VERSION ""

NS_ :

BS_:

BU_: AMP BCM DCSD DIAG_TEST DTV ECC EMCM ETM HCPM IPC LSMD LSMP LTM RRM TBM

BO_ 1985 ARCH_INFO: 4 BCM
 SG_ VehicleArchitectureInfo : 7|5@0+ (1,0) [0|31] "" ETM

BO_ 1884 BCM_IGNITION_ON_COUNTER: 2 BCM
 SG_ IgnitionOnCounter : 7|16@0+ (1,0) [0|65535] "-" AMP,DCSD,ECC,EMCM,ETM,HCPM,LSMD,LSMP,LTM,TBM

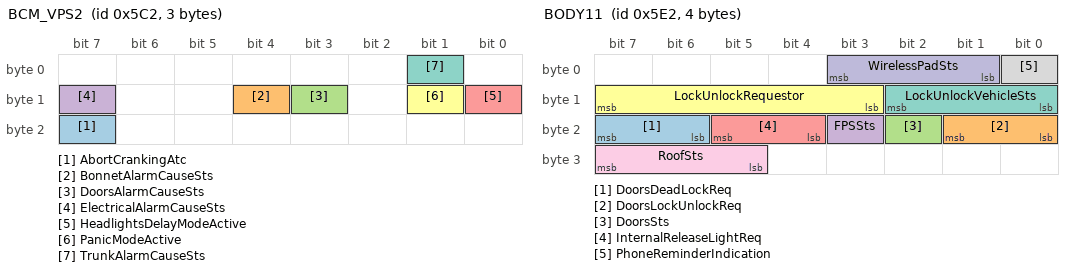
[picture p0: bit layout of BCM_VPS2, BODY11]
BO_ 1474 BCM_VPS2: 3 BCM
 SG_ AbortCrankingAtc : 23|1@0+ (1,0) [0|1] "-" TBM
 SG_ BonnetAlarmCauseSts : 12|1@0+ (1,0) [0|1] "-" IPC
 SG_ DoorsAlarmCauseSts : 11|1@0+ (1,0) [0|1] "-" IPC
 SG_ ElectricalAlarmCauseSts : 15|1@0+ (1,0) [0|1] "-" IPC
 SG_ HeadlightsDelayModeActive : 8|1@0+ (1,0) [0|1] "-" TBM
 SG_ PanicModeActive : 9|1@0+ (1,0) [0|1] "-" TBM
 SG_ TrunkAlarmCauseSts : 1|1@0+ (1,0) [0|1] "-" IPC

BO_ 1506 BODY11: 4 BCM
 SG_ DoorsDeadLockReq : 23|2@0+ (1,0) [0|3] "-" LSMD,LSMP
 SG_ DoorsLockUnlockReq : 17|2@0+ (1,0) [0|3] "-" LSMD,LSMP
 SG_ DoorsSts : 18|1@0+ (1,0) [0|1] "-" LSMD,LSMP
 SG_ FPSSts : 19|1@0+ (1,0) [0|1] "-" LSMD,LSMP
 SG_ InternalReleaseLightReq : 21|2@0+ (1,0) [0|3] "-" LSMD,LSMP
 SG_ LockUnlockRequestor : 15|5@0+ (1,0) [0|31] "-" LSMD,LSMP
 SG_ LockUnlockVehicleSts : 10|3@0+ (1,0) [0|7] "-" TBM
 SG_ PhoneReminderIndication : 0|1@0+ (1,0) [0|1] "-" IPC
 SG_ RoofSts : 31|3@0+ (1,0) [0|7] "-" ECC,TBM
 SG_ WirelessPadSts : 3|3@0+ (1,0) [0|6] "-" Vector__XXX

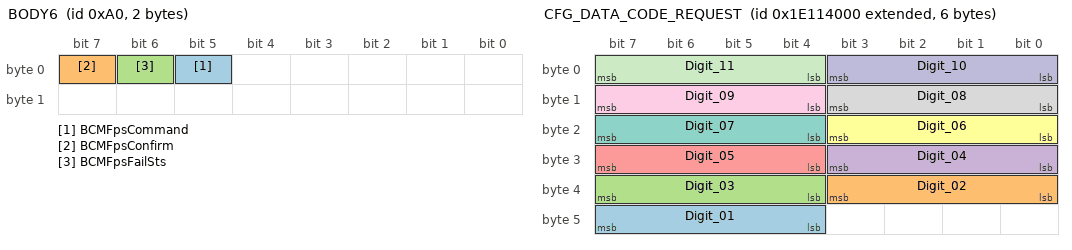
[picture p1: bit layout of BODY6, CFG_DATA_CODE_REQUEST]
BO_ 160 BODY6: 2 BCM
 SG_ BCMFpsCommand : 5|1@0+ (1,0) [0|1] "-" ECC
 SG_ BCMFpsConfirm : 7|1@0+ (1,0) [0|1] "-" ECC
 SG_ BCMFpsFailSts : 6|1@0+ (1,0) [0|1] "-" ECC,LSMD,LSMP

BO_ 2651930624 CFG_DATA_CODE_REQUEST: 6 BCM
 SG_ Digit_01 : 47|4@0+ (1,0) [0|15] "" AMP,ECC,EMCM,ETM,HCPM,LSMD,LSMP,LTM
 SG_ Digit_02 : 35|4@0+ (1,0) [0|15] "" AMP,ECC,EMCM,ETM,HCPM,LSMD,LSMP,LTM
 SG_ Digit_03 : 39|4@0+ (1,0) [0|15] "" AMP,ECC,EMCM,ETM,HCPM,LSMD,LSMP,LTM
 SG_ Digit_04 : 27|4@0+ (1,0) [0|15] "" AMP,ECC,EMCM,ETM,HCPM,LSMD,LSMP,LTM
 SG_ Digit_05 : 31|4@0+ (1,0) [0|15] "" AMP,ECC,EMCM,ETM,HCPM,LSMD,LSMP,LTM
 SG_ Digit_06 : 19|4@0+ (1,0) [0|15] "" AMP,ECC,EMCM,ETM,HCPM,LSMD,LSMP,LTM
 SG_ Digit_07 : 23|4@0+ (1,0) [0|15] "" AMP,ECC,EMCM,ETM,HCPM,LSMD,LSMP,LTM
 SG_ Digit_08 : 11|4@0+ (1,0) [0|15] "" AMP,ECC,EMCM,ETM,HCPM,LSMD,LSMP,LTM
 SG_ Digit_09 : 15|4@0+ (1,0) [0|15] "" AMP,ECC,EMCM,ETM,HCPM,LSMD,LSMP,LTM
 SG_ Digit_10 : 3|4@0+ (1,0) [0|15] "" AMP,ECC,EMCM,ETM,HCPM,LSMD,LSMP,LTM
 SG_ Digit_11 : 7|4@0+ (1,0) [0|15] "" AMP,ECC,EMCM,ETM,HCPM,LSMD,LSMP,LTM

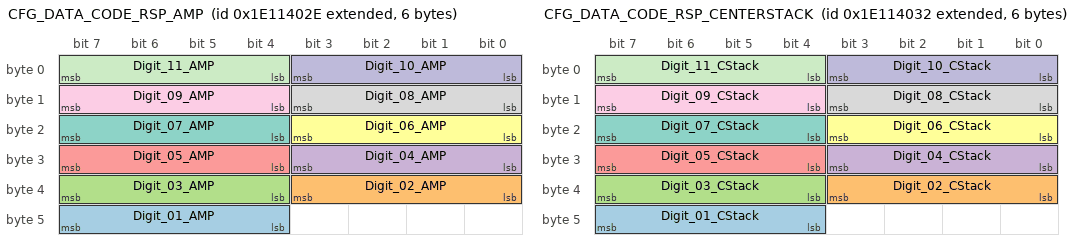
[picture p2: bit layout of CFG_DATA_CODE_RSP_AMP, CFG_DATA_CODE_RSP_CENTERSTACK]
BO_ 2651930670 CFG_DATA_CODE_RSP_AMP: 6 AMP
 SG_ Digit_01_AMP : 47|4@0+ (1,0) [0|15] "-" BCM
 SG_ Digit_02_AMP : 35|4@0+ (1,0) [0|15] "-" BCM
 SG_ Digit_03_AMP : 39|4@0+ (1,0) [0|15] "-" BCM
 SG_ Digit_04_AMP : 27|4@0+ (1,0) [0|15] "-" BCM
 SG_ Digit_05_AMP : 31|4@0+ (1,0) [0|15] "-" BCM
 SG_ Digit_06_AMP : 19|4@0+ (1,0) [0|15] "-" BCM
 SG_ Digit_07_AMP : 23|4@0+ (1,0) [0|15] "-" BCM
 SG_ Digit_08_AMP : 11|4@0+ (1,0) [0|15] "-" BCM
 SG_ Digit_09_AMP : 15|4@0+ (1,0) [0|15] "-" BCM
 SG_ Digit_10_AMP : 3|4@0+ (1,0) [0|15] "-" BCM
 SG_ Digit_11_AMP : 7|4@0+ (1,0) [0|15] "-" BCM

BO_ 2651930674 CFG_DATA_CODE_RSP_CENTERSTACK: 6 HCPM
 SG_ Digit_01_CStack : 47|4@0+ (1,0) [0|15] "-" BCM
 SG_ Digit_02_CStack : 35|4@0+ (1,0) [0|15] "-" BCM
 SG_ Digit_03_CStack : 39|4@0+ (1,0) [0|15] "-" BCM
 SG_ Digit_04_CStack : 27|4@0+ (1,0) [0|15] "-" BCM
 SG_ Digit_05_CStack : 31|4@0+ (1,0) [0|15] "-" BCM
 SG_ Digit_06_CStack : 19|4@0+ (1,0) [0|15] "-" BCM
 SG_ Digit_07_CStack : 23|4@0+ (1,0) [0|15] "-" BCM
 SG_ Digit_08_CStack : 11|4@0+ (1,0) [0|15] "-" BCM
 SG_ Digit_09_CStack : 15|4@0+ (1,0) [0|15] "-" BCM
 SG_ Digit_10_CStack : 3|4@0+ (1,0) [0|15] "-" BCM
 SG_ Digit_11_CStack : 7|4@0+ (1,0) [0|15] "-" BCM

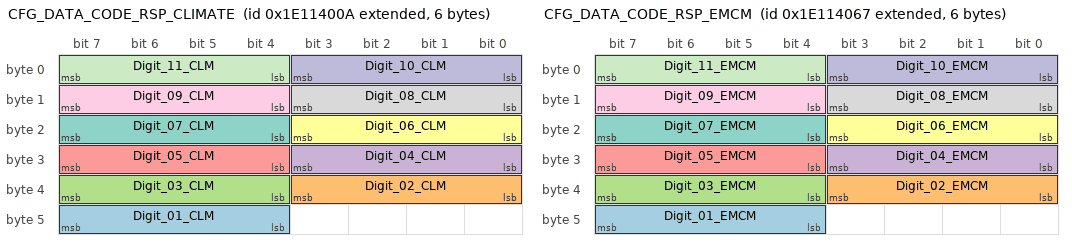
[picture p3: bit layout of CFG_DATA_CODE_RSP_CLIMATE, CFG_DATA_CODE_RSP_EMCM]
BO_ 2651930634 CFG_DATA_CODE_RSP_CLIMATE: 6 ECC
 SG_ Digit_01_CLM : 47|4@0+ (1,0) [0|15] "-" BCM
 SG_ Digit_02_CLM : 35|4@0+ (1,0) [0|15] "-" BCM
 SG_ Digit_03_CLM : 39|4@0+ (1,0) [0|15] "-" BCM
 SG_ Digit_04_CLM : 27|4@0+ (1,0) [0|15] "-" BCM
 SG_ Digit_05_CLM : 31|4@0+ (1,0) [0|15] "-" BCM
 SG_ Digit_06_CLM : 19|4@0+ (1,0) [0|15] "-" BCM
 SG_ Digit_07_CLM : 23|4@0+ (1,0) [0|15] "-" BCM
 SG_ Digit_08_CLM : 11|4@0+ (1,0) [0|15] "-" BCM
 SG_ Digit_09_CLM : 15|4@0+ (1,0) [0|15] "-" BCM
 SG_ Digit_10_CLM : 3|4@0+ (1,0) [0|15] "-" BCM
 SG_ Digit_11_CLM : 7|4@0+ (1,0) [0|15] "-" BCM

BO_ 2651930727 CFG_DATA_CODE_RSP_EMCM: 6 EMCM
 SG_ Digit_01_EMCM : 47|4@0+ (1,0) [0|15] "-" BCM
 SG_ Digit_02_EMCM : 35|4@0+ (1,0) [0|15] "-" BCM
 SG_ Digit_03_EMCM : 39|4@0+ (1,0) [0|15] "-" BCM
 SG_ Digit_04_EMCM : 27|4@0+ (1,0) [0|15] "-" BCM
 SG_ Digit_05_EMCM : 31|4@0+ (1,0) [0|15] "-" BCM
 SG_ Digit_06_EMCM : 19|4@0+ (1,0) [0|15] "-" BCM
 SG_ Digit_07_EMCM : 23|4@0+ (1,0) [0|15] "-" BCM
 SG_ Digit_08_EMCM : 11|4@0+ (1,0) [0|15] "-" BCM
 SG_ Digit_09_EMCM : 15|4@0+ (1,0) [0|15] "-" BCM
 SG_ Digit_10_EMCM : 3|4@0+ (1,0) [0|15] "-" BCM
 SG_ Digit_11_EMCM : 7|4@0+ (1,0) [0|15] "-" BCM

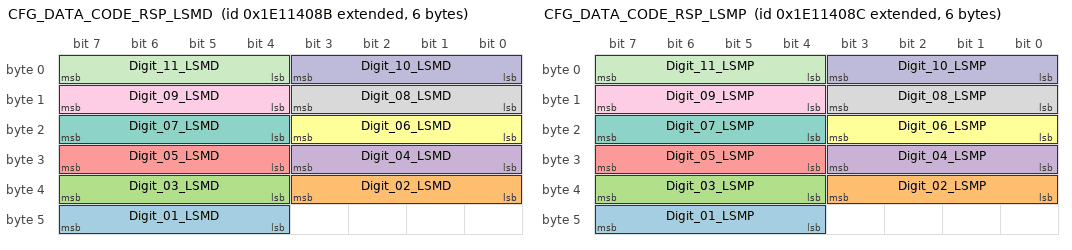
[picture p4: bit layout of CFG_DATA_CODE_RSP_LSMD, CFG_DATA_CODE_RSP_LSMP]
BO_ 2651930763 CFG_DATA_CODE_RSP_LSMD: 6 LSMD
 SG_ Digit_01_LSMD : 47|4@0+ (1,0) [0|15] "-" BCM
 SG_ Digit_02_LSMD : 35|4@0+ (1,0) [0|15] "-" BCM
 SG_ Digit_03_LSMD : 39|4@0+ (1,0) [0|15] "-" BCM
 SG_ Digit_04_LSMD : 27|4@0+ (1,0) [0|15] "-" BCM
 SG_ Digit_05_LSMD : 31|4@0+ (1,0) [0|15] "-" BCM
 SG_ Digit_06_LSMD : 19|4@0+ (1,0) [0|15] "-" BCM
 SG_ Digit_07_LSMD : 23|4@0+ (1,0) [0|15] "-" BCM
 SG_ Digit_08_LSMD : 11|4@0+ (1,0) [0|15] "-" BCM
 SG_ Digit_09_LSMD : 15|4@0+ (1,0) [0|15] "-" BCM
 SG_ Digit_10_LSMD : 3|4@0+ (1,0) [0|15] "-" BCM
 SG_ Digit_11_LSMD : 7|4@0+ (1,0) [0|15] "-" BCM

BO_ 2651930764 CFG_DATA_CODE_RSP_LSMP: 6 LSMP
 SG_ Digit_01_LSMP : 47|4@0+ (1,0) [0|15] "-" BCM
 SG_ Digit_02_LSMP : 35|4@0+ (1,0) [0|15] "-" BCM
 SG_ Digit_03_LSMP : 39|4@0+ (1,0) [0|15] "-" BCM
 SG_ Digit_04_LSMP : 27|4@0+ (1,0) [0|15] "-" BCM
 SG_ Digit_05_LSMP : 31|4@0+ (1,0) [0|15] "-" BCM
 SG_ Digit_06_LSMP : 19|4@0+ (1,0) [0|15] "-" BCM
 SG_ Digit_07_LSMP : 23|4@0+ (1,0) [0|15] "-" BCM
 SG_ Digit_08_LSMP : 11|4@0+ (1,0) [0|15] "-" BCM
 SG_ Digit_09_LSMP : 15|4@0+ (1,0) [0|15] "-" BCM
 SG_ Digit_10_LSMP : 3|4@0+ (1,0) [0|15] "-" BCM
 SG_ Digit_11_LSMP : 7|4@0+ (1,0) [0|15] "-" BCM

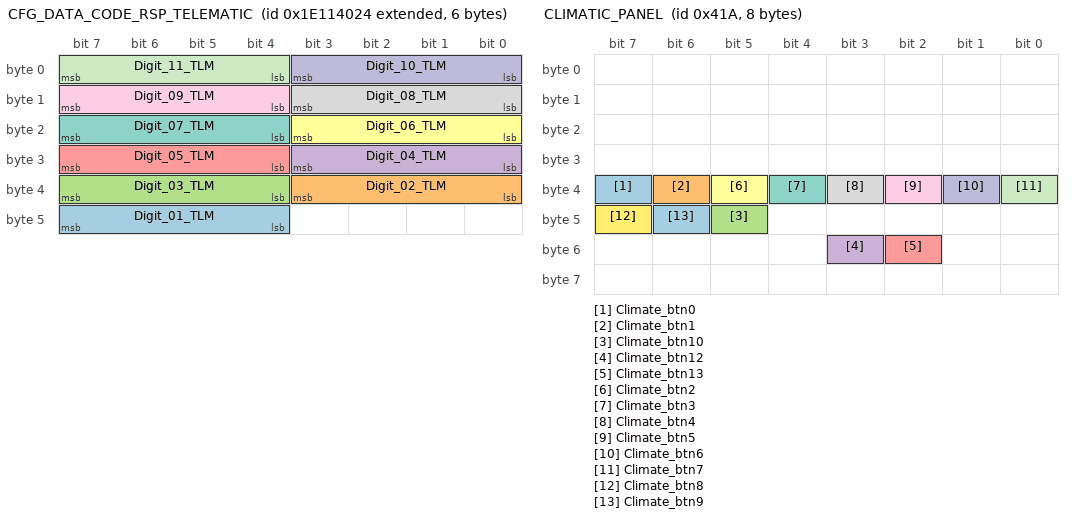
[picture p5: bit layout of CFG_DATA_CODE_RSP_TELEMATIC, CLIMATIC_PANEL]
BO_ 2651930660 CFG_DATA_CODE_RSP_TELEMATIC: 6 ETM
 SG_ Digit_01_TLM : 47|4@0+ (1,0) [0|15] "-" BCM
 SG_ Digit_02_TLM : 35|4@0+ (1,0) [0|15] "-" BCM
 SG_ Digit_03_TLM : 39|4@0+ (1,0) [0|15] "-" BCM
 SG_ Digit_04_TLM : 27|4@0+ (1,0) [0|15] "-" BCM
 SG_ Digit_05_TLM : 31|4@0+ (1,0) [0|15] "-" BCM
 SG_ Digit_06_TLM : 19|4@0+ (1,0) [0|15] "-" BCM
 SG_ Digit_07_TLM : 23|4@0+ (1,0) [0|15] "-" BCM
 SG_ Digit_08_TLM : 11|4@0+ (1,0) [0|15] "-" BCM
 SG_ Digit_09_TLM : 15|4@0+ (1,0) [0|15] "-" BCM
 SG_ Digit_10_TLM : 3|4@0+ (1,0) [0|15] "-" BCM
 SG_ Digit_11_TLM : 7|4@0+ (1,0) [0|15] "-" BCM

BO_ 134 CLIMATE_REQ: 2 ECC
 SG_ FPS_Status_Request : 7|1@0+ (1,0) [0|1] "-" BCM

BO_ 1050 CLIMATIC_PANEL: 8 HCPM
 SG_ Climate_btn0 : 39|1@0+ (1,0) [0|1] "" ECC
 SG_ Climate_btn1 : 38|1@0+ (1,0) [0|1] "" ECC
 SG_ Climate_btn10 : 45|1@0+ (1,0) [0|1] "" ECC
 SG_ Climate_btn12 : 51|1@0+ (1,0) [0|1] "" ECC
 SG_ Climate_btn13 : 50|1@0+ (1,0) [0|1] "" ECC
 SG_ Climate_btn2 : 37|1@0+ (1,0) [0|1] "" ECC
 SG_ Climate_btn3 : 36|1@0+ (1,0) [0|1] "" ECC
 SG_ Climate_btn4 : 35|1@0+ (1,0) [0|1] "" ECC
 SG_ Climate_btn5 : 34|1@0+ (1,0) [0|1] "" ECC
 SG_ Climate_btn6 : 33|1@0+ (1,0) [0|1] "" ECC
 SG_ Climate_btn7 : 32|1@0+ (1,0) [0|1] "" ECC
 SG_ Climate_btn8 : 47|1@0+ (1,0) [0|1] "" ECC
 SG_ Climate_btn9 : 46|1@0+ (1,0) [0|1] "" ECC

BO_ 224 CLUSTER5: 4 IPC
 SG_ DisplayedSpeedSign : 7|8@0+ (1,0) [0|255] "-" ETM

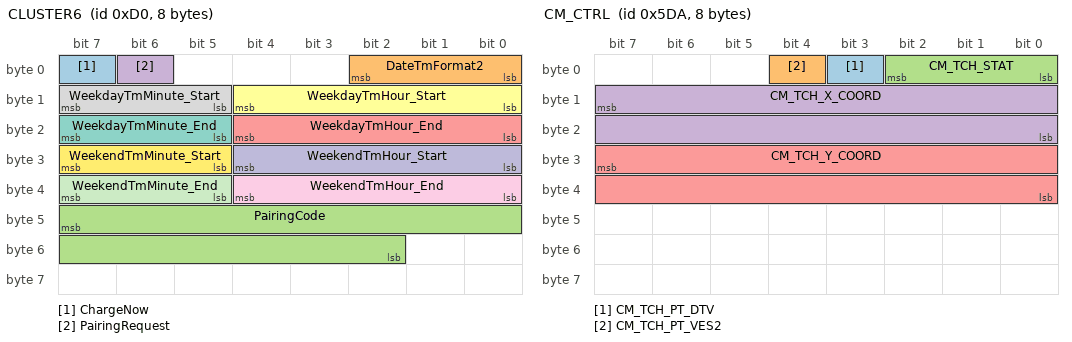
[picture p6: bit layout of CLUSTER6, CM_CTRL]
BO_ 208 CLUSTER6: 8 IPC
 SG_ ChargeNow : 7|1@0+ (1,0) [0|1] "" BCM
 SG_ DateTmFormat2 : 2|3@0+ (1,0) [0|6] "" Vector__XXX
 SG_ PairingCode : 47|14@0+ (1,0) [0|16383] "" RRM
 SG_ PairingRequest : 6|1@0+ (1,0) [0|1] "" RRM
 SG_ WeekdayTmHour_End : 20|5@0+ (1,0) [0|24] "Hours" RRM
 SG_ WeekdayTmHour_Start : 12|5@0+ (1,0) [0|24] "Hours" RRM
 SG_ WeekdayTmMinute_End : 23|3@0+ (1,0) [0|6] "Min" RRM
 SG_ WeekdayTmMinute_Start : 15|3@0+ (1,0) [0|6] "Min" RRM
 SG_ WeekendTmHour_End : 36|5@0+ (1,0) [0|24] "Hours" RRM
 SG_ WeekendTmHour_Start : 28|5@0+ (1,0) [0|24] "Hours" RRM
 SG_ WeekendTmMinute_End : 39|3@0+ (1,0) [0|6] "" RRM
 SG_ WeekendTmMinute_Start : 31|3@0+ (1,0) [0|6] "Min" RRM

BO_ 1498 CM_CTRL: 8 ETM
 SG_ CM_TCH_PT_DTV : 3|1@0+ (1,0) [0|1] "" DTV
 SG_ CM_TCH_PT_VES2 : 4|1@0+ (1,0) [0|1] "" Vector__XXX
 SG_ CM_TCH_STAT : 2|3@0+ (1,0) [0|6] "" DTV
 SG_ CM_TCH_X_COORD : 15|16@0+ (1,0) [0|65535] "" DTV
 SG_ CM_TCH_Y_COORD : 31|16@0+ (1,0) [0|65535] "" DTV

BO_ 177 CONNECTIVITY_VEHICLE_SETUP2: 8 TBM
 SG_ PowerLevel_External_Req : 7|3@0+ (1,0) [0|7] "-" IPC
 SG_ RemStNrmlStEnbl_External_Req : 4|2@0+ (1,0) [0|3] "-" IPC

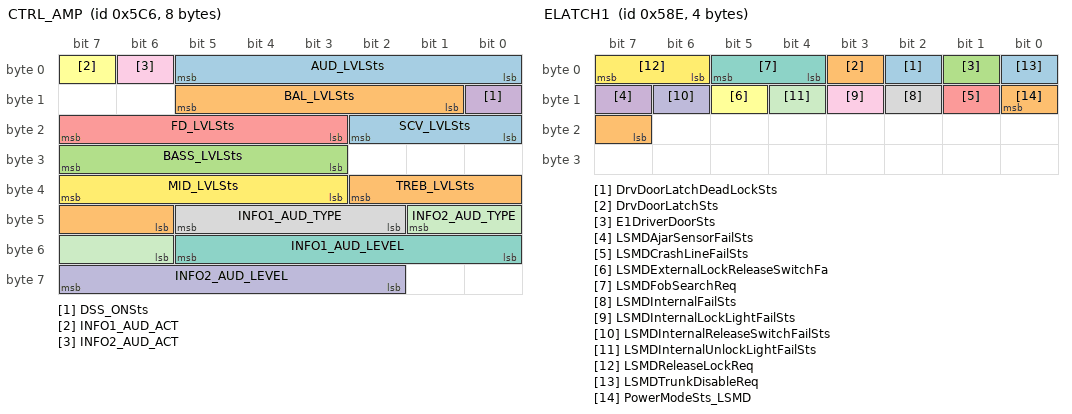
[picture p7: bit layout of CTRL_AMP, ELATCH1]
BO_ 1478 CTRL_AMP: 8 ETM
 SG_ AUD_LVLSts : 5|6@0+ (1,0) [0|63] "" AMP,TBM
 SG_ BAL_LVLSts : 13|5@0+ (1,0) [0|31] "" AMP
 SG_ BASS_LVLSts : 31|5@0+ (1,0) [0|31] "" AMP
 SG_ DSS_ONSts : 8|1@0+ (1,0) [0|1] "" AMP
 SG_ FD_LVLSts : 23|5@0+ (1,0) [0|31] "" AMP
 SG_ INFO1_AUD_ACT : 7|1@0+ (1,0) [0|1] "" AMP
 SG_ INFO1_AUD_LEVEL : 53|6@0+ (1,0) [0|63] "" AMP,TBM
 SG_ INFO1_AUD_TYPE : 45|4@0+ (1,0) [0|15] "" AMP
 SG_ INFO2_AUD_ACT : 6|1@0+ (1,0) [0|1] "" AMP
 SG_ INFO2_AUD_LEVEL : 63|6@0+ (1,0) [0|63] "" AMP,TBM
 SG_ INFO2_AUD_TYPE : 41|4@0+ (1,0) [0|15] "" AMP
 SG_ MID_LVLSts : 39|5@0+ (1,0) [0|31] "" AMP
 SG_ SCV_LVLSts : 18|3@0+ (1,0) [0|6] "" AMP
 SG_ TREB_LVLSts : 34|5@0+ (1,0) [0|31] "" AMP

BO_ 2564554481 DIAGNOSTIC_REQ_FUNC_BH_C2: 8 DIAG_TEST
 SG_ N_PDU : 7|64@0+ (1,0) [0|0] "" AMP,BCM,DCSD,ECC,EMCM,ETM,HCPM,LSMD,LSMP,LTM

BO_ 2564457457 DIAGNOSTIC_REQUEST_AMP: 8 BCM
 SG_ N_PDU : 7|64@0+ (1,0) [0|0] "" AMP,TBM

BO_ 2564457969 DIAGNOSTIC_REQUEST_CENTERSTACK: 8 BCM
 SG_ N_PDU : 7|64@0+ (1,0) [0|0] "" HCPM,TBM

BO_ 2564462833 DIAGNOSTIC_REQUEST_CLIMATE: 8 BCM
 SG_ N_PDU : 7|64@0+ (1,0) [0|0] "" ECC,TBM

BO_ 2564451057 DIAGNOSTIC_REQUEST_DCSD: 8 BCM
 SG_ N_PDU : 7|64@0+ (1,0) [0|0] "" DCSD,TBM

BO_ 2564479473 DIAGNOSTIC_REQUEST_EMCM: 8 BCM
 SG_ N_PDU : 7|64@0+ (1,0) [0|0] "" EMCM,TBM

BO_ 2564445425 DIAGNOSTIC_REQUEST_LSMD: 8 BCM
 SG_ N_PDU : 7|64@0+ (1,0) [0|0] "" LSMD,TBM

BO_ 2564445681 DIAGNOSTIC_REQUEST_LSMP: 8 BCM
 SG_ N_PDU : 7|64@0+ (1,0) [0|0] "" LSMP,TBM

BO_ 2564458481 DIAGNOSTIC_REQUEST_TELEMATIC: 8 BCM
 SG_ N_PDU : 7|64@0+ (1,0) [0|0] "" ETM,LTM,TBM

BO_ 2564485507 DIAGNOSTIC_RESPONSE_AMP: 8 AMP
 SG_ N_PDU : 7|64@0+ (1,0) [0|0] "-" BCM,DIAG_TEST,TBM

BO_ 2564485509 DIAGNOSTIC_RESPONSE_CENTERSTACK: 8 HCPM
 SG_ N_PDU : 7|64@0+ (1,0) [0|0] "-" BCM,DIAG_TEST,TBM

BO_ 2564485528 DIAGNOSTIC_RESPONSE_CLIMATE: 8 ECC
 SG_ N_PDU : 7|64@0+ (1,0) [0|0] "" BCM,DIAG_TEST,TBM

BO_ 2564485482 DIAGNOSTIC_RESPONSE_DCSD: 8 DCSD
 SG_ N_PDU : 7|64@0+ (1,0) [0|0] "-" BCM,DIAG_TEST,TBM

BO_ 2564485593 DIAGNOSTIC_RESPONSE_EMCM: 8 EMCM
 SG_ N_PDU : 7|64@0+ (1,0) [0|0] "-" BCM,DIAG_TEST,TBM

BO_ 2564485460 DIAGNOSTIC_RESPONSE_LSMD: 8 LSMD
 SG_ N_PDU : 7|64@0+ (1,0) [0|0] "" BCM,DIAG_TEST,TBM

BO_ 2564485461 DIAGNOSTIC_RESPONSE_LSMP: 8 LSMP
 SG_ N_PDU : 7|64@0+ (1,0) [0|0] "" BCM,DIAG_TEST,TBM

BO_ 2564485511 DIAGNOSTIC_RESPONSE_TELEMATIC: 8 ETM
 SG_ N_PDU : 7|64@0+ (1,0) [0|0] "" BCM,DIAG_TEST,TBM

BO_ 1445 DIS_CENTERSTACK: 8 DCSD
 SG_ DCSD_DISP_STAT : 7|3@0+ (1,0) [0|6] "" ETM,LTM

BO_ 1422 ELATCH1: 4 LSMD
 SG_ DrvDoorLatchDeadLockSts : 2|1@0+ (1,0) [0|1] "" BCM
 SG_ DrvDoorLatchSts : 3|1@0+ (1,0) [0|1] "" BCM,TBM
 SG_ E1DriverDoorSts : 1|1@0+ (1,0) [0|1] "" BCM,ECC,ETM,IPC,LTM,RRM,TBM
 SG_ LSMDAjarSensorFailSts : 15|1@0+ (1,0) [0|1] "" BCM,ECC,IPC,TBM
 SG_ LSMDCrashLineFailSts : 9|1@0+ (1,0) [0|1] "" BCM,IPC
 SG_ LSMDExternalLockReleaseSwitchFa : 13|1@0+ (1,0) [0|1] "" BCM
 SG_ LSMDFobSearchReq : 5|2@0+ (1,0) [0|3] "" BCM
 SG_ LSMDInternalFailSts : 10|1@0+ (1,0) [0|1] "" BCM,ECC,IPC,TBM
 SG_ LSMDInternalLockLightFailSts : 11|1@0+ (1,0) [0|1] "" BCM
 SG_ LSMDInternalReleaseSwitchFailSts : 14|1@0+ (1,0) [0|1] "" BCM
 SG_ LSMDInternalUnlockLightFailSts : 12|1@0+ (1,0) [0|1] "" BCM
 SG_ LSMDReleaseLockReq : 7|2@0+ (1,0) [0|3] "" BCM
 SG_ LSMDTrunkDisableReq : 0|1@0+ (1,0) [0|1] "" BCM
 SG_ PowerModeSts_LSMD : 8|2@0+ (1,0) [0|3] "" BCM

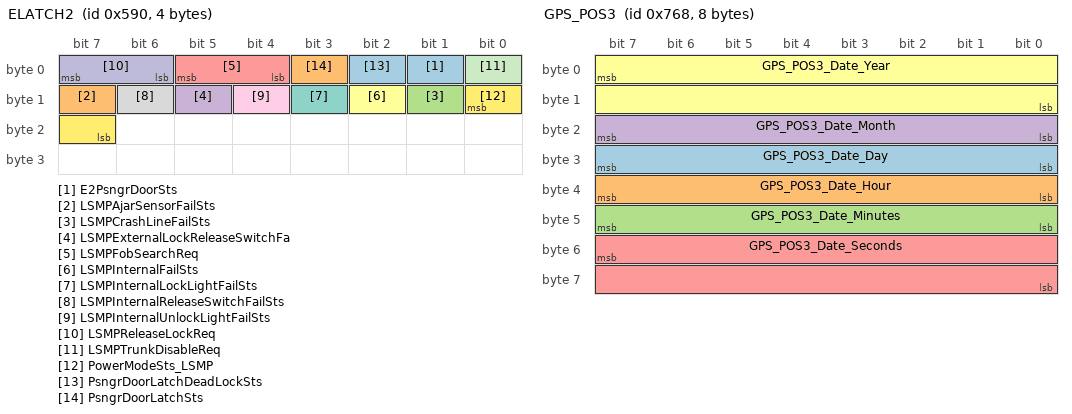
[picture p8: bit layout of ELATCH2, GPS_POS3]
BO_ 1424 ELATCH2: 4 LSMP
 SG_ E2PsngrDoorSts : 1|1@0+ (1,0) [0|1] "" BCM,ECC,ETM,IPC,LTM,RRM,TBM
 SG_ LSMPAjarSensorFailSts : 15|1@0+ (1,0) [0|1] "" BCM,ECC,IPC,TBM
 SG_ LSMPCrashLineFailSts : 9|1@0+ (1,0) [0|1] "" BCM,IPC
 SG_ LSMPExternalLockReleaseSwitchFa : 13|1@0+ (1,0) [0|1] "" BCM
 SG_ LSMPFobSearchReq : 5|2@0+ (1,0) [0|3] "" BCM
 SG_ LSMPInternalFailSts : 10|1@0+ (1,0) [0|1] "" BCM,ECC,IPC,TBM
 SG_ LSMPInternalLockLightFailSts : 11|1@0+ (1,0) [0|1] "" BCM
 SG_ LSMPInternalReleaseSwitchFailSts : 14|1@0+ (1,0) [0|1] "" BCM
 SG_ LSMPInternalUnlockLightFailSts : 12|1@0+ (1,0) [0|1] "" BCM
 SG_ LSMPReleaseLockReq : 7|2@0+ (1,0) [0|3] "" BCM
 SG_ LSMPTrunkDisableReq : 0|1@0+ (1,0) [0|1] "" BCM
 SG_ PowerModeSts_LSMP : 8|2@0+ (1,0) [0|3] "" BCM
 SG_ PsngrDoorLatchDeadLockSts : 2|1@0+ (1,0) [0|1] "" BCM
 SG_ PsngrDoorLatchSts : 3|1@0+ (1,0) [0|1] "" BCM,TBM

BO_ 852 EXTERNAL_LIGHTS: 4 BCM
 SG_ AHBFeature : 19|1@0+ (1,0) [0|1] "-" IPC
 SG_ AlertLightsON : 31|1@0+ (1,0) [0|1] "-" IPC
 SG_ DRLFault : 6|1@0+ (1,0) [0|1] "-" IPC,TBM
 SG_ FHeatedWindowSts : 5|1@0+ (1,0) [0|1] "-" ECC
 SG_ FollowMeHomeReqSts : 28|1@0+ (1,0) [0|1] "-" IPC
 SG_ FrontFogLightSts : 4|1@0+ (1,0) [0|1] "-" IPC,RRM,TBM
 SG_ HeatedMirrorSts : 3|1@0+ (1,0) [0|1] "-" TBM
 SG_ HighBeamSts : 2|1@0+ (1,0) [0|1] "-" IPC
 SG_ L_TurnLightActivationSts : 17|1@0+ (1,0) [0|1] "-" Vector__XXX
 SG_ LHParkingLightSts : 1|1@0+ (1,0) [0|1] "-" ETM,IPC,LTM
 SG_ LHTurnLightFault : 0|1@0+ (1,0) [0|1] "-" IPC,TBM
 SG_ LHTurnSignalSts : 15|1@0+ (1,0) [0|1] "-" IPC,TBM
 SG_ LowBeamSts : 14|1@0+ (1,0) [0|1] "-" ETM,IPC,LTM
 SG_ ParkingLightFault : 13|1@0+ (1,0) [0|1] "-" IPC
 SG_ PlateLightFault : 12|1@0+ (1,0) [0|1] "-" IPC,TBM
 SG_ R_TurnLightActivationSts : 16|1@0+ (1,0) [0|1] "-" Vector__XXX
 SG_ RearFogLightFault : 11|1@0+ (1,0) [0|1] "-" IPC
 SG_ RearFogLightSts : 10|1@0+ (1,0) [0|1] "-" IPC,TBM
 SG_ ReverseGearLightFault : 9|1@0+ (1,0) [0|1] "-" IPC,TBM
 SG_ RHeatedWindowSts : 8|1@0+ (1,0) [0|1] "-" ECC,TBM
 SG_ RHParkingLightSts : 23|1@0+ (1,0) [0|1] "-" ETM,IPC,LTM
 SG_ RHTurnLightFault : 22|1@0+ (1,0) [0|1] "-" IPC,TBM
 SG_ RHTurnSignalSts : 21|1@0+ (1,0) [0|1] "-" IPC,TBM
 SG_ StopLightFault : 20|1@0+ (1,0) [0|1] "-" IPC,TBM
 SG_ StopLightSts : 18|1@0+ (1,0) [0|1] "-" Vector__XXX

BO_ 128 FOTA_TBM: 4 TBM
 SG_ UpdateSts : 7|3@0+ (1,0) [0|7] "" BCM,ETM,IPC,LTM

BO_ 1896 GPS_POS3: 8 ETM
 SG_ GPS_POS3_Date_Day : 31|8@0+ (1,0) [1|31] "days" BCM
 SG_ GPS_POS3_Date_Hour : 39|8@0+ (1,0) [0|23] "hours" BCM
 SG_ GPS_POS3_Date_Minutes : 47|8@0+ (1,0) [0|59] "minutes" BCM
 SG_ GPS_POS3_Date_Month : 23|8@0+ (1,0) [1|12] "months" BCM
 SG_ GPS_POS3_Date_Seconds : 55|16@0+ (0.01,0) [0|59.99] "seconds" BCM
 SG_ GPS_POS3_Date_Year : 7|16@0+ (1,0) [0|65534] "years" BCM

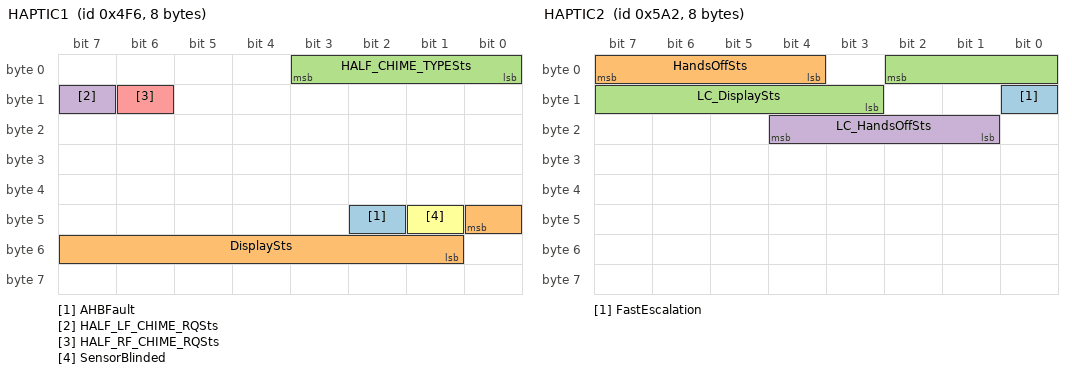
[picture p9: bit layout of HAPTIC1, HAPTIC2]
BO_ 1270 HAPTIC1: 8 BCM
 SG_ AHBFault : 42|1@0+ (1,0) [0|1] "" IPC
 SG_ DisplaySts : 40|8@0+ (1,0) [0|255] "-" IPC,TBM
 SG_ HALF_CHIME_TYPESts : 3|4@0+ (1,0) [0|15] "-" AMP,ETM,LTM,TBM
 SG_ HALF_LF_CHIME_RQSts : 15|1@0+ (1,0) [0|1] "-" AMP,ETM,LTM,TBM
 SG_ HALF_RF_CHIME_RQSts : 14|1@0+ (1,0) [0|1] "-" AMP,ETM,LTM,TBM
 SG_ SensorBlinded : 41|1@0+ (1,0) [0|1] "" IPC

BO_ 1442 HAPTIC2: 8 BCM
 SG_ FastEscalation : 8|1@0+ (1,0) [0|1] "-" IPC
 SG_ HandsOffSts : 7|4@0+ (1,0) [0|15] "-" IPC
 SG_ LC_DisplaySts : 2|8@0+ (1,0) [0|255] "-" IPC
 SG_ LC_HandsOffSts : 20|4@0+ (1,0) [0|15] "-" IPC

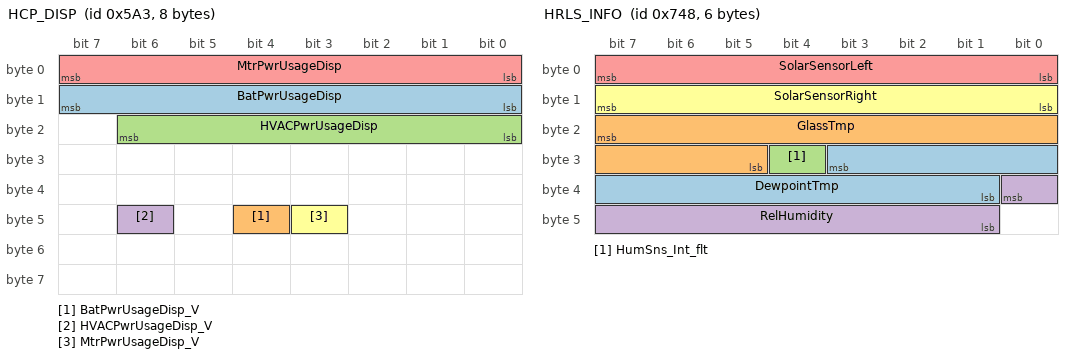
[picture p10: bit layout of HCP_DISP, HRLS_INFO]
BO_ 1443 HCP_DISP: 8 BCM
 SG_ BatPwrUsageDisp : 15|8@0+ (1,-125) [-125|130] "kW" RRM
 SG_ BatPwrUsageDisp_V : 44|1@0+ (1,0) [0|1] "" RRM
 SG_ HVACPwrUsageDisp : 22|7@0+ (1,0) [0|127] "kW" RRM
 SG_ HVACPwrUsageDisp_V : 46|1@0+ (1,0) [0|1] "" RRM
 SG_ MtrPwrUsageDisp : 7|8@0+ (1,-125) [-125|130] "kW" RRM
 SG_ MtrPwrUsageDisp_V : 43|1@0+ (1,0) [0|1] "" RRM

BO_ 2147583473 HP_DIAGNOSTIC_REQST_CNTRSTCK: 8 BCM
 SG_ N_PDU : 7|64@0+ (1,0) [0|0] "" HCPM

BO_ 2147582961 HP_DIAGNOSTIC_REQUEST_AMP: 8 BCM
 SG_ N_PDU : 7|64@0+ (1,0) [0|0] "" AMP

BO_ 2147588337 HP_DIAGNOSTIC_REQUEST_CLIMATE: 8 BCM
 SG_ N_PDU : 7|64@0+ (1,0) [0|0] "" ECC

BO_ 2147576561 HP_DIAGNOSTIC_REQUEST_DCSD: 8 BCM
 SG_ N_PDU : 7|64@0+ (1,0) [0|0] "" DCSD

BO_ 2147584753 HP_DIAGNOSTIC_REQUEST_EMCM: 8 BCM
 SG_ N_PDU : 7|64@0+ (1,0) [0|0] "" EMCM

BO_ 2147570929 HP_DIAGNOSTIC_REQUEST_LSMD: 8 BCM
 SG_ N_PDU : 7|64@0+ (1,0) [0|0] "" LSMD

BO_ 2147571185 HP_DIAGNOSTIC_REQUEST_LSMP: 8 BCM
 SG_ N_PDU : 7|64@0+ (1,0) [0|0] "" LSMP

BO_ 2147583985 HP_DIAGNOSTIC_REQUEST_TELEMATIC: 8 BCM
 SG_ N_PDU : 7|64@0+ (1,0) [0|0] "" LTM

BO_ 1864 HRLS_INFO: 6 BCM
 SG_ DewpointTmp : 27|11@0+ (0.1,-40) [-40|164.6] "°C" ECC
 SG_ GlassTmp : 23|11@0+ (0.1,-40) [-40|164.6] "°C" ECC
 SG_ HumSns_Int_flt : 28|1@0+ (1,0) [0|1] "-" ECC
 SG_ RelHumidity : 32|8@0+ (0.5,0) [0|127] "%" ECC
 SG_ SolarSensorLeft : 7|8@0+ (5,0) [0|1275] "W/m2" ECC
 SG_ SolarSensorRight : 15|8@0+ (5,0) [0|1275] "W/m2" ECC

BO_ 142 HU_ACK: 2 ETM
 SG_ ConnectedDevices : 7|1@0+ (1,0) [0|1] "-" TBM
 SG_ SSID : 5|1@0+ (1,0) [0|1] "-" TBM

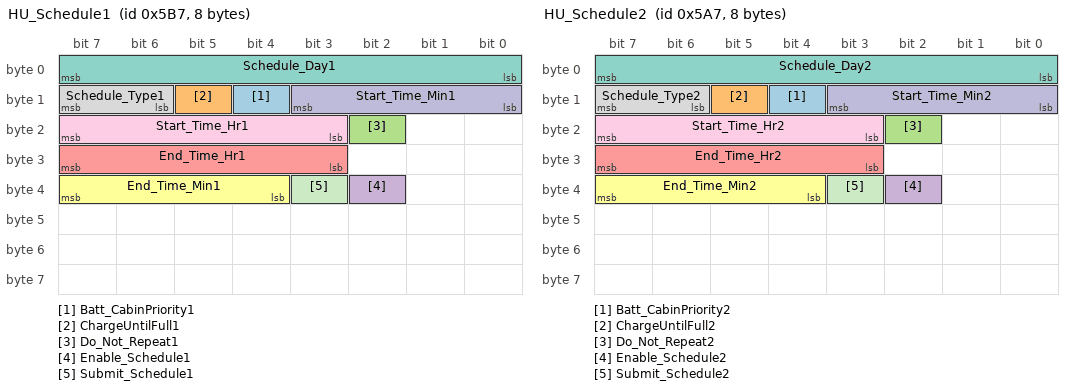
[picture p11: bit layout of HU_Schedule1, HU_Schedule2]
BO_ 1463 HU_Schedule1: 8 ETM
 SG_ Batt_CabinPriority1 : 12|1@0+ (1,0) [0|1] "-" BCM,TBM
 SG_ ChargeUntilFull1 : 13|1@0+ (1,0) [0|1] "-" BCM,TBM
 SG_ Do_Not_Repeat1 : 18|1@0+ (1,0) [0|1] "-" BCM,TBM
 SG_ Enable_Schedule1 : 34|1@0+ (1,0) [0|1] "-" BCM,TBM
 SG_ End_Time_Hr1 : 31|5@0+ (1,0) [0|23] "Hours" BCM,TBM
 SG_ End_Time_Min1 : 39|4@0+ (5,0) [0|55] "min" BCM,TBM
 SG_ Schedule_Day1 : 7|8@0+ (1,0) [0|255] "-" BCM,TBM
 SG_ Schedule_Type1 : 15|2@0+ (1,0) [0|3] "-" BCM,TBM
 SG_ Start_Time_Hr1 : 23|5@0+ (1,0) [0|23] "Hours" BCM,TBM
 SG_ Start_Time_Min1 : 11|4@0+ (5,0) [0|55] "min" BCM,TBM
 SG_ Submit_Schedule1 : 35|1@0+ (1,0) [0|1] "-" BCM

BO_ 1447 HU_Schedule2: 8 ETM
 SG_ Batt_CabinPriority2 : 12|1@0+ (1,0) [0|1] "-" BCM,TBM
 SG_ ChargeUntilFull2 : 13|1@0+ (1,0) [0|1] "-" BCM,TBM
 SG_ Do_Not_Repeat2 : 18|1@0+ (1,0) [0|1] "-" BCM,TBM
 SG_ Enable_Schedule2 : 34|1@0+ (1,0) [0|1] "-" BCM,TBM
 SG_ End_Time_Hr2 : 31|5@0+ (1,0) [0|23] "Hours" BCM,TBM
 SG_ End_Time_Min2 : 39|4@0+ (5,0) [0|55] "min" BCM,TBM
 SG_ Schedule_Day2 : 7|8@0+ (1,0) [0|255] "-" BCM,TBM
 SG_ Schedule_Type2 : 15|2@0+ (1,0) [0|3] "-" BCM,TBM
 SG_ Start_Time_Hr2 : 23|5@0+ (1,0) [0|23] "Hours" BCM,TBM
 SG_ Start_Time_Min2 : 11|4@0+ (5,0) [0|55] "min" BCM,TBM
 SG_ Submit_Schedule2 : 35|1@0+ (1,0) [0|1] "-" BCM

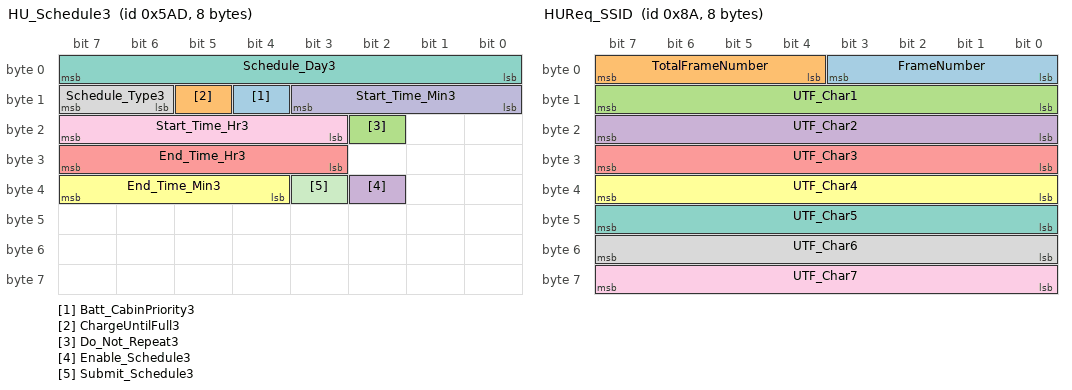
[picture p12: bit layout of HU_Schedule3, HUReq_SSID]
BO_ 1453 HU_Schedule3: 8 ETM
 SG_ Batt_CabinPriority3 : 12|1@0+ (1,0) [0|1] "-" BCM,TBM
 SG_ ChargeUntilFull3 : 13|1@0+ (1,0) [0|1] "-" BCM,TBM
 SG_ Do_Not_Repeat3 : 18|1@0+ (1,0) [0|1] "-" BCM,TBM
 SG_ Enable_Schedule3 : 34|1@0+ (1,0) [0|1] "-" BCM,TBM
 SG_ End_Time_Hr3 : 31|5@0+ (1,0) [0|23] "Hours" BCM,TBM
 SG_ End_Time_Min3 : 39|4@0+ (5,0) [0|55] "min" BCM,TBM
 SG_ Schedule_Day3 : 7|8@0+ (1,0) [0|255] "-" BCM,TBM
 SG_ Schedule_Type3 : 15|2@0+ (1,0) [0|3] "-" BCM,TBM
 SG_ Start_Time_Hr3 : 23|5@0+ (1,0) [0|23] "Hours" BCM,TBM
 SG_ Start_Time_Min3 : 11|4@0+ (5,0) [0|55] "min" BCM,TBM
 SG_ Submit_Schedule3 : 35|1@0+ (1,0) [0|1] "-" BCM

BO_ 138 HUReq_SSID: 8 ETM
 SG_ FrameNumber : 3|4@0+ (1,0) [0|15] "-" TBM
 SG_ TotalFrameNumber : 7|4@0+ (1,0) [0|15] "-" TBM
 SG_ UTF_Char1 : 15|8@0+ (1,0) [0|255] "-" TBM
 SG_ UTF_Char2 : 23|8@0+ (1,0) [0|255] "-" TBM
 SG_ UTF_Char3 : 31|8@0+ (1,0) [0|255] "-" TBM
 SG_ UTF_Char4 : 39|8@0+ (1,0) [0|255] "-" TBM
 SG_ UTF_Char5 : 47|8@0+ (1,0) [0|255] "-" TBM
 SG_ UTF_Char6 : 55|8@0+ (1,0) [0|255] "-" TBM
 SG_ UTF_Char7 : 63|8@0+ (1,0) [0|255] "-" TBM

BO_ 986 IPC_ACK: 1 IPC
 SG_ DisplayInfoReceptionSts : 7|1@0+ (1,0) [0|1] "-" ETM,LTM

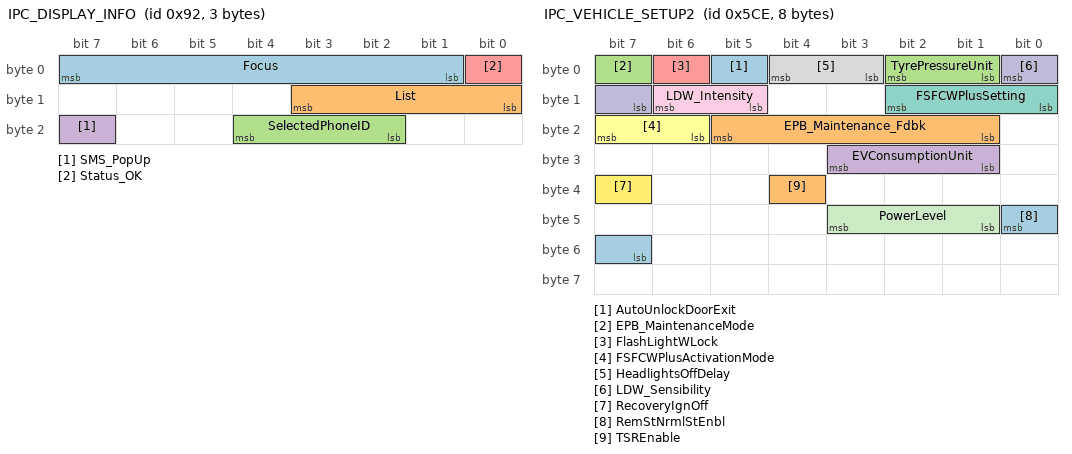
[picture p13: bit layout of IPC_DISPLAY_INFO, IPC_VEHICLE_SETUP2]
BO_ 146 IPC_DISPLAY_INFO: 3 IPC
 SG_ Focus : 7|7@0+ (1,0) [0|127] "-" ETM,LTM
 SG_ List : 11|4@0+ (1,0) [0|15] "" ETM,LTM
 SG_ SelectedPhoneID : 20|3@0+ (1,0) [0|6] "" ETM,LTM
 SG_ SMS_PopUp : 23|1@0+ (1,0) [0|1] "-" ETM
 SG_ Status_OK : 0|1@0+ (1,0) [0|1] "-" ETM,LTM

BO_ 1468 IPC_VEHICLE_SETUP: 8 IPC
 SG_ AudioRepetition : 46|1@0+ (1,0) [0|1] "" ETM,LTM
 SG_ AutoHighBeamEnable : 21|1@0+ (1,0) [0|1] "-" BCM,ETM,LTM,TBM
 SG_ AutoParkBrake : 47|1@0+ (1,0) [0|1] "" ETM,LTM,TBM
 SG_ BackLightLevel : 60|3@0+ (1,0) [0|7] "" Vector__XXX
 SG_ BSDEnable : 30|2@0+ (1,0) [0|3] "" BCM,ETM,LTM,TBM
 SG_ CorneringEnable : 18|1@0+ (1,0) [0|1] "-" BCM,ETM,LTM,RRM,TBM
 SG_ DistanceUnit : 10|1@0+ (1,0) [0|1] "-" ETM,LTM,RRM,TBM
 SG_ DRLEnable : 12|1@0+ (1,0) [0|1] "-" BCM,ETM,LTM,TBM
 SG_ ExternalLightSensorLevel : 9|2@0+ (1,0) [0|3] "-" BCM,ETM,LTM,TBM
 SG_ HourMode : 23|1@0+ (1,0) [0|1] "-" ETM,LTM
 SG_ LanguageSelection : 7|8@0+ (1,0) [0|255] "-" ETM,LTM,TBM
 SG_ NavRepetition : 50|1@0+ (1,0) [0|1] "" ETM,LTM
 SG_ PamAlertMode : 43|2@0+ (1,0) [0|3] "-" AMP,BCM,ETM,LTM
 SG_ PamChimeVolumeFront : 45|2@0+ (1,0) [0|3] "" AMP,ETM,LTM,TBM
 SG_ PamChimeVolumeRear : 41|2@0+ (1,0) [0|3] "" AMP,ETM,LTM,RRM,TBM
 SG_ PassiveEntry : 28|1@0+ (1,0) [0|1] "" BCM,ETM,LSMD,LSMP,LTM,TBM
 SG_ PhoneRepetition : 49|1@0+ (1,0) [0|1] "" ETM,LTM
 SG_ RainSensorLevel : 22|1@0+ (1,0) [0|1] "-" BCM,ETM,LTM,TBM
 SG_ RemoteDoorUnlock : 32|1@0+ (1,0) [0|1] "" BCM,ETM,LTM
 SG_ Sdw : 55|2@0+ (1,0) [0|3] "-" AMP,BCM,ETM,LTM
 SG_ SoundHornLock : 35|2@0+ (1,0) [0|3] "" BCM,ETM,LTM,TBM
 SG_ SoundHornRemoteStart : 33|1@0+ (1,0) [0|1] "" ETM,LTM,TBM
 SG_ SpeedLockDoorEnable : 20|1@0+ (1,0) [0|1] "-" BCM,ETM,LTM,TBM
 SG_ TelematicSetupACK : 16|2@0+ (1,0) [0|3] "-" ETM,LTM
 SG_ TemperatureUnit : 19|1@0+ (1,0) [0|1] "-" ECC,ETM,HCPM,LTM,RRM

BO_ 1486 IPC_VEHICLE_SETUP2: 8 IPC
 SG_ AutoUnlockDoorExit : 5|1@0+ (1,0) [0|1] "-" BCM,ETM,LTM
 SG_ EPB_Maintenance_Fdbk : 21|5@0+ (1,0) [0|31] "-" ETM,LTM
 SG_ EPB_MaintenanceMode : 7|1@0+ (1,0) [0|1] "-" ETM,LTM,TBM
 SG_ EVConsumptionUnit : 27|3@0+ (1,0) [0|7] "" ETM,LTM,TBM
 SG_ FlashLightWLock : 6|1@0+ (1,0) [0|1] "-" BCM,ETM,LTM
 SG_ FSFCWPlusActivationMode : 23|2@0+ (1,0) [0|3] "-" ETM,LTM
 SG_ FSFCWPlusSetting : 10|3@0+ (1,0) [0|7] "-" ETM,LTM,TBM
 SG_ HeadlightsOffDelay : 4|2@0+ (1,0) [0|3] "-" BCM,ETM,LTM
 SG_ LDW_Intensity : 14|2@0+ (1,0) [0|3] "-" BCM,ETM,LTM,TBM
 SG_ LDW_Sensibility : 0|2@0+ (1,0) [0|3] "-" BCM,ETM,LTM
 SG_ PowerLevel : 43|3@0+ (1,0) [0|7] "" ETM,LTM,TBM
 SG_ RecoveryIgnOff : 39|1@0+ (1,0) [0|1] "" BCM
 SG_ RemStNrmlStEnbl : 40|2@0+ (1,0) [0|3] "-" ECC,ETM,LTM,TBM
 SG_ TSREnable : 36|1@0+ (1,0) [0|1] "" BCM,ETM,LTM
 SG_ TyrePressureUnit : 2|2@0+ (1,0) [0|3] "-" ETM,LTM,TBM

BO_ 1294 IPC_VEHICLE_SETUP3: 8 IPC
 SG_ AutoHold : 58|1@0+ (1,0) [0|1] "-" ETM,LTM
 SG_ Drowsy_Driver_Alert : 59|1@0+ (1,0) [0|1] "" BCM,ETM,LTM
 SG_ Speed_Unit : 0|1@0+ (1,0) [0|1] "" ETM,LTM

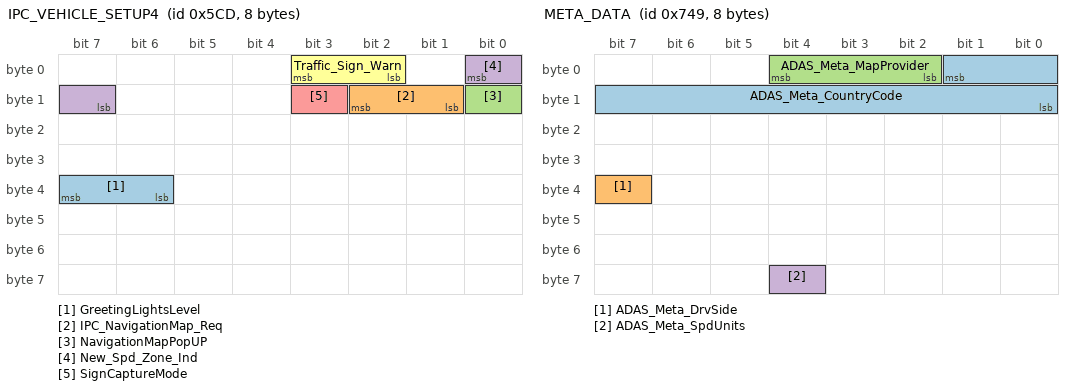
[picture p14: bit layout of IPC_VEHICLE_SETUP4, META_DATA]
BO_ 1485 IPC_VEHICLE_SETUP4: 8 IPC
 SG_ GreetingLightsLevel : 39|2@0+ (1,0) [0|3] "-" BCM,ETM,LTM
 SG_ IPC_NavigationMap_Req : 10|2@0+ (1,0) [0|3] "" ETM
 SG_ NavigationMapPopUP : 8|1@0+ (1,0) [0|1] "" ETM
 SG_ New_Spd_Zone_Ind : 0|2@0+ (1,0) [0|3] "" ETM,LTM
 SG_ SignCaptureMode : 11|1@0+ (1,0) [0|1] "" ETM,LTM
 SG_ Traffic_Sign_Warn : 3|2@0+ (1,0) [0|3] "" BCM,ETM,LTM

BO_ 1865 META_DATA: 8 ETM
 SG_ ADAS_Meta_CountryCode : 1|10@0+ (1,0) [0|1023] "-" BCM,IPC
 SG_ ADAS_Meta_DrvSide : 39|1@0+ (1,0) [0|1] "-" BCM,IPC
 SG_ ADAS_Meta_MapProvider : 4|3@0+ (1,0) [0|7] "" BCM,IPC
 SG_ ADAS_Meta_SpdUnits : 60|1@0+ (1,0) [0|1] "-" BCM,IPC

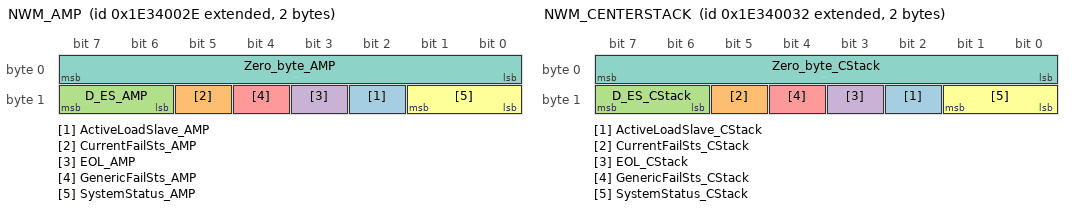
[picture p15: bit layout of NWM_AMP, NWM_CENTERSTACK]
BO_ 2654208046 NWM_AMP: 2 AMP
 SG_ ActiveLoadSlave_AMP : 10|1@0+ (1,0) [0|1] "-" BCM
 SG_ CurrentFailSts_AMP : 13|1@0+ (1,0) [0|1] "-" BCM
 SG_ D_ES_AMP : 15|2@0+ (1,0) [0|3] "-" Vector__XXX
 SG_ EOL_AMP : 11|1@0+ (1,0) [0|1] "-" BCM
 SG_ GenericFailSts_AMP : 12|1@0+ (1,0) [0|1] "-" BCM
 SG_ SystemStatus_AMP : 9|2@0+ (1,0) [0|3] "-" BCM
 SG_ Zero_byte_AMP : 7|8@0+ (1,0) [0|0] "-" BCM

BO_ 2654208000 NWM_BCM: 6 BCM
 SG_ ActiveLoadMaster : 10|1@0+ (1,0) [0|1] "-" AMP,DCSD,ECC,EMCM,HCPM,IPC,LSMD,LSMP,LTM,TBM
 SG_ D_ES_BCM : 15|2@0+ (1,0) [0|3] "-" AMP,DCSD,ECC,EMCM,HCPM,IPC,LSMD,LSMP,LTM,TBM
 SG_ EOL_BCM : 11|1@0+ (1,0) [0|1] "-" AMP,DCSD,ECC,EMCM,HCPM,IPC,LSMD,LSMP,LTM,TBM
 SG_ GenericFailSts_BCM : 12|1@0+ (1,0) [0|1] "-" AMP,DCSD,ECC,EMCM,HCPM,IPC,LSMD,LSMP,LTM,TBM
 SG_ Node0 : 40|1@0+ (1,0) [0|1] "-" AMP,DCSD,ECC,EMCM,HCPM,IPC,LSMD,LSMP,LTM,TBM
 SG_ Node1 : 41|1@0+ (1,0) [0|1] "-" AMP,DCSD,ECC,EMCM,HCPM,IPC,LSMD,LSMP,LTM,TBM
 SG_ Node10 : 34|1@0+ (1,0) [0|1] "-" AMP,DCSD,ECC,EMCM,HCPM,IPC,LSMD,LSMP,LTM,TBM
 SG_ Node11 : 35|1@0+ (1,0) [0|1] "-" AMP,DCSD,ECC,EMCM,HCPM,IPC,LSMD,LSMP,LTM,TBM
 SG_ Node12 : 36|1@0+ (1,0) [0|1] "-" AMP,DCSD,ECC,EMCM,HCPM,IPC,LSMD,LSMP,LTM,TBM
 SG_ Node13 : 37|1@0+ (1,0) [0|1] "-" AMP,DCSD,ECC,EMCM,HCPM,IPC,LSMD,LSMP,LTM,TBM
 SG_ Node14 : 38|1@0+ (1,0) [0|1] "-" AMP,DCSD,ECC,EMCM,HCPM,IPC,LSMD,LSMP,LTM,TBM
 SG_ Node15 : 39|1@0+ (1,0) [0|1] "-" AMP,DCSD,ECC,EMCM,HCPM,IPC,LSMD,LSMP,LTM,TBM
 SG_ Node16 : 24|1@0+ (1,0) [0|1] "-" AMP,DCSD,ECC,EMCM,HCPM,IPC,LSMD,LSMP,LTM,TBM
 SG_ Node17 : 25|1@0+ (1,0) [0|1] "-" AMP,DCSD,ECC,EMCM,HCPM,IPC,LSMD,LSMP,LTM,TBM
 SG_ Node18 : 26|1@0+ (1,0) [0|1] "-" AMP,DCSD,ECC,EMCM,HCPM,IPC,LSMD,LSMP,LTM,TBM
 SG_ Node19 : 27|1@0+ (1,0) [0|1] "-" AMP,DCSD,ECC,EMCM,HCPM,IPC,LSMD,LSMP,LTM,TBM
 SG_ Node2 : 42|1@0+ (1,0) [0|1] "-" AMP,DCSD,ECC,EMCM,HCPM,IPC,LSMD,LSMP,LTM,TBM
 SG_ Node20 : 28|1@0+ (1,0) [0|1] "-" AMP,DCSD,ECC,EMCM,HCPM,IPC,LSMD,LSMP,LTM,TBM
 SG_ Node21 : 29|1@0+ (1,0) [0|1] "-" AMP,DCSD,ECC,EMCM,HCPM,IPC,LSMD,LSMP,LTM,TBM
 SG_ Node22 : 30|1@0+ (1,0) [0|1] "-" AMP,DCSD,ECC,EMCM,HCPM,IPC,LSMD,LSMP,LTM,TBM
 SG_ Node23 : 31|1@0+ (1,0) [0|1] "-" AMP,DCSD,ECC,EMCM,HCPM,IPC,LSMD,LSMP,LTM,TBM
 SG_ Node24 : 16|1@0+ (1,0) [0|1] "-" AMP,DCSD,ECC,EMCM,HCPM,IPC,LSMD,LSMP,LTM,TBM
 SG_ Node25 : 17|1@0+ (1,0) [0|1] "-" AMP,DCSD,ECC,EMCM,HCPM,IPC,LSMD,LSMP,LTM,TBM
 SG_ Node26 : 18|1@0+ (1,0) [0|1] "-" AMP,DCSD,ECC,EMCM,HCPM,IPC,LSMD,LSMP,LTM,TBM
 SG_ Node27 : 19|1@0+ (1,0) [0|1] "-" AMP,DCSD,ECC,EMCM,HCPM,IPC,LSMD,LSMP,LTM,TBM
 SG_ Node28 : 20|1@0+ (1,0) [0|1] "-" AMP,DCSD,ECC,EMCM,HCPM,IPC,LSMD,LSMP,LTM,TBM
 SG_ Node29 : 21|1@0+ (1,0) [0|1] "-" AMP,DCSD,ECC,EMCM,HCPM,IPC,LSMD,LSMP,LTM,TBM
 SG_ Node3 : 43|1@0+ (1,0) [0|1] "-" AMP,DCSD,ECC,EMCM,HCPM,IPC,LSMD,LSMP,LTM,TBM
 SG_ Node30 : 22|1@0+ (1,0) [0|1] "-" AMP,DCSD,ECC,EMCM,HCPM,IPC,LSMD,LSMP,LTM,TBM
 SG_ Node31 : 23|1@0+ (1,0) [0|1] "-" AMP,DCSD,ECC,EMCM,HCPM,IPC,LSMD,LSMP,LTM,TBM
 SG_ Node4 : 44|1@0+ (1,0) [0|1] "-" AMP,DCSD,ECC,EMCM,HCPM,IPC,LSMD,LSMP,LTM,TBM
 SG_ Node5 : 45|1@0+ (1,0) [0|1] "-" AMP,DCSD,ECC,EMCM,HCPM,IPC,LSMD,LSMP,LTM,TBM
 SG_ Node6 : 46|1@0+ (1,0) [0|1] "-" AMP,DCSD,ECC,EMCM,HCPM,IPC,LSMD,LSMP,LTM,TBM
 SG_ Node7 : 47|1@0+ (1,0) [0|1] "-" AMP,DCSD,ECC,EMCM,HCPM,IPC,LSMD,LSMP,LTM,TBM
 SG_ Node8 : 32|1@0+ (1,0) [0|1] "-" AMP,DCSD,ECC,EMCM,HCPM,IPC,LSMD,LSMP,LTM,TBM
 SG_ Node9 : 33|1@0+ (1,0) [0|1] "-" AMP,DCSD,ECC,EMCM,HCPM,IPC,LSMD,LSMP,LTM,TBM
 SG_ P_ES : 13|1@0+ (1,0) [0|1] "-" AMP,DCSD,ECC,EMCM,HCPM,IPC,LSMD,LSMP,LTM,TBM
 SG_ SystemCommand : 9|2@0+ (1,0) [0|3] "-" AMP,DCSD,ECC,EMCM,HCPM,IPC,LSMD,LSMP,LTM,TBM
 SG_ Zero_byte_BCM : 7|8@0+ (1,0) [0|0] "-" AMP,DCSD,ECC,EMCM,HCPM,IPC,LSMD,LSMP,LTM,TBM

BO_ 2654208050 NWM_CENTERSTACK: 2 HCPM
 SG_ ActiveLoadSlave_CStack : 10|1@0+ (1,0) [0|1] "-" BCM
 SG_ CurrentFailSts_CStack : 13|1@0+ (1,0) [0|1] "-" BCM
 SG_ D_ES_CStack : 15|2@0+ (1,0) [0|3] "-" Vector__XXX
 SG_ EOL_CStack : 11|1@0+ (1,0) [0|1] "-" BCM
 SG_ GenericFailSts_CStack : 12|1@0+ (1,0) [0|1] "-" BCM
 SG_ SystemStatus_CStack : 9|2@0+ (1,0) [0|3] "-" BCM
 SG_ Zero_byte_CStack : 7|8@0+ (1,0) [0|0] "-" BCM

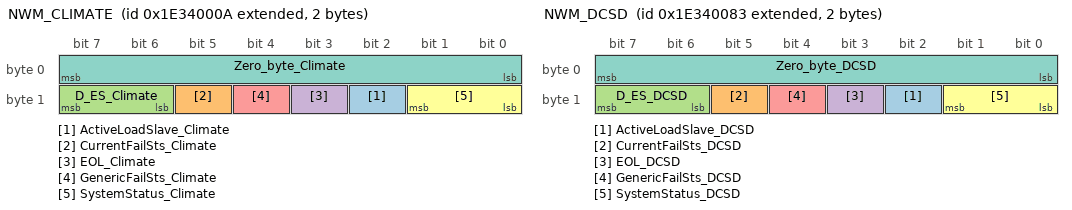
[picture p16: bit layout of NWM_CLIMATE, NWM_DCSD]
BO_ 2654208010 NWM_CLIMATE: 2 ECC
 SG_ ActiveLoadSlave_Climate : 10|1@0+ (1,0) [0|1] "-" BCM
 SG_ CurrentFailSts_Climate : 13|1@0+ (1,0) [0|1] "-" BCM
 SG_ D_ES_Climate : 15|2@0+ (1,0) [0|3] "-" Vector__XXX
 SG_ EOL_Climate : 11|1@0+ (1,0) [0|1] "-" BCM
 SG_ GenericFailSts_Climate : 12|1@0+ (1,0) [0|1] "-" BCM
 SG_ SystemStatus_Climate : 9|2@0+ (1,0) [0|3] "-" BCM
 SG_ Zero_byte_Climate : 7|8@0+ (1,0) [0|0] "-" BCM

BO_ 2654208131 NWM_DCSD: 2 DCSD
 SG_ ActiveLoadSlave_DCSD : 10|1@0+ (1,0) [0|1] "-" BCM
 SG_ CurrentFailSts_DCSD : 13|1@0+ (1,0) [0|1] "-" BCM
 SG_ D_ES_DCSD : 15|2@0+ (1,0) [0|3] "-" Vector__XXX
 SG_ EOL_DCSD : 11|1@0+ (1,0) [0|1] "-" BCM
 SG_ GenericFailSts_DCSD : 12|1@0+ (1,0) [0|1] "-" BCM
 SG_ SystemStatus_DCSD : 9|2@0+ (1,0) [0|3] "-" BCM
 SG_ Zero_byte_DCSD : 7|8@0+ (1,0) [0|0] "-" BCM

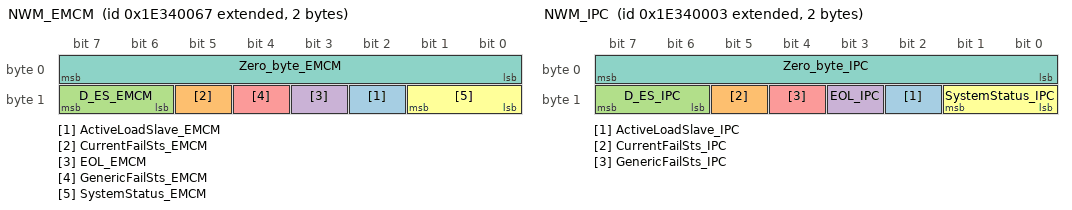
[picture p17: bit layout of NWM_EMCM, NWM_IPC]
BO_ 2654208103 NWM_EMCM: 2 EMCM
 SG_ ActiveLoadSlave_EMCM : 10|1@0+ (1,0) [0|1] "-" BCM
 SG_ CurrentFailSts_EMCM : 13|1@0+ (1,0) [0|1] "-" BCM
 SG_ D_ES_EMCM : 15|2@0+ (1,0) [0|3] "-" Vector__XXX
 SG_ EOL_EMCM : 11|1@0+ (1,0) [0|1] "-" BCM
 SG_ GenericFailSts_EMCM : 12|1@0+ (1,0) [0|1] "-" BCM
 SG_ SystemStatus_EMCM : 9|2@0+ (1,0) [0|3] "-" BCM
 SG_ Zero_byte_EMCM : 7|8@0+ (1,0) [0|0] "-" BCM

BO_ 2654208003 NWM_IPC: 2 IPC
 SG_ ActiveLoadSlave_IPC : 10|1@0+ (1,0) [0|1] "-" BCM
 SG_ CurrentFailSts_IPC : 13|1@0+ (1,0) [0|1] "-" BCM
 SG_ D_ES_IPC : 15|2@0+ (1,0) [0|3] "-" Vector__XXX
 SG_ EOL_IPC : 11|1@0+ (1,0) [0|1] "-" BCM
 SG_ GenericFailSts_IPC : 12|1@0+ (1,0) [0|1] "-" BCM
 SG_ SystemStatus_IPC : 9|2@0+ (1,0) [0|3] "-" BCM
 SG_ Zero_byte_IPC : 7|8@0+ (1,0) [0|0] "-" BCM

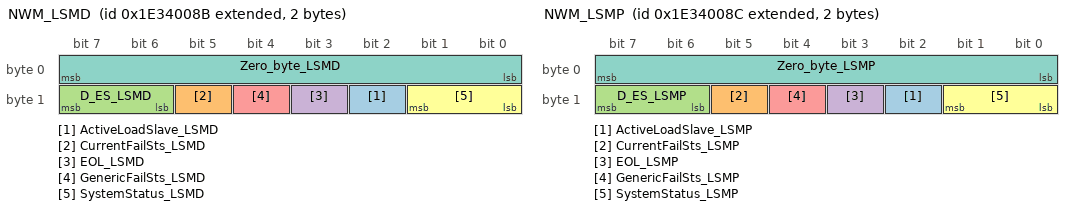
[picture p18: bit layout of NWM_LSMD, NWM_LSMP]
BO_ 2654208139 NWM_LSMD: 2 LSMD
 SG_ ActiveLoadSlave_LSMD : 10|1@0+ (1,0) [0|1] "-" BCM
 SG_ CurrentFailSts_LSMD : 13|1@0+ (1,0) [0|1] "-" BCM
 SG_ D_ES_LSMD : 15|2@0+ (1,0) [0|3] "-" Vector__XXX
 SG_ EOL_LSMD : 11|1@0+ (1,0) [0|1] "-" BCM
 SG_ GenericFailSts_LSMD : 12|1@0+ (1,0) [0|1] "-" BCM
 SG_ SystemStatus_LSMD : 9|2@0+ (1,0) [0|3] "-" BCM
 SG_ Zero_byte_LSMD : 7|8@0+ (1,0) [0|0] "-" BCM

BO_ 2654208140 NWM_LSMP: 2 LSMP
 SG_ ActiveLoadSlave_LSMP : 10|1@0+ (1,0) [0|1] "-" BCM
 SG_ CurrentFailSts_LSMP : 13|1@0+ (1,0) [0|1] "-" BCM
 SG_ D_ES_LSMP : 15|2@0+ (1,0) [0|3] "-" Vector__XXX
 SG_ EOL_LSMP : 11|1@0+ (1,0) [0|1] "-" BCM
 SG_ GenericFailSts_LSMP : 12|1@0+ (1,0) [0|1] "-" BCM
 SG_ SystemStatus_LSMP : 9|2@0+ (1,0) [0|3] "-" BCM
 SG_ Zero_byte_LSMP : 7|8@0+ (1,0) [0|0] "-" BCM

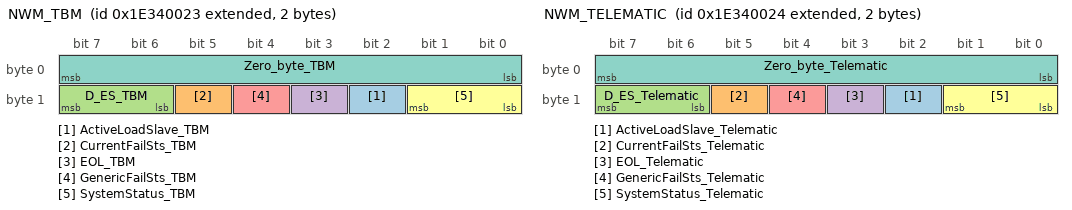
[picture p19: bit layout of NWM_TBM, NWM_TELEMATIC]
BO_ 2654208035 NWM_TBM: 2 TBM
 SG_ ActiveLoadSlave_TBM : 10|1@0+ (1,0) [0|1] "-" BCM
 SG_ CurrentFailSts_TBM : 13|1@0+ (1,0) [0|1] "-" BCM
 SG_ D_ES_TBM : 15|2@0+ (1,0) [0|3] "-" Vector__XXX
 SG_ EOL_TBM : 11|1@0+ (1,0) [0|1] "-" BCM
 SG_ GenericFailSts_TBM : 12|1@0+ (1,0) [0|1] "-" BCM
 SG_ SystemStatus_TBM : 9|2@0+ (1,0) [0|3] "-" BCM
 SG_ Zero_byte_TBM : 7|8@0+ (1,0) [0|0] "-" BCM

BO_ 2654208036 NWM_TELEMATIC: 2 ETM
 SG_ ActiveLoadSlave_Telematic : 10|1@0+ (1,0) [0|1] "-" BCM
 SG_ CurrentFailSts_Telematic : 13|1@0+ (1,0) [0|1] "-" BCM
 SG_ D_ES_Telematic : 15|2@0+ (1,0) [0|3] "-" Vector__XXX
 SG_ EOL_Telematic : 11|1@0+ (1,0) [0|1] "-" BCM
 SG_ GenericFailSts_Telematic : 12|1@0+ (1,0) [0|1] "-" BCM
 SG_ SystemStatus_Telematic : 9|2@0+ (1,0) [0|3] "-" BCM
 SG_ Zero_byte_Telematic : 7|8@0+ (1,0) [0|0] "-" BCM

BO_ 950 PARK_INFO: 8 BCM
 SG_ Alert_CHF : 12|3@0+ (1,0) [0|7] "-" IPC
 SG_ Alert_CHR : 5|3@0+ (1,0) [0|7] "-" IPC
 SG_ Alert_LHF : 9|3@0+ (1,0) [0|7] "-" IPC
 SG_ Alert_LHR : 2|3@0+ (1,0) [0|7] "-" IPC
 SG_ Alert_RHF : 22|3@0+ (1,0) [0|7] "-" IPC
 SG_ Alert_RHR : 15|3@0+ (1,0) [0|7] "-" IPC
 SG_ ChimeActivation_LHF : 36|1@0+ (1,0) [0|1] "-" AMP,ETM,IPC,LTM,TBM
 SG_ ChimeActivation_LHR : 38|1@0+ (1,0) [0|1] "-" AMP,ETM,IPC,LTM,RRM,TBM
 SG_ ChimeActivation_RHF : 37|1@0+ (1,0) [0|1] "-" AMP,ETM,IPC,LTM,TBM
 SG_ ChimeActivation_RHR : 39|1@0+ (1,0) [0|1] "-" AMP,ETM,IPC,LTM,RRM,TBM
 SG_ ChimeRepetitionRate_Front : 47|4@0+ (1,0) [0|15] "Hz" AMP,ETM,IPC,LTM,TBM
 SG_ ChimeRepetitionRate_Rear : 43|4@0+ (1,0) [0|15] "Hz" AMP,ETM,IPC,LTM,RRM,TBM
 SG_ ChimeType_Front : 33|2@0+ (1,0) [0|3] "-" AMP,ETM,LTM,TBM
 SG_ ChimeType_Rear : 35|2@0+ (1,0) [0|3] "-" AMP,ETM,LTM,RRM,TBM
 SG_ DisplayActivation : 6|1@0+ (1,0) [0|1] "-" IPC
 SG_ ObstacleInTrajectory_CHF : 54|1@0+ (1,0) [0|1] "-" IPC
 SG_ ObstacleInTrajectory_CHR : 51|1@0+ (1,0) [0|1] "-" IPC
 SG_ ObstacleInTrajectory_LHF : 53|1@0+ (1,0) [0|1] "-" IPC
 SG_ ObstacleInTrajectory_LHR : 50|1@0+ (1,0) [0|1] "-" IPC
 SG_ ObstacleInTrajectory_RHF : 55|1@0+ (1,0) [0|1] "-" IPC
 SG_ ObstacleInTrajectory_RHR : 52|1@0+ (1,0) [0|1] "-" IPC

BO_ 1282 RADIO_B2: 8 ETM
 SG_ Radio_Delete_Request : 42|3@0+ (1,0) [0|6] "" IPC
 SG_ Radio_Profile_Request : 34|3@0+ (1,0) [0|6] "" IPC

BO_TX_BU_ 2651930660 : ETM,LTM;
BO_TX_BU_ 1498 : ETM,LTM;
BO_TX_BU_ 1478 : ETM,LTM;
BO_TX_BU_ 2564457457 : BCM,DIAG_TEST,TBM;
BO_TX_BU_ 2564457969 : BCM,DIAG_TEST,TBM;
BO_TX_BU_ 2564462833 : BCM,DIAG_TEST,TBM;
BO_TX_BU_ 2564451057 : BCM,DIAG_TEST,TBM;
BO_TX_BU_ 2564479473 : BCM,DIAG_TEST,TBM;
BO_TX_BU_ 2564445425 : BCM,DIAG_TEST,TBM;
BO_TX_BU_ 2564445681 : BCM,DIAG_TEST,TBM;
BO_TX_BU_ 2564458481 : BCM,DIAG_TEST,TBM;
BO_TX_BU_ 2564485511 : ETM,LTM;
BO_TX_BU_ 1896 : ETM,LTM;
BO_TX_BU_ 2147583473 : BCM,DIAG_TEST;
BO_TX_BU_ 2147582961 : BCM,DIAG_TEST;
BO_TX_BU_ 2147588337 : BCM,DIAG_TEST;
BO_TX_BU_ 2147576561 : BCM,DIAG_TEST;
BO_TX_BU_ 2147584753 : BCM,DIAG_TEST;
BO_TX_BU_ 2147570929 : BCM,DIAG_TEST;
BO_TX_BU_ 2147571185 : BCM,DIAG_TEST;
BO_TX_BU_ 2147583985 : BCM,DIAG_TEST;
BO_TX_BU_ 142 : ETM,LTM;
BO_TX_BU_ 1463 : ETM,LTM;
BO_TX_BU_ 1447 : ETM,LTM;
BO_TX_BU_ 1453 : ETM,LTM;
BO_TX_BU_ 138 : ETM,LTM;
BO_TX_BU_ 2654208036 : ETM,LTM;
BO_TX_BU_ 1282 : ETM,LTM;

CM_ "Project_332BEV_ProjectStandard_B-CAN [07338]";
CM_ SG_ 1985 VehicleArchitectureInfo "Signal used to indicate the vehicle architecture";
CM_ SG_ 1474 AbortCrankingAtc "The signal provides the information when the BCM performs the abort cranking request";
CM_ SG_ 1474 HeadlightsDelayModeActive "Define the successful activation of the Remote Headlights Off Delay";
CM_ SG_ 1474 PanicModeActive "Panic Status";
CM_ SG_ 1506 DoorsDeadLockReq "This signal is used to require the deadlock, undeadlock of the door latch";
CM_ SG_ 1506 DoorsLockUnlockReq "This signal is used to require the lock, unlock or driver unlock of the door latch";
CM_ SG_ 1506 DoorsSts "This signal is used to give information about the open\close of all doors";
CM_ SG_ 1506 FPSSts "This signal is used to give information about fire prevention system activation";
CM_ SG_ 1506 InternalReleaseLightReq "This signal is used to require turn on of the internal switch light.";
CM_ SG_ 1506 LockUnlockRequestor "This signal is used to give information about the requestor of lock and unlock command";
CM_ SG_ 1506 LockUnlockVehicleSts "This signal is used to give information about the lock\unlock status of the vehicle";
CM_ SG_ 1506 PhoneReminderIndication "The signal is used to activate the indication of the \"phone reminder\" functionality on the IPC";
CM_ SG_ 1506 RoofSts "This signal is used to give information about the roof status";
CM_ SG_ 1506 WirelessPadSts "The signal is used to activate indications on the LTM/ETM according to the status of the WCPM";
CM_ SG_ 160 BCMFpsCommand "The signal is used to command the FPS strategy actuation";
CM_ SG_ 160 BCMFpsConfirm "The signal is used to confirm the FPS strategy command";
CM_ SG_ 160 BCMFpsFailSts "This signal is used to give information of a fault present on the FPS sensing device .";
CM_ SG_ 134 FPS_Status_Request "The signal is used to request the status of  FPS system.";
CM_ SG_ 1050 Climate_btn0 "Indicates the status of  climate button0";
CM_ SG_ 1050 Climate_btn1 "Indicates the status of  climate button1";
CM_ SG_ 1050 Climate_btn10 "Indicates the status of  climate button10";
CM_ SG_ 1050 Climate_btn12 "Indicates the status of climate button 12";
CM_ SG_ 1050 Climate_btn13 "Indicates the status of climate button 13";
CM_ SG_ 1050 Climate_btn2 "Indicates the status of  climate button2";
CM_ SG_ 1050 Climate_btn3 "Indicates the status of  climate button3";
CM_ SG_ 1050 Climate_btn4 "Indicates the status of  climate button4";
CM_ SG_ 1050 Climate_btn5 "Indicates the status of  climate button5";
CM_ SG_ 1050 Climate_btn6 "Indicates the status of  climate button6";
CM_ SG_ 1050 Climate_btn7 "Indicates the status of  climate button7";
CM_ SG_ 1050 Climate_btn8 "Indicates the status of  climate button8";
CM_ SG_ 1050 Climate_btn9 "Indicates the status of  climate button9";
CM_ SG_ 224 DisplayedSpeedSign "This signal indicates the road sign of vehicle speed limit displayed by IPC";
CM_ SG_ 208 ChargeNow "Charge Now Signal";
CM_ SG_ 208 DateTmFormat2 "Date and Time Format";
CM_ SG_ 208 PairingCode "Bluetooth pairing code";
CM_ SG_ 208 PairingRequest "Bluetooth pairing code request";
CM_ SG_ 208 WeekdayTmHour_End "Time of day during the weekday: Hours";
CM_ SG_ 208 WeekdayTmHour_Start "Time of day during the weekday: Hours";
CM_ SG_ 208 WeekdayTmMinute_End "Time of day during the weekday: Minutes";
CM_ SG_ 208 WeekdayTmMinute_Start "Time of day during the weekday: Minutes";
CM_ SG_ 208 WeekendTmHour_End "Time of day during the weekend: Hours";
CM_ SG_ 208 WeekendTmHour_Start "Time of day during the weekend: Hours";
CM_ SG_ 208 WeekendTmMinute_End "Time of day during the weekend: Minute";
CM_ SG_ 208 WeekendTmMinute_Start "Time of day during the weekend: Minute";
CM_ SG_ 1498 CM_TCH_PT_DTV "Touch screen pointer for DTV video";
CM_ SG_ 1498 CM_TCH_PT_VES2 "Touch screen pointer for rear seat entertainment";
CM_ SG_ 1498 CM_TCH_STAT "Touch Screen Status";
CM_ SG_ 1498 CM_TCH_X_COORD "Value for the touch screen X axis coordinates";
CM_ SG_ 1498 CM_TCH_Y_COORD "Value for the touch screen Y axis coordinates";
CM_ SG_ 177 PowerLevel_External_Req "This signal is menaged when the driver requests the Power Level setting";
CM_ SG_ 177 RemStNrmlStEnbl_External_Req "The signal is used to request a change in the Auto On Comfort setting";
CM_ SG_ 1478 AUD_LVLSts "Audio level";
CM_ SG_ 1478 BAL_LVLSts "Balance level [ P = right; N = left ]";
CM_ SG_ 1478 BASS_LVLSts "Bass range level";
CM_ SG_ 1478 DSS_ONSts "Driver Surround Sound On/Off";
CM_ SG_ 1478 FD_LVLSts "Fade level [ P = right; N = left ]";
CM_ SG_ 1478 INFO1_AUD_ACT "Information source 1 audio active";
CM_ SG_ 1478 INFO1_AUD_LEVEL "Information source 1 audio level";
CM_ SG_ 1478 INFO1_AUD_TYPE "Mono Audio Control Enable";
CM_ SG_ 1478 INFO2_AUD_ACT "Information source 2 audio active";
CM_ SG_ 1478 INFO2_AUD_LEVEL "Information source 2 audio level";
CM_ SG_ 1478 INFO2_AUD_TYPE "Mono Audio Control Enable";
CM_ SG_ 1478 MID_LVLSts "Mid range level";
CM_ SG_ 1478 SCV_LVLSts "Speed controlled volume level";
CM_ SG_ 1478 TREB_LVLSts "Treble range level";
CM_ SG_ 2564554481 N_PDU "This signal is used for diagnostic purposes";
CM_ SG_ 2564457457 N_PDU "This signal is used for diagnostic purposes";
CM_ SG_ 2564457969 N_PDU "This signal is used for diagnostic purposes";
CM_ SG_ 2564462833 N_PDU "This signal is used for diagnostic purposes";
CM_ SG_ 2564451057 N_PDU "This signal is used for diagnostic purposes";
CM_ SG_ 2564479473 N_PDU "This signal is used for diagnostic purposes";
CM_ SG_ 2564445425 N_PDU "This signal is used for diagnostic purposes";
CM_ SG_ 2564445681 N_PDU "This signal is used for diagnostic purposes";
CM_ SG_ 2564458481 N_PDU "This signal is used for diagnostic purposes";
CM_ SG_ 2564485507 N_PDU "-";
CM_ SG_ 2564485509 N_PDU "-";
CM_ SG_ 2564485528 N_PDU "This signal is used for diagnostic purposes";
CM_ SG_ 2564485482 N_PDU "-";
CM_ SG_ 2564485593 N_PDU "-";
CM_ SG_ 2564485460 N_PDU "This signal is used for diagnostic purposes";
CM_ SG_ 2564485461 N_PDU "This signal is used for diagnostic purposes";
CM_ SG_ 2564485511 N_PDU "This signal is used for diagnostic purposes";
CM_ SG_ 1445 DCSD_DISP_STAT "Remote Display Status";
CM_ SG_ 1422 DrvDoorLatchDeadLockSts "This signal is used to give information about the deadlock\undeadlock of the LSMD latch status";
CM_ SG_ 1422 DrvDoorLatchSts "This signal is used to give information about the lock\unlock of the LSMD latch status";
CM_ SG_ 1422 E1DriverDoorSts "This signal is used to give information about the open\close of the driver door status";
CM_ SG_ 1422 LSMDAjarSensorFailSts "This signal is used to give information about the fault on the driver door ajar sensor";
CM_ SG_ 1422 LSMDCrashLineFailSts "This signal is used to give information about crash line fail of the LSMD";
CM_ SG_ 1422 LSMDExternalLockReleaseSwitchFa "This signal is used to give information about the fault on the driver external lock or release switch";
CM_ SG_ 1422 LSMDFobSearchReq "This signal is used to require the key fob search for driver door release or for central doors lock from driver door external handle.";
CM_ SG_ 1422 LSMDInternalFailSts "This signal is used to give information about generic internal fail of the LSMD";
CM_ SG_ 1422 LSMDInternalLockLightFailSts "This signal is used to give information about the fault on the driver internal lock switch light";
CM_ SG_ 1422 LSMDInternalReleaseSwitchFailSts "This signal is used to give information about the fault on the  driver internal release switch";
CM_ SG_ 1422 LSMDInternalUnlockLightFailSts "This signal is used to give information about the fault on the driver internal unlock switch light";
CM_ SG_ 1422 LSMDReleaseLockReq "This signal is used to require the lock of the driver door latch";
CM_ SG_ 1422 LSMDTrunkDisableReq "This signal is used to require the trunk external handle disabling from driver door switch";
CM_ SG_ 1424 E2PsngrDoorSts "This signal is used to give information about the open\close of the passenger door status.  It will replace PsngrDoorSts signal sent by LSMP.";
CM_ SG_ 1424 LSMPAjarSensorFailSts "This signal is used to give information about the fault on the passenger door ajar sensor";
CM_ SG_ 1424 LSMPCrashLineFailSts "This signal is used to give information about crash line fail of the LSMP";
CM_ SG_ 1424 LSMPExternalLockReleaseSwitchFa "This signal is used to give information about the fault on the passenger external lock or release switch";
CM_ SG_ 1424 LSMPFobSearchReq "This signal is used to require the key fob search for passenger door release or for central doors lock from passenger door external handle.";
CM_ SG_ 1424 LSMPInternalFailSts "This signal is used to give information about generic internal fail of the LSMP";
CM_ SG_ 1424 LSMPInternalLockLightFailSts "This signal is used to give information about the fault on the passenger internal lock switch light";
CM_ SG_ 1424 LSMPInternalReleaseSwitchFailSts "This signal is used to give information about the fault on the  passenger internal release switch";
CM_ SG_ 1424 LSMPInternalUnlockLightFailSts "This signal is used to give information about the fault on the passenger internal unlock switch light";
CM_ SG_ 1424 LSMPReleaseLockReq "This signal is used to require the lock of the passenger door latch";
CM_ SG_ 1424 LSMPTrunkDisableReq "This signal is used to require the trunk external handle disabling from passenger door switch";
CM_ SG_ 1424 PsngrDoorLatchDeadLockSts "This signal is used to give information about the deadlock\undeadlock of the LSMP latch status";
CM_ SG_ 1424 PsngrDoorLatchSts "This signal is used to give information about the lock\unlock of the LSMP latch status";
CM_ SG_ 852 AHBFeature "This signal indicates the Auto High Beam Feature status";
CM_ SG_ 852 AlertLightsON "This signal is used to activate an indication with buzzer when the user left the Lights ON at Ignition OFF";
CM_ SG_ 852 FHeatedWindowSts "Used to indicate the Front heated window activation/deactivation status";
CM_ SG_ 852 FollowMeHomeReqSts "Request to activate the feature follow me home";
CM_ SG_ 852 L_TurnLightActivationSts "Request of Left Turn Lights activation";
CM_ SG_ 852 R_TurnLightActivationSts "Request of Right Turn Lights activation";
CM_ SG_ 852 RHeatedWindowSts "Used to indicate the Rear heated window activation/deactivation status";
CM_ SG_ 852 StopLightSts "Request of Stop Lights activation";
CM_ SG_ 128 UpdateSts "It is used to estimate FOTA TBM Update package status";
CM_ SG_ 1896 GPS_POS3_Date_Day "GPS date day";
CM_ SG_ 1896 GPS_POS3_Date_Hour "GPS date hour";
CM_ SG_ 1896 GPS_POS3_Date_Minutes "GPS date minutes";
CM_ SG_ 1896 GPS_POS3_Date_Month "GPS date month";
CM_ SG_ 1896 GPS_POS3_Date_Seconds "GPS date seconds";
CM_ SG_ 1896 GPS_POS3_Date_Year "GPS date year";
CM_ SG_ 1270 AHBFault "HALF sends to the BCM the fault condition";
CM_ SG_ 1270 DisplaySts "This signal will be used to indicate the status of Lane keeping";
CM_ SG_ 1270 SensorBlinded "This signal indicates the HALF state";
CM_ SG_ 1442 FastEscalation "This signal is used to indicate the start of fast escalation";
CM_ SG_ 1442 HandsOffSts "This signal will be used to indicate the status of Hands Off";
CM_ SG_ 1442 LC_HandsOffSts "This signal will be used to indicate the status of of Hands Off of Lane Centering";
CM_ SG_ 1443 BatPwrUsageDisp "Battery power usage for HMI, in KW";
CM_ SG_ 1443 BatPwrUsageDisp_V "Validity bit for signal BatPwrUsageDisp, 0=Valid";
CM_ SG_ 1443 HVACPwrUsageDisp "HVAC power usage for HMI, in KW";
CM_ SG_ 1443 HVACPwrUsageDisp_V "Validity bit for signal HVACPwrUsageDisp, 0=Valid";
CM_ SG_ 1443 MtrPwrUsageDisp "Motor power usage for HMI, in KW";
CM_ SG_ 1443 MtrPwrUsageDisp_V "Validity bit for signal MtrPwrUsageDisp, 0=Valid";
CM_ SG_ 2147583473 N_PDU "This signal is used for diagnostic purposes";
CM_ SG_ 2147582961 N_PDU "This signal is used for diagnostic purposes";
CM_ SG_ 2147588337 N_PDU "This signal is used for diagnostic purposes";
CM_ SG_ 2147576561 N_PDU "This signal is used for diagnostic purposes";
CM_ SG_ 2147584753 N_PDU "This signal is used for diagnostic purposes";
CM_ SG_ 2147570929 N_PDU "This signal is used for diagnostic purposes";
CM_ SG_ 2147571185 N_PDU "This signal is used for diagnostic purposes";
CM_ SG_ 2147583985 N_PDU "This signal is used for diagnostic purposes";
CM_ SG_ 1864 DewpointTmp "Dew Point Temperature";
CM_ SG_ 1864 GlassTmp "Interior windscreen temperature";
CM_ SG_ 1864 HumSns_Int_flt "Humidity Sensor Internal Fault";
CM_ SG_ 1864 RelHumidity "Interior relative humidity";
CM_ SG_ 1864 SolarSensorLeft "Solar sensor left intensity";
CM_ SG_ 1864 SolarSensorRight "Solar sensor right intensity";
CM_ SG_ 142 ConnectedDevices "It indicates if a frame of the CONNECTED DEVICES is received or not.";
CM_ SG_ 142 SSID "It indicates if a frame of the SSID is received or not.";
CM_ SG_ 1463 Batt_CabinPriority1 "Bit to prioritize cabin conditioning under schedule 1";
CM_ SG_ 1463 ChargeUntilFull1 "Charge until battery is fully charged with schedule 1";
CM_ SG_ 1463 Do_Not_Repeat1 "Do not repeat the set Schedule";
CM_ SG_ 1463 Enable_Schedule1 "Schedule 1 checkbox enabled";
CM_ SG_ 1463 End_Time_Hr1 "End Time of schedule 1 (hours in 24 hrs. format)";
CM_ SG_ 1463 End_Time_Min1 "End Time of schedule 1(Minutes)";
CM_ SG_ 1463 Schedule_Day1 "Schedule#1 Day for charging or cabin conditioning";
CM_ SG_ 1463 Schedule_Type1 "Type of charging and climate schedule";
CM_ SG_ 1463 Start_Time_Hr1 "Start Time of schedule  1 (hours in 24 hrs. format)";
CM_ SG_ 1463 Start_Time_Min1 "Start Time of schedule  1 (minutes)";
CM_ SG_ 1463 Submit_Schedule1 "Schedule 1 submitted";
CM_ SG_ 1447 Batt_CabinPriority2 "Bit to prioritize battery charging or cabin conditioning under schedule 2";
CM_ SG_ 1447 ChargeUntilFull2 "Charge until battery is fully charged with schedule 2";
CM_ SG_ 1447 Do_Not_Repeat2 "Do not repeat the set Schedule";
CM_ SG_ 1447 Enable_Schedule2 "Schedule 2 checkbox enabled";
CM_ SG_ 1447 End_Time_Hr2 "End Time of schedule  2 (hours in 24 hrs. format)";
CM_ SG_ 1447 End_Time_Min2 "End Time of schedule  2(Minutes)";
CM_ SG_ 1447 Schedule_Day2 "Schedule#2 Day for charging or cabin conditioning";
CM_ SG_ 1447 Schedule_Type2 "Type of charging and climate schedule";
CM_ SG_ 1447 Start_Time_Hr2 "Start Time of schedule  2(hours in 24 hrs. format)";
CM_ SG_ 1447 Start_Time_Min2 "Start Time of schedule  2 (minutes)";
CM_ SG_ 1447 Submit_Schedule2 "Schedule 2 submitted";
CM_ SG_ 1453 Batt_CabinPriority3 "Bit to prioritize battery charging or cabin conditioning under schedule 3";
CM_ SG_ 1453 ChargeUntilFull3 "Charge until battery is fully charged with schedule 3";
CM_ SG_ 1453 Do_Not_Repeat3 "Do not repeat the set Schedule";
CM_ SG_ 1453 Enable_Schedule3 "Schedule 3 checkbox enabled";
CM_ SG_ 1453 End_Time_Hr3 "End Time of schedule  3 (hours in 24 hrs. format)";
CM_ SG_ 1453 End_Time_Min3 "End Time of schedule  3 (Minutes)";
CM_ SG_ 1453 Schedule_Day3 "Schedule#3 Day for charging or cabin conditioning";
CM_ SG_ 1453 Schedule_Type3 "Type of charging and climate schedule";
CM_ SG_ 1453 Start_Time_Hr3 "Start Time of schedule  3 (hours in 24 hrs. format)";
CM_ SG_ 1453 Start_Time_Min3 "Start Time of schedule  3 (minutes)";
CM_ SG_ 1453 Submit_Schedule3 "Schedule 3 submitted";
CM_ SG_ 146 SelectedPhoneID "Indicates which paired phone is selected on IPC screen";
CM_ SG_ 146 SMS_PopUp "Used to give information about the Popup-SMS  visualization status";
CM_ SG_ 1468 AudioRepetition "This signal is used to give information about the Audio Repetition selected";
CM_ SG_ 1468 AutoHighBeamEnable "This signal is used to give information about the Auto High Beam feature selected";
CM_ SG_ 1468 AutoParkBrake "This signal is used to give information about the Auto Park Brake selected";
CM_ SG_ 1468 BackLightLevel "Set the dimming level (8 levels possible) for backlight components";
CM_ SG_ 1468 BSDEnable "This signal is used to give information about the Blind Spot Alert feature selected";
CM_ SG_ 1468 CorneringEnable "This signal is used to give information about the Cornering Lights selected";
CM_ SG_ 1468 DistanceUnit "This signal is used to give information about the Distance Unit selected";
CM_ SG_ 1468 DRLEnable "This signal is used to give information about the DRL feature selected";
CM_ SG_ 1468 ExternalLightSensorLevel "This signal is used to give information about the External Light Sensor Level selected";
CM_ SG_ 1468 HourMode "This signal is used to give information about the Hour Mode selected.";
CM_ SG_ 1468 LanguageSelection "This signal is used to give information about the Language selected";
CM_ SG_ 1468 NavRepetition "This signal is used to give information about the Navigation Repetition selected";
CM_ SG_ 1468 PamAlertMode "This signal is used to give information about the PAM Alert Mode selected";
CM_ SG_ 1468 PamChimeVolumeFront "This signal is used to give information about the PAM  Chime Volume selected";
CM_ SG_ 1468 PamChimeVolumeRear "This signal is used to give information about the PAM 8Ch Chime Volume selected";
CM_ SG_ 1468 PassiveEntry "This signal is used to give information about the Passive Entry selected";
CM_ SG_ 1468 PhoneRepetition "This signal is used to give information about the Phone Repetition selected";
CM_ SG_ 1468 RainSensorLevel "This signal is used to give information about the Rain Sensor Level selected";
CM_ SG_ 1468 RemoteDoorUnlock "This signal is used to give information about the Remote Door Unlock selected";
CM_ SG_ 1468 Sdw "This signal is used to give information about the Side Distance Warning feature selected";
CM_ SG_ 1468 SoundHornLock "This signal is used to give information about the Sound Horn with Lock selected";
CM_ SG_ 1468 SoundHornRemoteStart "This signal is used to give information about the Sound Horn with Remote Start selected";
CM_ SG_ 1468 SpeedLockDoorEnable "This signal is used to give information about the Autoclose feature selected";
CM_ SG_ 1468 TelematicSetupACK "Used to give information about the acknowledge of the requested setup changes by telematic module.";
CM_ SG_ 1468 TemperatureUnit "This signal is used to give information about the Temperature Unit selected";
CM_ SG_ 1486 AutoUnlockDoorExit "This signal is used to give information about the Auto Unlock Door on Exit feature selected";
CM_ SG_ 1486 EPB_Maintenance_Fdbk "It indicates the HMI state of the EPB Functionality for the Maintenance Procedure";
CM_ SG_ 1486 EPB_MaintenanceMode "This signal is used to give information about the Maintenance Mode feature selected";
CM_ SG_ 1486 EVConsumptionUnit "This signal is used to give information about the Electrical Consumption Unit selected.";
CM_ SG_ 1486 FlashLightWLock "This signal is used to give information about the Flash Light With Lock selected";
CM_ SG_ 1486 FSFCWPlusActivationMode "This signal is used to give information about the FSFCW Activation Mode setting";
CM_ SG_ 1486 FSFCWPlusSetting "This signal is used to give information about the FSFCW setting";
CM_ SG_ 1486 HeadlightsOffDelay "This signal is used to give information about the Headlights Off Delay selected";
CM_ SG_ 1486 LDW_Intensity "This signal is used to give information about the LDW Intensity selected";
CM_ SG_ 1486 LDW_Sensibility "This signal is used to give information about the LDW Sensibility selected";
CM_ SG_ 1486 PowerLevel "This signal is used to give information about the Power Level selected.";
CM_ SG_ 1486 RecoveryIgnOff "This signal is used to request the ignition off of the vehicle.";
CM_ SG_ 1486 RemStNrmlStEnbl "Setting to allow seat heating and venting for all starts, remote starts, or none";
CM_ SG_ 1486 TSREnable "This signal will be used to indicate if the Traffic Sign Recognition function has been activated via Menu";
CM_ SG_ 1486 TyrePressureUnit "This signal is used to give information about the Tyre Pressure Unit selected";
CM_ SG_ 1294 AutoHold "Auto Hold setting";
CM_ SG_ 1294 Drowsy_Driver_Alert "Drowsy Driver Alert setting";
CM_ SG_ 1294 Speed_Unit "Speed Unit setting";
CM_ SG_ 1485 GreetingLightsLevel "This signal is used to give information about the Greeting Lights selected";
CM_ SG_ 1485 IPC_NavigationMap_Req "IPC navigation map request.";
CM_ SG_ 1485 NavigationMapPopUP "Navigation map popup.";
CM_ SG_ 1485 New_Spd_Zone_Ind "New Speed Zone Indication setting";
CM_ SG_ 1485 SignCaptureMode "Intelligent Speed Mode setting";
CM_ SG_ 1485 Traffic_Sign_Warn "Traffic Sign Warning setting";
CM_ SG_ 1865 ADAS_Meta_CountryCode "This signal indicates the Country Code (Coding based on ISO 3166-1 numeric).";
CM_ SG_ 1865 ADAS_Meta_DrvSide "This signal indicates the Driving Side.";
CM_ SG_ 1865 ADAS_Meta_MapProvider "This signal indicates the Map Provider of current area (map tile, region, country).";
CM_ SG_ 1865 ADAS_Meta_SpdUnits "This signal indicates the Speed Units.";
CM_ SG_ 950 Alert_CHF "This signal indicates which arc shall be displayed in the central hand, front position of the car graphics.";
CM_ SG_ 950 Alert_CHR "This signal indicates which arc shall be displayed in the central hand, rear position of the car graphics.";
CM_ SG_ 950 Alert_LHF "This signal indicates which arc shall be displayed in the left hand, front position of the car graphics.";
CM_ SG_ 950 Alert_LHR "This signal indicates which arc shall be displayed in the left hand, rear position of the car graphics.";
CM_ SG_ 950 Alert_RHF "This signal indicates which arc shall be displayed in the right hand, front position of the car graphics.";
CM_ SG_ 950 Alert_RHR "This signal indicates which arc shall be displayed in the right hand, rear position of the car graphics.";
CM_ SG_ 950 ChimeActivation_LHF "This signal indicates the chime activation request for the left hand, front audio speaker, or rear hardwired buzzer.";
CM_ SG_ 950 ChimeActivation_LHR "This signal indicates the chime activation request for the left hand, rear audio speaker, or rear hardwired buzzer.";
CM_ SG_ 950 ChimeActivation_RHF "This signal indicates the chime activation request for the right hand, front audio speaker, or rear hardwired buzzer.";
CM_ SG_ 950 ChimeActivation_RHR "This signal indicates the chime activation request for the right hand, rear audio speaker, or rear hardwired buzzer.";
CM_ SG_ 950 ChimeRepetitionRate_Front "This signal indicates the repetition rate for the front audio speakers.";
CM_ SG_ 950 ChimeRepetitionRate_Rear "This signal indicates the repetition rate for the rear audio speakers.";
CM_ SG_ 950 ChimeType_Front "This signal indicates the Chime Type for the front audio speakers.";
CM_ SG_ 950 ChimeType_Rear "This signal indicates the Chime Type for the rear audio speakers.";
CM_ SG_ 950 DisplayActivation "This signal indicates the request to display the car graphics layout on the IPC/EVIC screen.";
CM_ SG_ 950 ObstacleInTrajectory_CHF "This signal is used to indicate if the detected obstacle is inside or outside of the vehicle path.";
CM_ SG_ 950 ObstacleInTrajectory_CHR "This signal is used to indicate if the detected obstacle is inside or outside of the vehicle path.";
CM_ SG_ 950 ObstacleInTrajectory_LHF "This signal is used to indicate if the detected obstacle is inside or outside of the vehicle path.";
CM_ SG_ 950 ObstacleInTrajectory_LHR "This signal is used to indicate if the detected obstacle is inside or outside of the vehicle path.";
CM_ SG_ 950 ObstacleInTrajectory_RHF "This signal is used to indicate if the detected obstacle is inside or outside of the vehicle path.";
CM_ SG_ 950 ObstacleInTrajectory_RHR "This signal is used to indicate if the detected obstacle is inside or outside of the vehicle path.";
CM_ SG_ 1282 Radio_Delete_Request "Updates based on user which profile is deleted";
CM_ SG_ 1282 Radio_Profile_Request "Changes the profile based on selection";

BA_DEF_ SG_ "Accuracy" STRING ;
BA_DEF_ SG_ "Event trans." ENUM "Yes","No";
BA_DEF_ SG_ "GenSigStartValue" INT 0 2147483647;
BA_DEF_ SG_ "GenSigInactiveValue" INT 0 2147483647;
BA_DEF_ SG_ "GenSigSendType" ENUM "NotUsed","OnWrite","OnWriteWithRepetition","OnChange","OnChangeWithRepetition","IfActive","IfActiveWithRepetition","NoSigSendType";
BA_DEF_ SG_ "SystemSignalLongSymbol" STRING ;
BA_DEF_ BO_ "DiagRequest" ENUM "No","Yes";
BA_DEF_ BO_ "Period [ms]" INT 0 65535;
BA_DEF_ BO_ "Type" ENUM "P","C","PE","COC","PE_Cntrl","E","E_Cntrl","OC","S","BAF","DC","EM","MM","-";
BA_DEF_ BO_ "DiagResponse" ENUM "No","Yes";
BA_DEF_ BO_ "NmMessage" ENUM "No","Yes";
BA_DEF_ BO_ "GenMsgSendType" ENUM "Cyclic","NotUsed","NotUsed","NotUsed","NotUsed","NotUsed","NotUsed","NotUsed","NoMsgSendType";
BA_DEF_ BO_ "GenMsgTimeoutTime" INT 0 10000;
BA_DEF_ BO_ "GenMsgNrOfRepetition" INT 0 255;
BA_DEF_ BO_ "GenMsgILSupport" ENUM "No","Yes";
BA_DEF_ BO_ "GenMsgStartDelayTime" INT 0 65535;
BA_DEF_ BO_ "GenMsgCycleTimeFast" INT 0 65535;
BA_DEF_ BO_ "GenMsgCycleTime" INT 0 65535;
BA_DEF_ BO_ "GenMsgDelayTime" INT 0 65535;
BA_DEF_ BO_ "DiagState" ENUM "No","Yes";
BA_DEF_ BU_ "NodeLayerModules" STRING ;
BA_DEF_ BU_ "Description" STRING ;
BA_DEF_ BU_ "NmStationAddress" HEX 0 255;
BA_DEF_ BU_ "NmNode" ENUM "No","Yes";
BA_DEF_ BU_ "ILUsed" ENUM "No","Yes";
BA_DEF_ BU_ "TpOwnSystemEcuNumber" HEX 0 255;
BA_DEF_ BU_ "NmNodeType" ENUM "kMaster","kSlave15","kSlave30","none";
BA_DEF_ BU_ "NwmNodeType" ENUM "kMaster","kSlave15","kSlave30","none";
BA_DEF_ "Manufacturer" STRING ;
BA_DEF_ "NmType" STRING ;
BA_DEF_ "BusType" STRING ;
BA_DEF_ "Baudrate" INT 0 1000000;
BA_DEF_ "DBName" STRING ;
BA_DEF_ "Version" HEX 0 255;
BA_DEF_ "VersionWeek" INT 0 53;
BA_DEF_ "VersionYear" INT 0 99;
BA_DEF_DEF_ "Accuracy" "";
BA_DEF_DEF_ "Event trans." "No";
BA_DEF_DEF_ "GenSigStartValue" 0;
BA_DEF_DEF_ "GenSigInactiveValue" 0;
BA_DEF_DEF_ "GenSigSendType" "NoSigSendType";
BA_DEF_DEF_ "SystemSignalLongSymbol" "";
BA_DEF_DEF_ "DiagRequest" "No";
BA_DEF_DEF_ "Period [ms]" 0;
BA_DEF_DEF_ "Type" "-";
BA_DEF_DEF_ "DiagResponse" "No";
BA_DEF_DEF_ "NmMessage" "No";
BA_DEF_DEF_ "GenMsgSendType" "NoMsgSendType";
BA_DEF_DEF_ "GenMsgTimeoutTime" 0;
BA_DEF_DEF_ "GenMsgNrOfRepetition" 0;
BA_DEF_DEF_ "GenMsgILSupport" "No";
BA_DEF_DEF_ "GenMsgStartDelayTime" 0;
BA_DEF_DEF_ "GenMsgCycleTimeFast" 0;
BA_DEF_DEF_ "GenMsgCycleTime" 0;
BA_DEF_DEF_ "GenMsgDelayTime" 0;
BA_DEF_DEF_ "DiagState" "No";
BA_DEF_DEF_ "NodeLayerModules" "Osek_TP.dll";
BA_DEF_DEF_ "Description" "";
BA_DEF_DEF_ "NmStationAddress" 0;
BA_DEF_DEF_ "NmNode" "Yes";
BA_DEF_DEF_ "ILUsed" "Yes";
BA_DEF_DEF_ "TpOwnSystemEcuNumber" 0;
BA_DEF_DEF_ "NmNodeType" "none";
BA_DEF_DEF_ "NwmNodeType" "none";
BA_DEF_DEF_ "Manufacturer" "Fiat";
BA_DEF_DEF_ "NmType" "";
BA_DEF_DEF_ "BusType" "CAN";
BA_DEF_DEF_ "Baudrate" 500000;
BA_DEF_DEF_ "DBName" "CAN";
BA_DEF_DEF_ "Version" 160;
BA_DEF_DEF_ "VersionWeek" 36;
BA_DEF_DEF_ "VersionYear" 20;
BA_ "NmType" "FIAT";
BA_ "Baudrate" 125000;
BA_ "DBName" "CAN_BH_Vehicle";
BA_ "Description" BU_ AMP "Amplifier";
BA_ "NmStationAddress" BU_ AMP 46;
BA_ "TpOwnSystemEcuNumber" BU_ AMP 131;
BA_ "NmNodeType" BU_ AMP 2;
BA_ "NwmNodeType" BU_ AMP 2;
BA_ "Description" BU_ BCM "Body Control Module";
BA_ "TpOwnSystemEcuNumber" BU_ BCM 64;
BA_ "NmNodeType" BU_ BCM 0;
BA_ "NwmNodeType" BU_ BCM 0;
BA_ "Description" BU_ DCSD "Disassociated Center Stack Display";
BA_ "NmStationAddress" BU_ DCSD 131;
BA_ "TpOwnSystemEcuNumber" BU_ DCSD 106;
BA_ "NmNodeType" BU_ DCSD 2;
BA_ "NwmNodeType" BU_ DCSD 2;
BA_ "Description" BU_ DIAG_TEST "Diagnostic Tester";
BA_ "NmNode" BU_ DIAG_TEST 0;
BA_ "Description" BU_ DTV "Digital TeleVision";
BA_ "NmStationAddress" BU_ DTV 100;
BA_ "TpOwnSystemEcuNumber" BU_ DTV 136;
BA_ "Description" BU_ ECC "Electronic Climate Control";
BA_ "NmStationAddress" BU_ ECC 10;
BA_ "TpOwnSystemEcuNumber" BU_ ECC 152;
BA_ "NmNodeType" BU_ ECC 1;
BA_ "NwmNodeType" BU_ ECC 1;
BA_ "Description" BU_ EMCM "Entertainment Multimedia Control Module";
BA_ "NmStationAddress" BU_ EMCM 103;
BA_ "TpOwnSystemEcuNumber" BU_ EMCM 217;
BA_ "NmNodeType" BU_ EMCM 2;
BA_ "NwmNodeType" BU_ EMCM 2;
BA_ "Description" BU_ ETM "Entertainment Telematic Module";
BA_ "NmStationAddress" BU_ ETM 36;
BA_ "TpOwnSystemEcuNumber" BU_ ETM 135;
BA_ "NmNodeType" BU_ ETM 2;
BA_ "NwmNodeType" BU_ ETM 2;
BA_ "Description" BU_ HCPM "HVAC Control Panel Module";
BA_ "NmStationAddress" BU_ HCPM 50;
BA_ "TpOwnSystemEcuNumber" BU_ HCPM 133;
BA_ "NmNodeType" BU_ HCPM 1;
BA_ "NwmNodeType" BU_ HCPM 1;
BA_ "Description" BU_ IPC "Instrument Panel Cluster";
BA_ "NmStationAddress" BU_ IPC 3;
BA_ "TpOwnSystemEcuNumber" BU_ IPC 96;
BA_ "NmNodeType" BU_ IPC 2;
BA_ "NwmNodeType" BU_ IPC 2;
BA_ "Description" BU_ LSMD "Latch Smart Module Driver";
BA_ "NmStationAddress" BU_ LSMD 139;
BA_ "TpOwnSystemEcuNumber" BU_ LSMD 84;
BA_ "NmNodeType" BU_ LSMD 2;
BA_ "NwmNodeType" BU_ LSMD 2;
BA_ "Description" BU_ LSMP "Latch Smart Module Passenger";
BA_ "NmStationAddress" BU_ LSMP 140;
BA_ "TpOwnSystemEcuNumber" BU_ LSMP 85;
BA_ "NmNodeType" BU_ LSMP 2;
BA_ "NwmNodeType" BU_ LSMP 2;
BA_ "Description" BU_ LTM "Low level Telematic Module";
BA_ "NmStationAddress" BU_ LTM 36;
BA_ "TpOwnSystemEcuNumber" BU_ LTM 135;
BA_ "NmNodeType" BU_ LTM 2;
BA_ "NwmNodeType" BU_ LTM 2;
BA_ "Description" BU_ RRM "Radio Receiver Module";
BA_ "NmStationAddress" BU_ RRM 5;
BA_ "TpOwnSystemEcuNumber" BU_ RRM 130;
BA_ "NmNodeType" BU_ RRM 1;
BA_ "NwmNodeType" BU_ RRM 1;
BA_ "Description" BU_ TBM "Telematic Box Module";
BA_ "NmStationAddress" BU_ TBM 35;
BA_ "TpOwnSystemEcuNumber" BU_ TBM 198;
BA_ "NmNodeType" BU_ TBM 2;
BA_ "NwmNodeType" BU_ TBM 2;
BA_ "Type" BO_ 1985 8;
BA_ "GenMsgNrOfRepetition" BO_ 1985 5;
BA_ "GenMsgILSupport" BO_ 1985 1;
BA_ "GenMsgCycleTimeFast" BO_ 1985 500;
BA_ "GenMsgDelayTime" BO_ 1985 500;
BA_ "Period [ms]" BO_ 1884 1000;
BA_ "Type" BO_ 1884 1;
BA_ "GenMsgSendType" BO_ 1884 0;
BA_ "GenMsgTimeoutTime" BO_ 1884 2500;
BA_ "GenMsgILSupport" BO_ 1884 1;
BA_ "GenMsgStartDelayTime" BO_ 1884 400;
BA_ "GenMsgCycleTime" BO_ 1884 1000;
BA_ "Period [ms]" BO_ 1474 1000;
BA_ "Type" BO_ 1474 3;
BA_ "GenMsgSendType" BO_ 1474 0;
BA_ "GenMsgILSupport" BO_ 1474 1;
BA_ "GenMsgStartDelayTime" BO_ 1474 400;
BA_ "GenMsgCycleTime" BO_ 1474 1000;
BA_ "GenMsgDelayTime" BO_ 1474 20;
BA_ "Period [ms]" BO_ 1506 1000;
BA_ "Type" BO_ 1506 3;
BA_ "GenMsgSendType" BO_ 1506 0;
BA_ "GenMsgTimeoutTime" BO_ 1506 2500;
BA_ "GenMsgNrOfRepetition" BO_ 1506 3;
BA_ "GenMsgILSupport" BO_ 1506 1;
BA_ "GenMsgStartDelayTime" BO_ 1506 400;
BA_ "GenMsgCycleTimeFast" BO_ 1506 20;
BA_ "GenMsgCycleTime" BO_ 1506 1000;
BA_ "GenMsgDelayTime" BO_ 1506 20;
BA_ "Type" BO_ 160 8;
BA_ "GenMsgTimeoutTime" BO_ 160 2500;
BA_ "GenMsgNrOfRepetition" BO_ 160 3;
BA_ "GenMsgILSupport" BO_ 160 1;
BA_ "GenMsgCycleTimeFast" BO_ 160 250;
BA_ "GenMsgDelayTime" BO_ 160 20;
BA_ "Type" BO_ 2651930624 8;
BA_ "GenMsgTimeoutTime" BO_ 2651930624 2500;
BA_ "GenMsgILSupport" BO_ 2651930624 1;
BA_ "Type" BO_ 2651930670 11;
BA_ "GenMsgTimeoutTime" BO_ 2651930670 2500;
BA_ "GenMsgILSupport" BO_ 2651930670 1;
BA_ "Type" BO_ 2651930674 11;
BA_ "GenMsgTimeoutTime" BO_ 2651930674 2500;
BA_ "GenMsgILSupport" BO_ 2651930674 1;
BA_ "Type" BO_ 2651930634 11;
BA_ "GenMsgTimeoutTime" BO_ 2651930634 2500;
BA_ "GenMsgILSupport" BO_ 2651930634 1;
BA_ "Type" BO_ 2651930727 11;
BA_ "GenMsgTimeoutTime" BO_ 2651930727 2500;
BA_ "GenMsgILSupport" BO_ 2651930727 1;
BA_ "Type" BO_ 2651930763 11;
BA_ "GenMsgTimeoutTime" BO_ 2651930763 2500;
BA_ "GenMsgILSupport" BO_ 2651930763 1;
BA_ "Type" BO_ 2651930764 11;
BA_ "GenMsgTimeoutTime" BO_ 2651930764 2500;
BA_ "GenMsgILSupport" BO_ 2651930764 1;
BA_ "Type" BO_ 2651930660 11;
BA_ "GenMsgTimeoutTime" BO_ 2651930660 2500;
BA_ "GenMsgILSupport" BO_ 2651930660 1;
BA_ "Type" BO_ 134 8;
BA_ "GenMsgTimeoutTime" BO_ 134 2500;
BA_ "GenMsgNrOfRepetition" BO_ 134 3;
BA_ "GenMsgILSupport" BO_ 134 1;
BA_ "GenMsgCycleTimeFast" BO_ 134 250;
BA_ "GenMsgDelayTime" BO_ 134 20;
BA_ "Period [ms]" BO_ 1050 1000;
BA_ "Type" BO_ 1050 10;
BA_ "GenMsgSendType" BO_ 1050 0;
BA_ "GenMsgILSupport" BO_ 1050 1;
BA_ "GenMsgCycleTimeFast" BO_ 1050 100;
BA_ "GenMsgCycleTime" BO_ 1050 1000;
BA_ "GenMsgDelayTime" BO_ 1050 100;
BA_ "Period [ms]" BO_ 224 100;
BA_ "Type" BO_ 224 3;
BA_ "GenMsgSendType" BO_ 224 0;
BA_ "GenMsgILSupport" BO_ 224 1;
BA_ "GenMsgStartDelayTime" BO_ 224 20;
BA_ "GenMsgCycleTime" BO_ 224 100;
BA_ "GenMsgDelayTime" BO_ 224 20;
BA_ "Period [ms]" BO_ 208 1000;
BA_ "Type" BO_ 208 3;
BA_ "GenMsgSendType" BO_ 208 0;
BA_ "GenMsgTimeoutTime" BO_ 208 2500;
BA_ "GenMsgILSupport" BO_ 208 1;
BA_ "GenMsgStartDelayTime" BO_ 208 10;
BA_ "GenMsgCycleTime" BO_ 208 1000;
BA_ "GenMsgDelayTime" BO_ 208 20;
BA_ "Period [ms]" BO_ 1498 1000;
BA_ "Type" BO_ 1498 3;
BA_ "GenMsgSendType" BO_ 1498 0;
BA_ "GenMsgTimeoutTime" BO_ 1498 2500;
BA_ "GenMsgILSupport" BO_ 1498 1;
BA_ "GenMsgStartDelayTime" BO_ 1498 400;
BA_ "GenMsgCycleTime" BO_ 1498 1000;
BA_ "GenMsgDelayTime" BO_ 1498 20;
BA_ "Type" BO_ 177 8;
BA_ "GenMsgILSupport" BO_ 177 1;
BA_ "GenMsgDelayTime" BO_ 177 100;
BA_ "Period [ms]" BO_ 1478 1000;
BA_ "Type" BO_ 1478 3;
BA_ "GenMsgSendType" BO_ 1478 0;
BA_ "GenMsgTimeoutTime" BO_ 1478 2500;
BA_ "GenMsgILSupport" BO_ 1478 1;
BA_ "GenMsgStartDelayTime" BO_ 1478 400;
BA_ "GenMsgCycleTime" BO_ 1478 1000;
BA_ "GenMsgDelayTime" BO_ 1478 20;
BA_ "Type" BO_ 2564554481 8;
BA_ "GenMsgTimeoutTime" BO_ 2564554481 2500;
BA_ "DiagState" BO_ 2564554481 1;
BA_ "DiagRequest" BO_ 2564457457 1;
BA_ "Type" BO_ 2564457457 8;
BA_ "DiagRequest" BO_ 2564457969 1;
BA_ "Type" BO_ 2564457969 8;
BA_ "DiagRequest" BO_ 2564462833 1;
BA_ "Type" BO_ 2564462833 8;
BA_ "DiagRequest" BO_ 2564451057 1;
BA_ "Type" BO_ 2564451057 8;
BA_ "DiagRequest" BO_ 2564479473 1;
BA_ "Type" BO_ 2564479473 8;
BA_ "DiagRequest" BO_ 2564445425 1;
BA_ "Type" BO_ 2564445425 8;
BA_ "DiagRequest" BO_ 2564445681 1;
BA_ "Type" BO_ 2564445681 8;
BA_ "DiagRequest" BO_ 2564458481 1;
BA_ "Type" BO_ 2564458481 8;
BA_ "Type" BO_ 2564485507 8;
BA_ "DiagResponse" BO_ 2564485507 1;
BA_ "Type" BO_ 2564485509 8;
BA_ "DiagResponse" BO_ 2564485509 1;
BA_ "Type" BO_ 2564485528 8;
BA_ "DiagResponse" BO_ 2564485528 1;
BA_ "Type" BO_ 2564485482 8;
BA_ "DiagResponse" BO_ 2564485482 1;
BA_ "Type" BO_ 2564485593 8;
BA_ "DiagResponse" BO_ 2564485593 1;
BA_ "Type" BO_ 2564485460 8;
BA_ "DiagResponse" BO_ 2564485460 1;
BA_ "Type" BO_ 2564485461 8;
BA_ "DiagResponse" BO_ 2564485461 1;
BA_ "Type" BO_ 2564485511 8;
BA_ "DiagResponse" BO_ 2564485511 1;
BA_ "Period [ms]" BO_ 1445 1000;
BA_ "Type" BO_ 1445 3;
BA_ "GenMsgSendType" BO_ 1445 0;
BA_ "GenMsgILSupport" BO_ 1445 1;
BA_ "GenMsgCycleTime" BO_ 1445 1000;
BA_ "Period [ms]" BO_ 1422 1000;
BA_ "Type" BO_ 1422 3;
BA_ "GenMsgSendType" BO_ 1422 0;
BA_ "GenMsgTimeoutTime" BO_ 1422 2500;
BA_ "GenMsgNrOfRepetition" BO_ 1422 3;
BA_ "GenMsgILSupport" BO_ 1422 1;
BA_ "GenMsgCycleTimeFast" BO_ 1422 20;
BA_ "GenMsgCycleTime" BO_ 1422 1000;
BA_ "GenMsgDelayTime" BO_ 1422 20;
BA_ "Period [ms]" BO_ 1424 1000;
BA_ "Type" BO_ 1424 3;
BA_ "GenMsgSendType" BO_ 1424 0;
BA_ "GenMsgTimeoutTime" BO_ 1424 2500;
BA_ "GenMsgNrOfRepetition" BO_ 1424 3;
BA_ "GenMsgILSupport" BO_ 1424 1;
BA_ "GenMsgCycleTimeFast" BO_ 1424 20;
BA_ "GenMsgCycleTime" BO_ 1424 1000;
BA_ "GenMsgDelayTime" BO_ 1424 20;
BA_ "Period [ms]" BO_ 852 250;
BA_ "Type" BO_ 852 3;
BA_ "GenMsgSendType" BO_ 852 0;
BA_ "GenMsgILSupport" BO_ 852 1;
BA_ "GenMsgStartDelayTime" BO_ 852 60;
BA_ "GenMsgCycleTime" BO_ 852 250;
BA_ "GenMsgDelayTime" BO_ 852 20;
BA_ "Type" BO_ 128 8;
BA_ "GenMsgTimeoutTime" BO_ 128 2500;
BA_ "GenMsgNrOfRepetition" BO_ 128 3;
BA_ "GenMsgILSupport" BO_ 128 1;
BA_ "GenMsgCycleTimeFast" BO_ 128 1000;
BA_ "GenMsgDelayTime" BO_ 128 20;
BA_ "Period [ms]" BO_ 1896 1000;
BA_ "Type" BO_ 1896 1;
BA_ "GenMsgSendType" BO_ 1896 0;
BA_ "GenMsgTimeoutTime" BO_ 1896 2500;
BA_ "GenMsgILSupport" BO_ 1896 1;
BA_ "GenMsgStartDelayTime" BO_ 1896 400;
BA_ "GenMsgCycleTime" BO_ 1896 1000;
BA_ "GenMsgDelayTime" BO_ 1896 20;
BA_ "Type" BO_ 1270 11;
BA_ "GenMsgILSupport" BO_ 1270 1;
BA_ "Type" BO_ 1442 11;
BA_ "GenMsgILSupport" BO_ 1442 1;
BA_ "Type" BO_ 1443 11;
BA_ "GenMsgTimeoutTime" BO_ 1443 2500;
BA_ "GenMsgILSupport" BO_ 1443 1;
BA_ "DiagRequest" BO_ 2147583473 1;
BA_ "Type" BO_ 2147583473 8;
BA_ "DiagRequest" BO_ 2147582961 1;
BA_ "Type" BO_ 2147582961 8;
BA_ "DiagRequest" BO_ 2147588337 1;
BA_ "Type" BO_ 2147588337 8;
BA_ "DiagRequest" BO_ 2147576561 1;
BA_ "Type" BO_ 2147576561 8;
BA_ "DiagRequest" BO_ 2147584753 1;
BA_ "Type" BO_ 2147584753 8;
BA_ "DiagRequest" BO_ 2147570929 1;
BA_ "Type" BO_ 2147570929 8;
BA_ "DiagRequest" BO_ 2147571185 1;
BA_ "Type" BO_ 2147571185 8;
BA_ "DiagRequest" BO_ 2147583985 1;
BA_ "Type" BO_ 2147583985 8;
BA_ "Period [ms]" BO_ 1864 1000;
BA_ "Type" BO_ 1864 1;
BA_ "GenMsgSendType" BO_ 1864 0;
BA_ "GenMsgTimeoutTime" BO_ 1864 2500;
BA_ "GenMsgILSupport" BO_ 1864 1;
BA_ "GenMsgStartDelayTime" BO_ 1864 400;
BA_ "GenMsgCycleTime" BO_ 1864 1000;
BA_ "Type" BO_ 142 11;
BA_ "GenMsgTimeoutTime" BO_ 142 2500;
BA_ "GenMsgILSupport" BO_ 142 1;
BA_ "GenMsgDelayTime" BO_ 142 20;
BA_ "Period [ms]" BO_ 1463 1000;
BA_ "Type" BO_ 1463 3;
BA_ "GenMsgSendType" BO_ 1463 0;
BA_ "GenMsgILSupport" BO_ 1463 1;
BA_ "GenMsgCycleTime" BO_ 1463 1000;
BA_ "GenMsgDelayTime" BO_ 1463 20;
BA_ "Period [ms]" BO_ 1447 1000;
BA_ "Type" BO_ 1447 3;
BA_ "GenMsgSendType" BO_ 1447 0;
BA_ "GenMsgILSupport" BO_ 1447 1;
BA_ "GenMsgCycleTime" BO_ 1447 1000;
BA_ "GenMsgDelayTime" BO_ 1447 20;
BA_ "Period [ms]" BO_ 1453 1000;
BA_ "Type" BO_ 1453 3;
BA_ "GenMsgSendType" BO_ 1453 0;
BA_ "GenMsgILSupport" BO_ 1453 1;
BA_ "GenMsgCycleTime" BO_ 1453 1000;
BA_ "GenMsgDelayTime" BO_ 1453 20;
BA_ "Type" BO_ 138 12;
BA_ "GenMsgILSupport" BO_ 138 1;
BA_ "GenMsgDelayTime" BO_ 138 20;
BA_ "Type" BO_ 986 11;
BA_ "GenMsgILSupport" BO_ 986 1;
BA_ "GenMsgDelayTime" BO_ 986 20;
BA_ "Type" BO_ 146 7;
BA_ "GenMsgILSupport" BO_ 146 1;
BA_ "GenMsgDelayTime" BO_ 146 20;
BA_ "Period [ms]" BO_ 1468 1000;
BA_ "Type" BO_ 1468 3;
BA_ "GenMsgSendType" BO_ 1468 0;
BA_ "GenMsgILSupport" BO_ 1468 1;
BA_ "GenMsgStartDelayTime" BO_ 1468 70;
BA_ "GenMsgCycleTime" BO_ 1468 1000;
BA_ "GenMsgDelayTime" BO_ 1468 50;
BA_ "Period [ms]" BO_ 1486 1000;
BA_ "Type" BO_ 1486 3;
BA_ "GenMsgSendType" BO_ 1486 0;
BA_ "GenMsgILSupport" BO_ 1486 1;
BA_ "GenMsgStartDelayTime" BO_ 1486 400;
BA_ "GenMsgCycleTime" BO_ 1486 1000;
BA_ "GenMsgDelayTime" BO_ 1486 50;
BA_ "Period [ms]" BO_ 1294 1000;
BA_ "Type" BO_ 1294 3;
BA_ "GenMsgSendType" BO_ 1294 0;
BA_ "GenMsgILSupport" BO_ 1294 1;
BA_ "GenMsgStartDelayTime" BO_ 1294 40;
BA_ "GenMsgCycleTime" BO_ 1294 1000;
BA_ "GenMsgDelayTime" BO_ 1294 50;
BA_ "Period [ms]" BO_ 1485 1000;
BA_ "Type" BO_ 1485 3;
BA_ "GenMsgSendType" BO_ 1485 0;
BA_ "GenMsgILSupport" BO_ 1485 1;
BA_ "GenMsgStartDelayTime" BO_ 1485 380;
BA_ "GenMsgCycleTime" BO_ 1485 1000;
BA_ "GenMsgDelayTime" BO_ 1485 50;
BA_ "Period [ms]" BO_ 1865 5000;
BA_ "Type" BO_ 1865 1;
BA_ "GenMsgSendType" BO_ 1865 0;
BA_ "GenMsgILSupport" BO_ 1865 1;
BA_ "GenMsgCycleTime" BO_ 1865 5000;
BA_ "GenMsgDelayTime" BO_ 1865 50;
BA_ "Type" BO_ 2654208046 11;
BA_ "NmMessage" BO_ 2654208046 1;
BA_ "GenMsgTimeoutTime" BO_ 2654208046 2500;
BA_ "GenMsgDelayTime" BO_ 2654208046 500;
BA_ "Period [ms]" BO_ 2654208000 1000;
BA_ "Type" BO_ 2654208000 3;
BA_ "NmMessage" BO_ 2654208000 1;
BA_ "GenMsgSendType" BO_ 2654208000 0;
BA_ "GenMsgTimeoutTime" BO_ 2654208000 2500;
BA_ "GenMsgCycleTime" BO_ 2654208000 1000;
BA_ "Type" BO_ 2654208050 11;
BA_ "NmMessage" BO_ 2654208050 1;
BA_ "GenMsgTimeoutTime" BO_ 2654208050 2500;
BA_ "GenMsgDelayTime" BO_ 2654208050 500;
BA_ "Type" BO_ 2654208010 11;
BA_ "NmMessage" BO_ 2654208010 1;
BA_ "GenMsgTimeoutTime" BO_ 2654208010 2500;
BA_ "GenMsgDelayTime" BO_ 2654208010 500;
BA_ "Type" BO_ 2654208131 11;
BA_ "NmMessage" BO_ 2654208131 1;
BA_ "GenMsgTimeoutTime" BO_ 2654208131 2500;
BA_ "GenMsgDelayTime" BO_ 2654208131 500;
BA_ "Type" BO_ 2654208103 11;
BA_ "NmMessage" BO_ 2654208103 1;
BA_ "GenMsgTimeoutTime" BO_ 2654208103 2500;
BA_ "GenMsgDelayTime" BO_ 2654208103 500;
BA_ "Type" BO_ 2654208003 11;
BA_ "NmMessage" BO_ 2654208003 1;
BA_ "GenMsgTimeoutTime" BO_ 2654208003 2500;
BA_ "GenMsgDelayTime" BO_ 2654208003 500;
BA_ "Type" BO_ 2654208139 11;
BA_ "NmMessage" BO_ 2654208139 1;
BA_ "GenMsgTimeoutTime" BO_ 2654208139 2500;
BA_ "GenMsgDelayTime" BO_ 2654208139 500;
BA_ "Type" BO_ 2654208140 11;
BA_ "NmMessage" BO_ 2654208140 1;
BA_ "GenMsgTimeoutTime" BO_ 2654208140 2500;
BA_ "GenMsgDelayTime" BO_ 2654208140 500;
BA_ "Type" BO_ 2654208035 11;
BA_ "NmMessage" BO_ 2654208035 1;
BA_ "GenMsgTimeoutTime" BO_ 2654208035 2500;
BA_ "GenMsgDelayTime" BO_ 2654208035 500;
BA_ "Type" BO_ 2654208036 11;
BA_ "NmMessage" BO_ 2654208036 1;
BA_ "GenMsgTimeoutTime" BO_ 2654208036 2500;
BA_ "GenMsgDelayTime" BO_ 2654208036 500;
BA_ "Type" BO_ 950 11;
BA_ "GenMsgILSupport" BO_ 950 1;
BA_ "Period [ms]" BO_ 1282 1000;
BA_ "Type" BO_ 1282 3;
BA_ "GenMsgSendType" BO_ 1282 0;
BA_ "GenMsgTimeoutTime" BO_ 1282 2500;
BA_ "GenMsgILSupport" BO_ 1282 1;
BA_ "GenMsgCycleTime" BO_ 1282 1000;
BA_ "GenMsgDelayTime" BO_ 1282 20;
BA_ "Event trans." SG_ 1985 VehicleArchitectureInfo 0;
BA_ "GenSigSendType" SG_ 1985 VehicleArchitectureInfo 2;
BA_ "Accuracy" SG_ 1884 IgnitionOnCounter "-";
BA_ "Accuracy" SG_ 1474 AbortCrankingAtc "-";
BA_ "Event trans." SG_ 1474 AbortCrankingAtc 0;
BA_ "GenSigSendType" SG_ 1474 AbortCrankingAtc 3;
BA_ "Accuracy" SG_ 1474 BonnetAlarmCauseSts "-";
BA_ "Event trans." SG_ 1474 BonnetAlarmCauseSts 0;
BA_ "GenSigSendType" SG_ 1474 BonnetAlarmCauseSts 3;
BA_ "Accuracy" SG_ 1474 DoorsAlarmCauseSts "-";
BA_ "Event trans." SG_ 1474 DoorsAlarmCauseSts 0;
BA_ "GenSigSendType" SG_ 1474 DoorsAlarmCauseSts 3;
BA_ "Accuracy" SG_ 1474 ElectricalAlarmCauseSts "-";
BA_ "Event trans." SG_ 1474 ElectricalAlarmCauseSts 0;
BA_ "GenSigSendType" SG_ 1474 ElectricalAlarmCauseSts 3;
BA_ "Event trans." SG_ 1474 HeadlightsDelayModeActive 0;
BA_ "GenSigSendType" SG_ 1474 HeadlightsDelayModeActive 3;
BA_ "Accuracy" SG_ 1474 PanicModeActive "-";
BA_ "Event trans." SG_ 1474 PanicModeActive 0;
BA_ "GenSigSendType" SG_ 1474 PanicModeActive 3;
BA_ "Accuracy" SG_ 1474 TrunkAlarmCauseSts "-";
BA_ "Event trans." SG_ 1474 TrunkAlarmCauseSts 0;
BA_ "GenSigSendType" SG_ 1474 TrunkAlarmCauseSts 3;
BA_ "Accuracy" SG_ 1506 DoorsDeadLockReq "-";
BA_ "Event trans." SG_ 1506 DoorsDeadLockReq 0;
BA_ "GenSigSendType" SG_ 1506 DoorsDeadLockReq 4;
BA_ "Accuracy" SG_ 1506 DoorsLockUnlockReq "-";
BA_ "Event trans." SG_ 1506 DoorsLockUnlockReq 0;
BA_ "GenSigSendType" SG_ 1506 DoorsLockUnlockReq 4;
BA_ "Accuracy" SG_ 1506 DoorsSts "-";
BA_ "Event trans." SG_ 1506 DoorsSts 0;
BA_ "GenSigSendType" SG_ 1506 DoorsSts 4;
BA_ "Accuracy" SG_ 1506 FPSSts "-";
BA_ "Event trans." SG_ 1506 FPSSts 0;
BA_ "GenSigSendType" SG_ 1506 FPSSts 4;
BA_ "Accuracy" SG_ 1506 InternalReleaseLightReq "-";
BA_ "Event trans." SG_ 1506 InternalReleaseLightReq 0;
BA_ "GenSigSendType" SG_ 1506 InternalReleaseLightReq 4;
BA_ "Accuracy" SG_ 1506 LockUnlockRequestor "-";
BA_ "Event trans." SG_ 1506 LockUnlockRequestor 0;
BA_ "GenSigSendType" SG_ 1506 LockUnlockRequestor 4;
BA_ "Accuracy" SG_ 1506 LockUnlockVehicleSts "-";
BA_ "Event trans." SG_ 1506 LockUnlockVehicleSts 0;
BA_ "GenSigSendType" SG_ 1506 LockUnlockVehicleSts 4;
BA_ "Accuracy" SG_ 1506 PhoneReminderIndication "-";
BA_ "Event trans." SG_ 1506 PhoneReminderIndication 0;
BA_ "GenSigSendType" SG_ 1506 PhoneReminderIndication 3;
BA_ "Accuracy" SG_ 1506 RoofSts "-";
BA_ "GenSigStartValue" SG_ 1506 RoofSts 7;
BA_ "Accuracy" SG_ 1506 WirelessPadSts "-";
BA_ "Event trans." SG_ 1506 WirelessPadSts 0;
BA_ "GenSigSendType" SG_ 1506 WirelessPadSts 3;
BA_ "Accuracy" SG_ 160 BCMFpsCommand "-";
BA_ "Event trans." SG_ 160 BCMFpsCommand 0;
BA_ "GenSigSendType" SG_ 160 BCMFpsCommand 2;
BA_ "Accuracy" SG_ 160 BCMFpsConfirm "-";
BA_ "Event trans." SG_ 160 BCMFpsConfirm 0;
BA_ "GenSigStartValue" SG_ 160 BCMFpsConfirm 1;
BA_ "GenSigSendType" SG_ 160 BCMFpsConfirm 2;
BA_ "Accuracy" SG_ 160 BCMFpsFailSts "-";
BA_ "Event trans." SG_ 160 BCMFpsFailSts 0;
BA_ "GenSigSendType" SG_ 160 BCMFpsFailSts 2;
BA_ "Event trans." SG_ 2651930624 Digit_01 0;
BA_ "GenSigSendType" SG_ 2651930624 Digit_01 1;
BA_ "Accuracy" SG_ 2651930670 Digit_01_AMP "-";
BA_ "Event trans." SG_ 2651930670 Digit_01_AMP 0;
BA_ "GenSigSendType" SG_ 2651930670 Digit_01_AMP 1;
BA_ "Accuracy" SG_ 2651930670 Digit_02_AMP "-";
BA_ "Accuracy" SG_ 2651930670 Digit_03_AMP "-";
BA_ "Accuracy" SG_ 2651930670 Digit_04_AMP "-";
BA_ "Accuracy" SG_ 2651930670 Digit_05_AMP "-";
BA_ "Accuracy" SG_ 2651930670 Digit_06_AMP "-";
BA_ "Accuracy" SG_ 2651930670 Digit_07_AMP "-";
BA_ "Accuracy" SG_ 2651930670 Digit_08_AMP "-";
BA_ "Accuracy" SG_ 2651930670 Digit_09_AMP "-";
BA_ "Accuracy" SG_ 2651930670 Digit_10_AMP "-";
BA_ "Accuracy" SG_ 2651930670 Digit_11_AMP "-";
BA_ "Accuracy" SG_ 2651930674 Digit_01_CStack "-";
BA_ "Event trans." SG_ 2651930674 Digit_01_CStack 0;
BA_ "GenSigSendType" SG_ 2651930674 Digit_01_CStack 1;
BA_ "Accuracy" SG_ 2651930674 Digit_02_CStack "-";
BA_ "Accuracy" SG_ 2651930674 Digit_03_CStack "-";
BA_ "Accuracy" SG_ 2651930674 Digit_04_CStack "-";
BA_ "Accuracy" SG_ 2651930674 Digit_05_CStack "-";
BA_ "Accuracy" SG_ 2651930674 Digit_06_CStack "-";
BA_ "Accuracy" SG_ 2651930674 Digit_07_CStack "-";
BA_ "Accuracy" SG_ 2651930674 Digit_08_CStack "-";
BA_ "Accuracy" SG_ 2651930674 Digit_09_CStack "-";
BA_ "Accuracy" SG_ 2651930674 Digit_10_CStack "-";
BA_ "Accuracy" SG_ 2651930674 Digit_11_CStack "-";
BA_ "Accuracy" SG_ 2651930634 Digit_01_CLM "-";
BA_ "Event trans." SG_ 2651930634 Digit_01_CLM 0;
BA_ "GenSigSendType" SG_ 2651930634 Digit_01_CLM 1;
BA_ "Accuracy" SG_ 2651930634 Digit_02_CLM "-";
BA_ "Accuracy" SG_ 2651930634 Digit_03_CLM "-";
BA_ "Accuracy" SG_ 2651930634 Digit_04_CLM "-";
BA_ "Accuracy" SG_ 2651930634 Digit_05_CLM "-";
BA_ "Accuracy" SG_ 2651930634 Digit_06_CLM "-";
BA_ "Accuracy" SG_ 2651930634 Digit_07_CLM "-";
BA_ "Accuracy" SG_ 2651930634 Digit_08_CLM "-";
BA_ "Accuracy" SG_ 2651930634 Digit_09_CLM "-";
BA_ "Accuracy" SG_ 2651930634 Digit_10_CLM "-";
BA_ "Accuracy" SG_ 2651930634 Digit_11_CLM "-";
BA_ "Accuracy" SG_ 2651930727 Digit_01_EMCM "-";
BA_ "Event trans." SG_ 2651930727 Digit_01_EMCM 0;
BA_ "GenSigSendType" SG_ 2651930727 Digit_01_EMCM 1;
BA_ "Accuracy" SG_ 2651930727 Digit_02_EMCM "-";
BA_ "Accuracy" SG_ 2651930727 Digit_03_EMCM "-";
BA_ "Accuracy" SG_ 2651930727 Digit_04_EMCM "-";
BA_ "Accuracy" SG_ 2651930727 Digit_05_EMCM "-";
BA_ "Accuracy" SG_ 2651930727 Digit_06_EMCM "-";
BA_ "Accuracy" SG_ 2651930727 Digit_07_EMCM "-";
BA_ "Accuracy" SG_ 2651930727 Digit_08_EMCM "-";
BA_ "Accuracy" SG_ 2651930727 Digit_09_EMCM "-";
BA_ "Accuracy" SG_ 2651930727 Digit_10_EMCM "-";
BA_ "Accuracy" SG_ 2651930727 Digit_11_EMCM "-";
BA_ "Accuracy" SG_ 2651930763 Digit_01_LSMD "-";
BA_ "Event trans." SG_ 2651930763 Digit_01_LSMD 0;
BA_ "GenSigSendType" SG_ 2651930763 Digit_01_LSMD 1;
BA_ "Accuracy" SG_ 2651930763 Digit_02_LSMD "-";
BA_ "Accuracy" SG_ 2651930763 Digit_03_LSMD "-";
BA_ "Accuracy" SG_ 2651930763 Digit_04_LSMD "-";
BA_ "Accuracy" SG_ 2651930763 Digit_05_LSMD "-";
BA_ "Accuracy" SG_ 2651930763 Digit_06_LSMD "-";
BA_ "Accuracy" SG_ 2651930763 Digit_07_LSMD "-";
BA_ "Accuracy" SG_ 2651930763 Digit_08_LSMD "-";
BA_ "Accuracy" SG_ 2651930763 Digit_09_LSMD "-";
BA_ "Accuracy" SG_ 2651930763 Digit_10_LSMD "-";
BA_ "Accuracy" SG_ 2651930763 Digit_11_LSMD "-";
BA_ "Accuracy" SG_ 2651930764 Digit_01_LSMP "-";
BA_ "Event trans." SG_ 2651930764 Digit_01_LSMP 0;
BA_ "GenSigSendType" SG_ 2651930764 Digit_01_LSMP 1;
BA_ "Accuracy" SG_ 2651930764 Digit_02_LSMP "-";
BA_ "Accuracy" SG_ 2651930764 Digit_03_LSMP "-";
BA_ "Accuracy" SG_ 2651930764 Digit_04_LSMP "-";
BA_ "Accuracy" SG_ 2651930764 Digit_05_LSMP "-";
BA_ "Accuracy" SG_ 2651930764 Digit_06_LSMP "-";
BA_ "Accuracy" SG_ 2651930764 Digit_07_LSMP "-";
BA_ "Accuracy" SG_ 2651930764 Digit_08_LSMP "-";
BA_ "Accuracy" SG_ 2651930764 Digit_09_LSMP "-";
BA_ "Accuracy" SG_ 2651930764 Digit_10_LSMP "-";
BA_ "Accuracy" SG_ 2651930764 Digit_11_LSMP "-";
BA_ "Accuracy" SG_ 2651930660 Digit_01_TLM "-";
BA_ "Event trans." SG_ 2651930660 Digit_01_TLM 0;
BA_ "GenSigSendType" SG_ 2651930660 Digit_01_TLM 1;
BA_ "Accuracy" SG_ 2651930660 Digit_02_TLM "-";
BA_ "Accuracy" SG_ 2651930660 Digit_03_TLM "-";
BA_ "Accuracy" SG_ 2651930660 Digit_04_TLM "-";
BA_ "Accuracy" SG_ 2651930660 Digit_05_TLM "-";
BA_ "Accuracy" SG_ 2651930660 Digit_06_TLM "-";
BA_ "Accuracy" SG_ 2651930660 Digit_07_TLM "-";
BA_ "Accuracy" SG_ 2651930660 Digit_08_TLM "-";
BA_ "Accuracy" SG_ 2651930660 Digit_09_TLM "-";
BA_ "Accuracy" SG_ 2651930660 Digit_10_TLM "-";
BA_ "Accuracy" SG_ 2651930660 Digit_11_TLM "-";
BA_ "Accuracy" SG_ 134 FPS_Status_Request "-";
BA_ "Event trans." SG_ 134 FPS_Status_Request 0;
BA_ "GenSigSendType" SG_ 134 FPS_Status_Request 2;
BA_ "Event trans." SG_ 1050 Climate_btn0 0;
BA_ "GenSigSendType" SG_ 1050 Climate_btn0 3;
BA_ "Event trans." SG_ 1050 Climate_btn1 0;
BA_ "GenSigSendType" SG_ 1050 Climate_btn1 3;
BA_ "Event trans." SG_ 1050 Climate_btn10 0;
BA_ "GenSigSendType" SG_ 1050 Climate_btn10 3;
BA_ "Event trans." SG_ 1050 Climate_btn12 0;
BA_ "GenSigSendType" SG_ 1050 Climate_btn12 3;
BA_ "Event trans." SG_ 1050 Climate_btn13 0;
BA_ "GenSigSendType" SG_ 1050 Climate_btn13 3;
BA_ "Event trans." SG_ 1050 Climate_btn2 0;
BA_ "GenSigSendType" SG_ 1050 Climate_btn2 3;
BA_ "Event trans." SG_ 1050 Climate_btn3 0;
BA_ "GenSigSendType" SG_ 1050 Climate_btn3 3;
BA_ "Event trans." SG_ 1050 Climate_btn4 0;
BA_ "GenSigSendType" SG_ 1050 Climate_btn4 3;
BA_ "Event trans." SG_ 1050 Climate_btn5 0;
BA_ "GenSigSendType" SG_ 1050 Climate_btn5 3;
BA_ "Event trans." SG_ 1050 Climate_btn6 0;
BA_ "GenSigSendType" SG_ 1050 Climate_btn6 3;
BA_ "Event trans." SG_ 1050 Climate_btn7 0;
BA_ "GenSigSendType" SG_ 1050 Climate_btn7 3;
BA_ "Event trans." SG_ 1050 Climate_btn8 0;
BA_ "GenSigSendType" SG_ 1050 Climate_btn8 3;
BA_ "Event trans." SG_ 1050 Climate_btn9 0;
BA_ "GenSigSendType" SG_ 1050 Climate_btn9 3;
BA_ "Event trans." SG_ 224 DisplayedSpeedSign 0;
BA_ "GenSigSendType" SG_ 224 DisplayedSpeedSign 3;
BA_ "Event trans." SG_ 208 ChargeNow 0;
BA_ "GenSigSendType" SG_ 208 ChargeNow 3;
BA_ "Event trans." SG_ 208 DateTmFormat2 0;
BA_ "GenSigStartValue" SG_ 208 DateTmFormat2 7;
BA_ "GenSigSendType" SG_ 208 DateTmFormat2 3;
BA_ "Event trans." SG_ 208 PairingCode 0;
BA_ "GenSigSendType" SG_ 208 PairingCode 3;
BA_ "Event trans." SG_ 208 PairingRequest 0;
BA_ "GenSigSendType" SG_ 208 PairingRequest 3;
BA_ "Event trans." SG_ 208 WeekdayTmHour_End 0;
BA_ "GenSigStartValue" SG_ 208 WeekdayTmHour_End 31;
BA_ "GenSigSendType" SG_ 208 WeekdayTmHour_End 3;
BA_ "Event trans." SG_ 208 WeekdayTmHour_Start 0;
BA_ "GenSigStartValue" SG_ 208 WeekdayTmHour_Start 31;
BA_ "GenSigSendType" SG_ 208 WeekdayTmHour_Start 3;
BA_ "Event trans." SG_ 208 WeekdayTmMinute_End 0;
BA_ "GenSigStartValue" SG_ 208 WeekdayTmMinute_End 7;
BA_ "GenSigSendType" SG_ 208 WeekdayTmMinute_End 3;
BA_ "Event trans." SG_ 208 WeekdayTmMinute_Start 0;
BA_ "GenSigStartValue" SG_ 208 WeekdayTmMinute_Start 7;
BA_ "GenSigSendType" SG_ 208 WeekdayTmMinute_Start 3;
BA_ "Event trans." SG_ 208 WeekendTmHour_End 0;
BA_ "GenSigStartValue" SG_ 208 WeekendTmHour_End 31;
BA_ "GenSigSendType" SG_ 208 WeekendTmHour_End 3;
BA_ "Event trans." SG_ 208 WeekendTmHour_Start 0;
BA_ "GenSigStartValue" SG_ 208 WeekendTmHour_Start 31;
BA_ "GenSigSendType" SG_ 208 WeekendTmHour_Start 3;
BA_ "Event trans." SG_ 208 WeekendTmMinute_End 0;
BA_ "GenSigStartValue" SG_ 208 WeekendTmMinute_End 7;
BA_ "GenSigSendType" SG_ 208 WeekendTmMinute_End 3;
BA_ "Event trans." SG_ 208 WeekendTmMinute_Start 0;
BA_ "GenSigStartValue" SG_ 208 WeekendTmMinute_Start 7;
BA_ "GenSigSendType" SG_ 208 WeekendTmMinute_Start 3;
BA_ "Event trans." SG_ 1498 CM_TCH_PT_DTV 0;
BA_ "GenSigSendType" SG_ 1498 CM_TCH_PT_DTV 3;
BA_ "Event trans." SG_ 1498 CM_TCH_PT_VES2 0;
BA_ "GenSigSendType" SG_ 1498 CM_TCH_PT_VES2 3;
BA_ "Event trans." SG_ 1498 CM_TCH_STAT 0;
BA_ "GenSigSendType" SG_ 1498 CM_TCH_STAT 3;
BA_ "Event trans." SG_ 1498 CM_TCH_X_COORD 0;
BA_ "GenSigSendType" SG_ 1498 CM_TCH_X_COORD 3;
BA_ "Event trans." SG_ 1498 CM_TCH_Y_COORD 0;
BA_ "GenSigSendType" SG_ 1498 CM_TCH_Y_COORD 3;
BA_ "Accuracy" SG_ 177 PowerLevel_External_Req "-";
BA_ "Event trans." SG_ 177 PowerLevel_External_Req 0;
BA_ "GenSigStartValue" SG_ 177 PowerLevel_External_Req 2;
BA_ "GenSigSendType" SG_ 177 PowerLevel_External_Req 1;
BA_ "Accuracy" SG_ 177 RemStNrmlStEnbl_External_Req "-";
BA_ "Event trans." SG_ 177 RemStNrmlStEnbl_External_Req 0;
BA_ "GenSigStartValue" SG_ 177 RemStNrmlStEnbl_External_Req 2;
BA_ "GenSigSendType" SG_ 177 RemStNrmlStEnbl_External_Req 1;
BA_ "Event trans." SG_ 1478 AUD_LVLSts 0;
BA_ "GenSigSendType" SG_ 1478 AUD_LVLSts 3;
BA_ "Event trans." SG_ 1478 BAL_LVLSts 0;
BA_ "GenSigStartValue" SG_ 1478 BAL_LVLSts 10;
BA_ "GenSigSendType" SG_ 1478 BAL_LVLSts 3;
BA_ "Event trans." SG_ 1478 BASS_LVLSts 0;
BA_ "GenSigStartValue" SG_ 1478 BASS_LVLSts 10;
BA_ "GenSigSendType" SG_ 1478 BASS_LVLSts 3;
BA_ "Event trans." SG_ 1478 DSS_ONSts 0;
BA_ "GenSigSendType" SG_ 1478 DSS_ONSts 3;
BA_ "Event trans." SG_ 1478 FD_LVLSts 0;
BA_ "GenSigStartValue" SG_ 1478 FD_LVLSts 10;
BA_ "GenSigSendType" SG_ 1478 FD_LVLSts 3;
BA_ "Event trans." SG_ 1478 INFO1_AUD_ACT 0;
BA_ "GenSigSendType" SG_ 1478 INFO1_AUD_ACT 3;
BA_ "Event trans." SG_ 1478 INFO1_AUD_LEVEL 0;
BA_ "GenSigSendType" SG_ 1478 INFO1_AUD_LEVEL 3;
BA_ "Event trans." SG_ 1478 INFO1_AUD_TYPE 0;
BA_ "GenSigSendType" SG_ 1478 INFO1_AUD_TYPE 3;
BA_ "Event trans." SG_ 1478 INFO2_AUD_ACT 0;
BA_ "GenSigSendType" SG_ 1478 INFO2_AUD_ACT 3;
BA_ "Event trans." SG_ 1478 INFO2_AUD_LEVEL 0;
BA_ "GenSigSendType" SG_ 1478 INFO2_AUD_LEVEL 3;
BA_ "Event trans." SG_ 1478 INFO2_AUD_TYPE 0;
BA_ "GenSigSendType" SG_ 1478 INFO2_AUD_TYPE 3;
BA_ "Event trans." SG_ 1478 MID_LVLSts 0;
BA_ "GenSigStartValue" SG_ 1478 MID_LVLSts 10;
BA_ "GenSigSendType" SG_ 1478 MID_LVLSts 3;
BA_ "Event trans." SG_ 1478 SCV_LVLSts 0;
BA_ "GenSigSendType" SG_ 1478 SCV_LVLSts 3;
BA_ "Event trans." SG_ 1478 TREB_LVLSts 0;
BA_ "GenSigStartValue" SG_ 1478 TREB_LVLSts 10;
BA_ "GenSigSendType" SG_ 1478 TREB_LVLSts 3;
BA_ "Accuracy" SG_ 2564485507 N_PDU "-";
BA_ "Accuracy" SG_ 2564485509 N_PDU "-";
BA_ "Accuracy" SG_ 2564485482 N_PDU "-";
BA_ "Accuracy" SG_ 2564485593 N_PDU "-";
BA_ "Event trans." SG_ 1445 DCSD_DISP_STAT 0;
BA_ "GenSigStartValue" SG_ 1445 DCSD_DISP_STAT 7;
BA_ "GenSigSendType" SG_ 1445 DCSD_DISP_STAT 3;
BA_ "Event trans." SG_ 1422 DrvDoorLatchDeadLockSts 0;
BA_ "GenSigSendType" SG_ 1422 DrvDoorLatchDeadLockSts 4;
BA_ "Event trans." SG_ 1422 DrvDoorLatchSts 0;
BA_ "GenSigSendType" SG_ 1422 DrvDoorLatchSts 4;
BA_ "Event trans." SG_ 1422 E1DriverDoorSts 0;
BA_ "GenSigSendType" SG_ 1422 E1DriverDoorSts 4;
BA_ "Event trans." SG_ 1422 LSMDAjarSensorFailSts 0;
BA_ "GenSigSendType" SG_ 1422 LSMDAjarSensorFailSts 3;
BA_ "Event trans." SG_ 1422 LSMDCrashLineFailSts 0;
BA_ "GenSigSendType" SG_ 1422 LSMDCrashLineFailSts 3;
BA_ "Event trans." SG_ 1422 LSMDExternalLockReleaseSwitchFa 0;
BA_ "GenSigSendType" SG_ 1422 LSMDExternalLockReleaseSwitchFa 3;
BA_ "SystemSignalLongSymbol" SG_ 1422 LSMDExternalLockReleaseSwitchFa "LSMDExternalLockReleaseSwitchFailSts";
BA_ "Event trans." SG_ 1422 LSMDFobSearchReq 0;
BA_ "GenSigSendType" SG_ 1422 LSMDFobSearchReq 3;
BA_ "Event trans." SG_ 1422 LSMDInternalFailSts 0;
BA_ "GenSigSendType" SG_ 1422 LSMDInternalFailSts 3;
BA_ "Event trans." SG_ 1422 LSMDInternalLockLightFailSts 0;
BA_ "GenSigSendType" SG_ 1422 LSMDInternalLockLightFailSts 3;
BA_ "Event trans." SG_ 1422 LSMDInternalReleaseSwitchFailSts 0;
BA_ "GenSigSendType" SG_ 1422 LSMDInternalReleaseSwitchFailSts 3;
BA_ "Event trans." SG_ 1422 LSMDInternalUnlockLightFailSts 0;
BA_ "GenSigSendType" SG_ 1422 LSMDInternalUnlockLightFailSts 3;
BA_ "Event trans." SG_ 1422 LSMDReleaseLockReq 0;
BA_ "GenSigSendType" SG_ 1422 LSMDReleaseLockReq 4;
BA_ "Event trans." SG_ 1422 LSMDTrunkDisableReq 0;
BA_ "GenSigSendType" SG_ 1422 LSMDTrunkDisableReq 4;
BA_ "Event trans." SG_ 1424 E2PsngrDoorSts 0;
BA_ "GenSigSendType" SG_ 1424 E2PsngrDoorSts 4;
BA_ "Event trans." SG_ 1424 LSMPAjarSensorFailSts 0;
BA_ "GenSigSendType" SG_ 1424 LSMPAjarSensorFailSts 3;
BA_ "Event trans." SG_ 1424 LSMPCrashLineFailSts 0;
BA_ "GenSigSendType" SG_ 1424 LSMPCrashLineFailSts 3;
BA_ "Event trans." SG_ 1424 LSMPExternalLockReleaseSwitchFa 0;
BA_ "GenSigSendType" SG_ 1424 LSMPExternalLockReleaseSwitchFa 3;
BA_ "SystemSignalLongSymbol" SG_ 1424 LSMPExternalLockReleaseSwitchFa "LSMPExternalLockReleaseSwitchFailSts";
BA_ "Event trans." SG_ 1424 LSMPFobSearchReq 0;
BA_ "GenSigSendType" SG_ 1424 LSMPFobSearchReq 3;
BA_ "Event trans." SG_ 1424 LSMPInternalFailSts 0;
BA_ "GenSigSendType" SG_ 1424 LSMPInternalFailSts 3;
BA_ "Event trans." SG_ 1424 LSMPInternalLockLightFailSts 0;
BA_ "GenSigSendType" SG_ 1424 LSMPInternalLockLightFailSts 3;
BA_ "Event trans." SG_ 1424 LSMPInternalReleaseSwitchFailSts 0;
BA_ "GenSigSendType" SG_ 1424 LSMPInternalReleaseSwitchFailSts 3;
BA_ "Event trans." SG_ 1424 LSMPInternalUnlockLightFailSts 0;
BA_ "GenSigSendType" SG_ 1424 LSMPInternalUnlockLightFailSts 3;
BA_ "Event trans." SG_ 1424 LSMPReleaseLockReq 0;
BA_ "GenSigSendType" SG_ 1424 LSMPReleaseLockReq 4;
BA_ "Event trans." SG_ 1424 LSMPTrunkDisableReq 0;
BA_ "GenSigSendType" SG_ 1424 LSMPTrunkDisableReq 4;
BA_ "Event trans." SG_ 1424 PsngrDoorLatchDeadLockSts 0;
BA_ "GenSigSendType" SG_ 1424 PsngrDoorLatchDeadLockSts 4;
BA_ "Event trans." SG_ 1424 PsngrDoorLatchSts 0;
BA_ "GenSigSendType" SG_ 1424 PsngrDoorLatchSts 4;
BA_ "Accuracy" SG_ 852 AHBFeature "-";
BA_ "Event trans." SG_ 852 AHBFeature 0;
BA_ "GenSigSendType" SG_ 852 AHBFeature 3;
BA_ "Accuracy" SG_ 852 AlertLightsON "-";
BA_ "Event trans." SG_ 852 AlertLightsON 0;
BA_ "GenSigSendType" SG_ 852 AlertLightsON 3;
BA_ "Accuracy" SG_ 852 DRLFault "-";
BA_ "Accuracy" SG_ 852 FHeatedWindowSts "-";
BA_ "Event trans." SG_ 852 FHeatedWindowSts 0;
BA_ "GenSigSendType" SG_ 852 FHeatedWindowSts 3;
BA_ "Accuracy" SG_ 852 FollowMeHomeReqSts "-";
BA_ "Event trans." SG_ 852 FollowMeHomeReqSts 0;
BA_ "GenSigSendType" SG_ 852 FollowMeHomeReqSts 3;
BA_ "Accuracy" SG_ 852 FrontFogLightSts "-";
BA_ "Event trans." SG_ 852 FrontFogLightSts 0;
BA_ "GenSigSendType" SG_ 852 FrontFogLightSts 3;
BA_ "Accuracy" SG_ 852 HeatedMirrorSts "-";
BA_ "Event trans." SG_ 852 HeatedMirrorSts 0;
BA_ "GenSigSendType" SG_ 852 HeatedMirrorSts 3;
BA_ "Accuracy" SG_ 852 HighBeamSts "-";
BA_ "Event trans." SG_ 852 HighBeamSts 0;
BA_ "GenSigSendType" SG_ 852 HighBeamSts 3;
BA_ "Accuracy" SG_ 852 L_TurnLightActivationSts "-";
BA_ "Event trans." SG_ 852 L_TurnLightActivationSts 0;
BA_ "GenSigSendType" SG_ 852 L_TurnLightActivationSts 3;
BA_ "Accuracy" SG_ 852 LHParkingLightSts "-";
BA_ "Event trans." SG_ 852 LHParkingLightSts 0;
BA_ "GenSigSendType" SG_ 852 LHParkingLightSts 3;
BA_ "Accuracy" SG_ 852 LHTurnLightFault "-";
BA_ "Accuracy" SG_ 852 LHTurnSignalSts "-";
BA_ "Event trans." SG_ 852 LHTurnSignalSts 0;
BA_ "GenSigSendType" SG_ 852 LHTurnSignalSts 3;
BA_ "Accuracy" SG_ 852 LowBeamSts "-";
BA_ "Event trans." SG_ 852 LowBeamSts 0;
BA_ "GenSigSendType" SG_ 852 LowBeamSts 3;
BA_ "Accuracy" SG_ 852 ParkingLightFault "-";
BA_ "Accuracy" SG_ 852 PlateLightFault "-";
BA_ "Accuracy" SG_ 852 R_TurnLightActivationSts "-";
BA_ "Event trans." SG_ 852 R_TurnLightActivationSts 0;
BA_ "GenSigSendType" SG_ 852 R_TurnLightActivationSts 3;
BA_ "Accuracy" SG_ 852 RearFogLightFault "-";
BA_ "Accuracy" SG_ 852 RearFogLightSts "-";
BA_ "Event trans." SG_ 852 RearFogLightSts 0;
BA_ "GenSigSendType" SG_ 852 RearFogLightSts 3;
BA_ "Accuracy" SG_ 852 ReverseGearLightFault "-";
BA_ "Accuracy" SG_ 852 RHeatedWindowSts "-";
BA_ "Event trans." SG_ 852 RHeatedWindowSts 0;
BA_ "GenSigSendType" SG_ 852 RHeatedWindowSts 3;
BA_ "Accuracy" SG_ 852 RHParkingLightSts "-";
BA_ "Event trans." SG_ 852 RHParkingLightSts 0;
BA_ "GenSigSendType" SG_ 852 RHParkingLightSts 3;
BA_ "Accuracy" SG_ 852 RHTurnLightFault "-";
BA_ "Accuracy" SG_ 852 RHTurnSignalSts "-";
BA_ "Event trans." SG_ 852 RHTurnSignalSts 0;
BA_ "GenSigSendType" SG_ 852 RHTurnSignalSts 3;
BA_ "Accuracy" SG_ 852 StopLightFault "-";
BA_ "Accuracy" SG_ 852 StopLightSts "-";
BA_ "Event trans." SG_ 852 StopLightSts 0;
BA_ "GenSigSendType" SG_ 852 StopLightSts 3;
BA_ "Event trans." SG_ 128 UpdateSts 0;
BA_ "GenSigSendType" SG_ 128 UpdateSts 2;
BA_ "Accuracy" SG_ 1896 GPS_POS3_Date_Day "1";
BA_ "GenSigStartValue" SG_ 1896 GPS_POS3_Date_Day 255;
BA_ "Accuracy" SG_ 1896 GPS_POS3_Date_Hour "1";
BA_ "GenSigStartValue" SG_ 1896 GPS_POS3_Date_Hour 255;
BA_ "Accuracy" SG_ 1896 GPS_POS3_Date_Minutes "1";
BA_ "GenSigStartValue" SG_ 1896 GPS_POS3_Date_Minutes 255;
BA_ "Accuracy" SG_ 1896 GPS_POS3_Date_Month "1";
BA_ "GenSigStartValue" SG_ 1896 GPS_POS3_Date_Month 255;
BA_ "Accuracy" SG_ 1896 GPS_POS3_Date_Seconds "0,01";
BA_ "GenSigStartValue" SG_ 1896 GPS_POS3_Date_Seconds 65535;
BA_ "Accuracy" SG_ 1896 GPS_POS3_Date_Year "1";
BA_ "GenSigStartValue" SG_ 1896 GPS_POS3_Date_Year 65535;
BA_ "Event trans." SG_ 1270 AHBFault 0;
BA_ "GenSigSendType" SG_ 1270 AHBFault 1;
BA_ "Event trans." SG_ 1270 DisplaySts 0;
BA_ "GenSigSendType" SG_ 1270 DisplaySts 1;
BA_ "Event trans." SG_ 1270 HALF_CHIME_TYPESts 0;
BA_ "GenSigSendType" SG_ 1270 HALF_CHIME_TYPESts 1;
BA_ "Event trans." SG_ 1270 HALF_LF_CHIME_RQSts 0;
BA_ "GenSigSendType" SG_ 1270 HALF_LF_CHIME_RQSts 1;
BA_ "Event trans." SG_ 1270 HALF_RF_CHIME_RQSts 0;
BA_ "GenSigSendType" SG_ 1270 HALF_RF_CHIME_RQSts 1;
BA_ "Event trans." SG_ 1270 SensorBlinded 0;
BA_ "GenSigSendType" SG_ 1270 SensorBlinded 1;
BA_ "Event trans." SG_ 1442 FastEscalation 0;
BA_ "GenSigSendType" SG_ 1442 FastEscalation 1;
BA_ "Event trans." SG_ 1442 HandsOffSts 0;
BA_ "GenSigSendType" SG_ 1442 HandsOffSts 1;
BA_ "Event trans." SG_ 1442 LC_DisplaySts 0;
BA_ "GenSigSendType" SG_ 1442 LC_DisplaySts 1;
BA_ "Event trans." SG_ 1442 LC_HandsOffSts 0;
BA_ "GenSigSendType" SG_ 1442 LC_HandsOffSts 1;
BA_ "Event trans." SG_ 1443 BatPwrUsageDisp 0;
BA_ "GenSigSendType" SG_ 1443 BatPwrUsageDisp 1;
BA_ "Event trans." SG_ 1443 BatPwrUsageDisp_V 0;
BA_ "GenSigSendType" SG_ 1443 BatPwrUsageDisp_V 1;
BA_ "Event trans." SG_ 1443 HVACPwrUsageDisp 0;
BA_ "GenSigSendType" SG_ 1443 HVACPwrUsageDisp 1;
BA_ "Event trans." SG_ 1443 HVACPwrUsageDisp_V 0;
BA_ "GenSigSendType" SG_ 1443 HVACPwrUsageDisp_V 1;
BA_ "Event trans." SG_ 1443 MtrPwrUsageDisp 0;
BA_ "GenSigSendType" SG_ 1443 MtrPwrUsageDisp 1;
BA_ "Event trans." SG_ 1443 MtrPwrUsageDisp_V 0;
BA_ "GenSigSendType" SG_ 1443 MtrPwrUsageDisp_V 1;
BA_ "Accuracy" SG_ 1864 DewpointTmp "-";
BA_ "GenSigStartValue" SG_ 1864 DewpointTmp 2044;
BA_ "Accuracy" SG_ 1864 GlassTmp "-";
BA_ "GenSigStartValue" SG_ 1864 GlassTmp 2044;
BA_ "Accuracy" SG_ 1864 HumSns_Int_flt "-";
BA_ "Accuracy" SG_ 1864 RelHumidity "-";
BA_ "GenSigStartValue" SG_ 1864 RelHumidity 252;
BA_ "Accuracy" SG_ 1864 SolarSensorLeft "-";
BA_ "GenSigStartValue" SG_ 1864 SolarSensorLeft 252;
BA_ "Accuracy" SG_ 1864 SolarSensorRight "-";
BA_ "GenSigStartValue" SG_ 1864 SolarSensorRight 252;
BA_ "Event trans." SG_ 142 ConnectedDevices 0;
BA_ "GenSigSendType" SG_ 142 ConnectedDevices 1;
BA_ "Event trans." SG_ 142 SSID 0;
BA_ "GenSigSendType" SG_ 142 SSID 1;
BA_ "Event trans." SG_ 1463 Batt_CabinPriority1 0;
BA_ "GenSigSendType" SG_ 1463 Batt_CabinPriority1 3;
BA_ "Event trans." SG_ 1463 ChargeUntilFull1 0;
BA_ "GenSigSendType" SG_ 1463 ChargeUntilFull1 3;
BA_ "Event trans." SG_ 1463 Do_Not_Repeat1 0;
BA_ "GenSigSendType" SG_ 1463 Do_Not_Repeat1 3;
BA_ "Event trans." SG_ 1463 Enable_Schedule1 0;
BA_ "GenSigSendType" SG_ 1463 Enable_Schedule1 3;
BA_ "Event trans." SG_ 1463 End_Time_Hr1 0;
BA_ "GenSigSendType" SG_ 1463 End_Time_Hr1 3;
BA_ "Event trans." SG_ 1463 End_Time_Min1 0;
BA_ "GenSigSendType" SG_ 1463 End_Time_Min1 3;
BA_ "Event trans." SG_ 1463 Schedule_Day1 0;
BA_ "GenSigSendType" SG_ 1463 Schedule_Day1 3;
BA_ "Event trans." SG_ 1463 Schedule_Type1 0;
BA_ "GenSigSendType" SG_ 1463 Schedule_Type1 3;
BA_ "Event trans." SG_ 1463 Start_Time_Hr1 0;
BA_ "GenSigSendType" SG_ 1463 Start_Time_Hr1 3;
BA_ "Event trans." SG_ 1463 Start_Time_Min1 0;
BA_ "GenSigSendType" SG_ 1463 Start_Time_Min1 3;
BA_ "Event trans." SG_ 1463 Submit_Schedule1 0;
BA_ "GenSigSendType" SG_ 1463 Submit_Schedule1 3;
BA_ "Event trans." SG_ 1447 Batt_CabinPriority2 0;
BA_ "GenSigSendType" SG_ 1447 Batt_CabinPriority2 3;
BA_ "Event trans." SG_ 1447 ChargeUntilFull2 0;
BA_ "GenSigSendType" SG_ 1447 ChargeUntilFull2 3;
BA_ "Event trans." SG_ 1447 Do_Not_Repeat2 0;
BA_ "GenSigSendType" SG_ 1447 Do_Not_Repeat2 3;
BA_ "Event trans." SG_ 1447 Enable_Schedule2 0;
BA_ "GenSigSendType" SG_ 1447 Enable_Schedule2 3;
BA_ "Event trans." SG_ 1447 End_Time_Hr2 0;
BA_ "GenSigSendType" SG_ 1447 End_Time_Hr2 3;
BA_ "Event trans." SG_ 1447 End_Time_Min2 0;
BA_ "GenSigSendType" SG_ 1447 End_Time_Min2 3;
BA_ "Event trans." SG_ 1447 Schedule_Day2 0;
BA_ "GenSigSendType" SG_ 1447 Schedule_Day2 3;
BA_ "Event trans." SG_ 1447 Schedule_Type2 0;
BA_ "GenSigSendType" SG_ 1447 Schedule_Type2 3;
BA_ "Event trans." SG_ 1447 Start_Time_Hr2 0;
BA_ "GenSigSendType" SG_ 1447 Start_Time_Hr2 3;
BA_ "Event trans." SG_ 1447 Start_Time_Min2 0;
BA_ "GenSigSendType" SG_ 1447 Start_Time_Min2 3;
BA_ "Event trans." SG_ 1447 Submit_Schedule2 0;
BA_ "GenSigSendType" SG_ 1447 Submit_Schedule2 3;
BA_ "Event trans." SG_ 1453 Batt_CabinPriority3 0;
BA_ "GenSigSendType" SG_ 1453 Batt_CabinPriority3 3;
BA_ "Event trans." SG_ 1453 ChargeUntilFull3 0;
BA_ "GenSigSendType" SG_ 1453 ChargeUntilFull3 3;
BA_ "Event trans." SG_ 1453 Do_Not_Repeat3 0;
BA_ "GenSigSendType" SG_ 1453 Do_Not_Repeat3 3;
BA_ "Event trans." SG_ 1453 Enable_Schedule3 0;
BA_ "GenSigSendType" SG_ 1453 Enable_Schedule3 3;
BA_ "Event trans." SG_ 1453 End_Time_Hr3 0;
BA_ "GenSigSendType" SG_ 1453 End_Time_Hr3 3;
BA_ "Event trans." SG_ 1453 End_Time_Min3 0;
BA_ "GenSigSendType" SG_ 1453 End_Time_Min3 3;
BA_ "Event trans." SG_ 1453 Schedule_Day3 0;
BA_ "GenSigSendType" SG_ 1453 Schedule_Day3 3;
BA_ "Event trans." SG_ 1453 Schedule_Type3 0;
BA_ "GenSigSendType" SG_ 1453 Schedule_Type3 3;
BA_ "Event trans." SG_ 1453 Start_Time_Hr3 0;
BA_ "GenSigSendType" SG_ 1453 Start_Time_Hr3 3;
BA_ "Event trans." SG_ 1453 Start_Time_Min3 0;
BA_ "GenSigSendType" SG_ 1453 Start_Time_Min3 3;
BA_ "Event trans." SG_ 1453 Submit_Schedule3 0;
BA_ "GenSigSendType" SG_ 1453 Submit_Schedule3 3;
BA_ "Accuracy" SG_ 138 FrameNumber "-";
BA_ "Event trans." SG_ 138 FrameNumber 0;
BA_ "GenSigSendType" SG_ 138 FrameNumber 1;
BA_ "Accuracy" SG_ 138 TotalFrameNumber "-";
BA_ "Accuracy" SG_ 138 UTF_Char1 "-";
BA_ "Accuracy" SG_ 138 UTF_Char2 "-";
BA_ "Accuracy" SG_ 138 UTF_Char3 "-";
BA_ "Accuracy" SG_ 138 UTF_Char4 "-";
BA_ "Accuracy" SG_ 138 UTF_Char5 "-";
BA_ "Accuracy" SG_ 138 UTF_Char6 "-";
BA_ "Accuracy" SG_ 138 UTF_Char7 "-";
BA_ "Accuracy" SG_ 986 DisplayInfoReceptionSts "-";
BA_ "Event trans." SG_ 986 DisplayInfoReceptionSts 0;
BA_ "GenSigSendType" SG_ 986 DisplayInfoReceptionSts 1;
BA_ "Accuracy" SG_ 146 Focus "-";
BA_ "Event trans." SG_ 146 Focus 0;
BA_ "GenSigSendType" SG_ 146 Focus 3;
BA_ "Accuracy" SG_ 146 List "-";
BA_ "Event trans." SG_ 146 List 0;
BA_ "GenSigSendType" SG_ 146 List 3;
BA_ "Accuracy" SG_ 146 SelectedPhoneID "-";
BA_ "Event trans." SG_ 146 SelectedPhoneID 0;
BA_ "GenSigSendType" SG_ 146 SelectedPhoneID 3;
BA_ "Accuracy" SG_ 146 SMS_PopUp "-";
BA_ "Event trans." SG_ 146 SMS_PopUp 0;
BA_ "GenSigSendType" SG_ 146 SMS_PopUp 3;
BA_ "Accuracy" SG_ 146 Status_OK "-";
BA_ "Event trans." SG_ 146 Status_OK 0;
BA_ "GenSigSendType" SG_ 146 Status_OK 3;
BA_ "Event trans." SG_ 1468 AudioRepetition 0;
BA_ "GenSigSendType" SG_ 1468 AudioRepetition 3;
BA_ "Accuracy" SG_ 1468 AutoHighBeamEnable "-";
BA_ "Event trans." SG_ 1468 AutoHighBeamEnable 0;
BA_ "GenSigStartValue" SG_ 1468 AutoHighBeamEnable 1;
BA_ "GenSigSendType" SG_ 1468 AutoHighBeamEnable 3;
BA_ "Event trans." SG_ 1468 AutoParkBrake 0;
BA_ "GenSigSendType" SG_ 1468 AutoParkBrake 3;
BA_ "Event trans." SG_ 1468 BackLightLevel 0;
BA_ "GenSigStartValue" SG_ 1468 BackLightLevel 3;
BA_ "GenSigSendType" SG_ 1468 BackLightLevel 3;
BA_ "Event trans." SG_ 1468 BSDEnable 0;
BA_ "GenSigStartValue" SG_ 1468 BSDEnable 2;
BA_ "GenSigSendType" SG_ 1468 BSDEnable 3;
BA_ "Accuracy" SG_ 1468 CorneringEnable "-";
BA_ "Event trans." SG_ 1468 CorneringEnable 0;
BA_ "GenSigSendType" SG_ 1468 CorneringEnable 3;
BA_ "Accuracy" SG_ 1468 DistanceUnit "-";
BA_ "Event trans." SG_ 1468 DistanceUnit 0;
BA_ "GenSigSendType" SG_ 1468 DistanceUnit 3;
BA_ "Accuracy" SG_ 1468 DRLEnable "-";
BA_ "Event trans." SG_ 1468 DRLEnable 0;
BA_ "GenSigSendType" SG_ 1468 DRLEnable 3;
BA_ "Accuracy" SG_ 1468 ExternalLightSensorLevel "-";
BA_ "Event trans." SG_ 1468 ExternalLightSensorLevel 0;
BA_ "GenSigStartValue" SG_ 1468 ExternalLightSensorLevel 1;
BA_ "GenSigSendType" SG_ 1468 ExternalLightSensorLevel 3;
BA_ "Accuracy" SG_ 1468 HourMode "-";
BA_ "Event trans." SG_ 1468 HourMode 0;
BA_ "GenSigSendType" SG_ 1468 HourMode 3;
BA_ "Accuracy" SG_ 1468 LanguageSelection "-";
BA_ "Event trans." SG_ 1468 LanguageSelection 0;
BA_ "GenSigSendType" SG_ 1468 LanguageSelection 3;
BA_ "Event trans." SG_ 1468 NavRepetition 0;
BA_ "GenSigSendType" SG_ 1468 NavRepetition 3;
BA_ "Event trans." SG_ 1468 PamAlertMode 0;
BA_ "GenSigStartValue" SG_ 1468 PamAlertMode 2;
BA_ "GenSigSendType" SG_ 1468 PamAlertMode 3;
BA_ "Event trans." SG_ 1468 PamChimeVolumeFront 0;
BA_ "GenSigStartValue" SG_ 1468 PamChimeVolumeFront 1;
BA_ "GenSigSendType" SG_ 1468 PamChimeVolumeFront 3;
BA_ "Event trans." SG_ 1468 PamChimeVolumeRear 0;
BA_ "GenSigStartValue" SG_ 1468 PamChimeVolumeRear 1;
BA_ "GenSigSendType" SG_ 1468 PamChimeVolumeRear 3;
BA_ "Event trans." SG_ 1468 PassiveEntry 0;
BA_ "GenSigSendType" SG_ 1468 PassiveEntry 3;
BA_ "Event trans." SG_ 1468 PhoneRepetition 0;
BA_ "GenSigSendType" SG_ 1468 PhoneRepetition 3;
BA_ "Accuracy" SG_ 1468 RainSensorLevel "-";
BA_ "Event trans." SG_ 1468 RainSensorLevel 0;
BA_ "GenSigStartValue" SG_ 1468 RainSensorLevel 1;
BA_ "GenSigSendType" SG_ 1468 RainSensorLevel 3;
BA_ "Event trans." SG_ 1468 RemoteDoorUnlock 0;
BA_ "GenSigStartValue" SG_ 1468 RemoteDoorUnlock 1;
BA_ "GenSigSendType" SG_ 1468 RemoteDoorUnlock 3;
BA_ "Event trans." SG_ 1468 Sdw 0;
BA_ "GenSigStartValue" SG_ 1468 Sdw 2;
BA_ "GenSigSendType" SG_ 1468 Sdw 3;
BA_ "Event trans." SG_ 1468 SoundHornLock 0;
BA_ "GenSigStartValue" SG_ 1468 SoundHornLock 1;
BA_ "GenSigSendType" SG_ 1468 SoundHornLock 3;
BA_ "Event trans." SG_ 1468 SoundHornRemoteStart 0;
BA_ "GenSigSendType" SG_ 1468 SoundHornRemoteStart 3;
BA_ "Accuracy" SG_ 1468 SpeedLockDoorEnable "-";
BA_ "Event trans." SG_ 1468 SpeedLockDoorEnable 0;
BA_ "GenSigSendType" SG_ 1468 SpeedLockDoorEnable 3;
BA_ "Accuracy" SG_ 1468 TelematicSetupACK "-";
BA_ "Event trans." SG_ 1468 TelematicSetupACK 0;
BA_ "GenSigSendType" SG_ 1468 TelematicSetupACK 3;
BA_ "Accuracy" SG_ 1468 TemperatureUnit "-";
BA_ "Event trans." SG_ 1468 TemperatureUnit 0;
BA_ "GenSigSendType" SG_ 1468 TemperatureUnit 3;
BA_ "Accuracy" SG_ 1486 AutoUnlockDoorExit "-";
BA_ "Event trans." SG_ 1486 AutoUnlockDoorExit 0;
BA_ "GenSigStartValue" SG_ 1486 AutoUnlockDoorExit 1;
BA_ "GenSigSendType" SG_ 1486 AutoUnlockDoorExit 3;
BA_ "Accuracy" SG_ 1486 EPB_Maintenance_Fdbk "-";
BA_ "Event trans." SG_ 1486 EPB_Maintenance_Fdbk 0;
BA_ "GenSigSendType" SG_ 1486 EPB_Maintenance_Fdbk 3;
BA_ "Accuracy" SG_ 1486 EPB_MaintenanceMode "-";
BA_ "Event trans." SG_ 1486 EPB_MaintenanceMode 0;
BA_ "GenSigSendType" SG_ 1486 EPB_MaintenanceMode 3;
BA_ "Event trans." SG_ 1486 EVConsumptionUnit 0;
BA_ "GenSigSendType" SG_ 1486 EVConsumptionUnit 3;
BA_ "Accuracy" SG_ 1486 FlashLightWLock "-";
BA_ "Event trans." SG_ 1486 FlashLightWLock 0;
BA_ "GenSigStartValue" SG_ 1486 FlashLightWLock 1;
BA_ "GenSigSendType" SG_ 1486 FlashLightWLock 3;
BA_ "Accuracy" SG_ 1486 FSFCWPlusActivationMode "-";
BA_ "Event trans." SG_ 1486 FSFCWPlusActivationMode 0;
BA_ "GenSigStartValue" SG_ 1486 FSFCWPlusActivationMode 1;
BA_ "GenSigSendType" SG_ 1486 FSFCWPlusActivationMode 3;
BA_ "Accuracy" SG_ 1486 FSFCWPlusSetting "-";
BA_ "Event trans." SG_ 1486 FSFCWPlusSetting 0;
BA_ "GenSigStartValue" SG_ 1486 FSFCWPlusSetting 3;
BA_ "GenSigSendType" SG_ 1486 FSFCWPlusSetting 3;
BA_ "Accuracy" SG_ 1486 HeadlightsOffDelay "-";
BA_ "Event trans." SG_ 1486 HeadlightsOffDelay 0;
BA_ "GenSigSendType" SG_ 1486 HeadlightsOffDelay 3;
BA_ "Accuracy" SG_ 1486 LDW_Intensity "-";
BA_ "Event trans." SG_ 1486 LDW_Intensity 0;
BA_ "GenSigStartValue" SG_ 1486 LDW_Intensity 2;
BA_ "GenSigSendType" SG_ 1486 LDW_Intensity 3;
BA_ "Accuracy" SG_ 1486 LDW_Sensibility "-";
BA_ "Event trans." SG_ 1486 LDW_Sensibility 0;
BA_ "GenSigStartValue" SG_ 1486 LDW_Sensibility 2;
BA_ "GenSigSendType" SG_ 1486 LDW_Sensibility 3;
BA_ "Event trans." SG_ 1486 PowerLevel 0;
BA_ "GenSigStartValue" SG_ 1486 PowerLevel 2;
BA_ "GenSigSendType" SG_ 1486 PowerLevel 3;
BA_ "Event trans." SG_ 1486 RecoveryIgnOff 0;
BA_ "GenSigSendType" SG_ 1486 RecoveryIgnOff 3;
BA_ "Accuracy" SG_ 1486 RemStNrmlStEnbl "-";
BA_ "Event trans." SG_ 1486 RemStNrmlStEnbl 0;
BA_ "GenSigStartValue" SG_ 1486 RemStNrmlStEnbl 2;
BA_ "GenSigSendType" SG_ 1486 RemStNrmlStEnbl 3;
BA_ "Event trans." SG_ 1486 TSREnable 0;
BA_ "GenSigSendType" SG_ 1486 TSREnable 3;
BA_ "Accuracy" SG_ 1486 TyrePressureUnit "-";
BA_ "Event trans." SG_ 1486 TyrePressureUnit 0;
BA_ "GenSigStartValue" SG_ 1486 TyrePressureUnit 2;
BA_ "GenSigSendType" SG_ 1486 TyrePressureUnit 3;
BA_ "Accuracy" SG_ 1294 AutoHold "-";
BA_ "Event trans." SG_ 1294 AutoHold 0;
BA_ "GenSigStartValue" SG_ 1294 AutoHold 1;
BA_ "GenSigSendType" SG_ 1294 AutoHold 3;
BA_ "Accuracy" SG_ 1294 Drowsy_Driver_Alert "-";
BA_ "Event trans." SG_ 1294 Drowsy_Driver_Alert 0;
BA_ "GenSigStartValue" SG_ 1294 Drowsy_Driver_Alert 1;
BA_ "GenSigSendType" SG_ 1294 Drowsy_Driver_Alert 3;
BA_ "Event trans." SG_ 1294 Speed_Unit 0;
BA_ "GenSigStartValue" SG_ 1294 Speed_Unit 1;
BA_ "GenSigSendType" SG_ 1294 Speed_Unit 3;
BA_ "Accuracy" SG_ 1485 GreetingLightsLevel "-";
BA_ "Event trans." SG_ 1485 GreetingLightsLevel 0;
BA_ "GenSigSendType" SG_ 1485 GreetingLightsLevel 3;
BA_ "Event trans." SG_ 1485 IPC_NavigationMap_Req 0;
BA_ "GenSigStartValue" SG_ 1485 IPC_NavigationMap_Req 1;
BA_ "GenSigSendType" SG_ 1485 IPC_NavigationMap_Req 3;
BA_ "Event trans." SG_ 1485 NavigationMapPopUP 0;
BA_ "GenSigStartValue" SG_ 1485 NavigationMapPopUP 1;
BA_ "GenSigSendType" SG_ 1485 NavigationMapPopUP 3;
BA_ "Event trans." SG_ 1485 New_Spd_Zone_Ind 0;
BA_ "GenSigStartValue" SG_ 1485 New_Spd_Zone_Ind 1;
BA_ "GenSigSendType" SG_ 1485 New_Spd_Zone_Ind 3;
BA_ "Event trans." SG_ 1485 SignCaptureMode 0;
BA_ "GenSigStartValue" SG_ 1485 SignCaptureMode 1;
BA_ "GenSigSendType" SG_ 1485 SignCaptureMode 3;
BA_ "Event trans." SG_ 1485 Traffic_Sign_Warn 0;
BA_ "GenSigStartValue" SG_ 1485 Traffic_Sign_Warn 1;
BA_ "GenSigSendType" SG_ 1485 Traffic_Sign_Warn 3;
BA_ "Accuracy" SG_ 1865 ADAS_Meta_CountryCode "-";
BA_ "Accuracy" SG_ 1865 ADAS_Meta_DrvSide "-";
BA_ "Accuracy" SG_ 1865 ADAS_Meta_SpdUnits "-";
BA_ "Accuracy" SG_ 2654208046 ActiveLoadSlave_AMP "-";
BA_ "Accuracy" SG_ 2654208046 CurrentFailSts_AMP "-";
BA_ "Accuracy" SG_ 2654208046 D_ES_AMP "-";
BA_ "Accuracy" SG_ 2654208046 EOL_AMP "-";
BA_ "Accuracy" SG_ 2654208046 GenericFailSts_AMP "-";
BA_ "Accuracy" SG_ 2654208046 SystemStatus_AMP "-";
BA_ "Accuracy" SG_ 2654208046 Zero_byte_AMP "-";
BA_ "Accuracy" SG_ 2654208000 ActiveLoadMaster "-";
BA_ "Accuracy" SG_ 2654208000 D_ES_BCM "-";
BA_ "Accuracy" SG_ 2654208000 EOL_BCM "-";
BA_ "Accuracy" SG_ 2654208000 GenericFailSts_BCM "-";
BA_ "Accuracy" SG_ 2654208000 Node0 "-";
BA_ "Accuracy" SG_ 2654208000 Node1 "-";
BA_ "Accuracy" SG_ 2654208000 Node10 "-";
BA_ "Accuracy" SG_ 2654208000 Node11 "-";
BA_ "Accuracy" SG_ 2654208000 Node12 "-";
BA_ "Accuracy" SG_ 2654208000 Node13 "-";
BA_ "Accuracy" SG_ 2654208000 Node14 "-";
BA_ "Accuracy" SG_ 2654208000 Node15 "-";
BA_ "Accuracy" SG_ 2654208000 Node16 "-";
BA_ "Accuracy" SG_ 2654208000 Node17 "-";
BA_ "Accuracy" SG_ 2654208000 Node18 "-";
BA_ "Accuracy" SG_ 2654208000 Node19 "-";
BA_ "Accuracy" SG_ 2654208000 Node2 "-";
BA_ "Accuracy" SG_ 2654208000 Node20 "-";
BA_ "Accuracy" SG_ 2654208000 Node21 "-";
BA_ "Accuracy" SG_ 2654208000 Node22 "-";
BA_ "Accuracy" SG_ 2654208000 Node23 "-";
BA_ "Accuracy" SG_ 2654208000 Node24 "-";
BA_ "Accuracy" SG_ 2654208000 Node25 "-";
BA_ "Accuracy" SG_ 2654208000 Node26 "-";
BA_ "Accuracy" SG_ 2654208000 Node27 "-";
BA_ "Accuracy" SG_ 2654208000 Node28 "-";
BA_ "Accuracy" SG_ 2654208000 Node29 "-";
BA_ "Accuracy" SG_ 2654208000 Node3 "-";
BA_ "Accuracy" SG_ 2654208000 Node30 "-";
BA_ "Accuracy" SG_ 2654208000 Node31 "-";
BA_ "Accuracy" SG_ 2654208000 Node4 "-";
BA_ "Accuracy" SG_ 2654208000 Node5 "-";
BA_ "Accuracy" SG_ 2654208000 Node6 "-";
BA_ "Accuracy" SG_ 2654208000 Node7 "-";
BA_ "Accuracy" SG_ 2654208000 Node8 "-";
BA_ "Accuracy" SG_ 2654208000 Node9 "-";
BA_ "Accuracy" SG_ 2654208000 P_ES "-";
BA_ "Accuracy" SG_ 2654208000 SystemCommand "-";
BA_ "Accuracy" SG_ 2654208000 Zero_byte_BCM "-";
BA_ "Accuracy" SG_ 2654208050 ActiveLoadSlave_CStack "-";
BA_ "Accuracy" SG_ 2654208050 CurrentFailSts_CStack "-";
BA_ "Accuracy" SG_ 2654208050 D_ES_CStack "-";
BA_ "Accuracy" SG_ 2654208050 EOL_CStack "-";
BA_ "Accuracy" SG_ 2654208050 GenericFailSts_CStack "-";
BA_ "Accuracy" SG_ 2654208050 SystemStatus_CStack "-";
BA_ "Accuracy" SG_ 2654208050 Zero_byte_CStack "-";
BA_ "Accuracy" SG_ 2654208010 ActiveLoadSlave_Climate "-";
BA_ "Accuracy" SG_ 2654208010 CurrentFailSts_Climate "-";
BA_ "Accuracy" SG_ 2654208010 D_ES_Climate "-";
BA_ "Accuracy" SG_ 2654208010 EOL_Climate "-";
BA_ "Accuracy" SG_ 2654208010 GenericFailSts_Climate "-";
BA_ "Accuracy" SG_ 2654208010 SystemStatus_Climate "-";
BA_ "Accuracy" SG_ 2654208010 Zero_byte_Climate "-";
BA_ "Accuracy" SG_ 2654208131 ActiveLoadSlave_DCSD "-";
BA_ "Accuracy" SG_ 2654208131 CurrentFailSts_DCSD "-";
BA_ "Accuracy" SG_ 2654208131 D_ES_DCSD "-";
BA_ "Accuracy" SG_ 2654208131 EOL_DCSD "-";
BA_ "Accuracy" SG_ 2654208131 GenericFailSts_DCSD "-";
BA_ "Accuracy" SG_ 2654208131 SystemStatus_DCSD "-";
BA_ "Accuracy" SG_ 2654208131 Zero_byte_DCSD "-";
BA_ "Accuracy" SG_ 2654208103 ActiveLoadSlave_EMCM "-";
BA_ "Accuracy" SG_ 2654208103 CurrentFailSts_EMCM "-";
BA_ "Accuracy" SG_ 2654208103 D_ES_EMCM "-";
BA_ "Accuracy" SG_ 2654208103 EOL_EMCM "-";
BA_ "Accuracy" SG_ 2654208103 GenericFailSts_EMCM "-";
BA_ "Accuracy" SG_ 2654208103 SystemStatus_EMCM "-";
BA_ "Accuracy" SG_ 2654208103 Zero_byte_EMCM "-";
BA_ "Accuracy" SG_ 2654208003 ActiveLoadSlave_IPC "-";
BA_ "Accuracy" SG_ 2654208003 CurrentFailSts_IPC "-";
BA_ "Accuracy" SG_ 2654208003 D_ES_IPC "-";
BA_ "Accuracy" SG_ 2654208003 EOL_IPC "-";
BA_ "Accuracy" SG_ 2654208003 GenericFailSts_IPC "-";
BA_ "Accuracy" SG_ 2654208003 SystemStatus_IPC "-";
BA_ "Accuracy" SG_ 2654208003 Zero_byte_IPC "-";
BA_ "Accuracy" SG_ 2654208139 ActiveLoadSlave_LSMD "-";
BA_ "Accuracy" SG_ 2654208139 CurrentFailSts_LSMD "-";
BA_ "Accuracy" SG_ 2654208139 D_ES_LSMD "-";
BA_ "Accuracy" SG_ 2654208139 EOL_LSMD "-";
BA_ "Accuracy" SG_ 2654208139 GenericFailSts_LSMD "-";
BA_ "Accuracy" SG_ 2654208139 SystemStatus_LSMD "-";
BA_ "Accuracy" SG_ 2654208139 Zero_byte_LSMD "-";
BA_ "Accuracy" SG_ 2654208140 ActiveLoadSlave_LSMP "-";
BA_ "Accuracy" SG_ 2654208140 CurrentFailSts_LSMP "-";
BA_ "Accuracy" SG_ 2654208140 D_ES_LSMP "-";
BA_ "Accuracy" SG_ 2654208140 EOL_LSMP "-";
BA_ "Accuracy" SG_ 2654208140 GenericFailSts_LSMP "-";
BA_ "Accuracy" SG_ 2654208140 SystemStatus_LSMP "-";
BA_ "Accuracy" SG_ 2654208140 Zero_byte_LSMP "-";
BA_ "Accuracy" SG_ 2654208035 ActiveLoadSlave_TBM "-";
BA_ "Accuracy" SG_ 2654208035 CurrentFailSts_TBM "-";
BA_ "Accuracy" SG_ 2654208035 D_ES_TBM "-";
BA_ "Accuracy" SG_ 2654208035 EOL_TBM "-";
BA_ "Accuracy" SG_ 2654208035 GenericFailSts_TBM "-";
BA_ "Accuracy" SG_ 2654208035 SystemStatus_TBM "-";
BA_ "Accuracy" SG_ 2654208035 Zero_byte_TBM "-";
BA_ "Accuracy" SG_ 2654208036 ActiveLoadSlave_Telematic "-";
BA_ "Accuracy" SG_ 2654208036 CurrentFailSts_Telematic "-";
BA_ "Accuracy" SG_ 2654208036 D_ES_Telematic "-";
BA_ "Accuracy" SG_ 2654208036 EOL_Telematic "-";
BA_ "Accuracy" SG_ 2654208036 GenericFailSts_Telematic "-";
BA_ "Accuracy" SG_ 2654208036 SystemStatus_Telematic "-";
BA_ "Accuracy" SG_ 2654208036 Zero_byte_Telematic "-";
BA_ "Event trans." SG_ 950 Alert_CHF 0;
BA_ "GenSigSendType" SG_ 950 Alert_CHF 1;
BA_ "Event trans." SG_ 950 Alert_CHR 0;
BA_ "GenSigSendType" SG_ 950 Alert_CHR 1;
BA_ "Event trans." SG_ 950 Alert_LHF 0;
BA_ "GenSigSendType" SG_ 950 Alert_LHF 1;
BA_ "Event trans." SG_ 950 Alert_LHR 0;
BA_ "GenSigSendType" SG_ 950 Alert_LHR 1;
BA_ "Event trans." SG_ 950 Alert_RHF 0;
BA_ "GenSigSendType" SG_ 950 Alert_RHF 1;
BA_ "Event trans." SG_ 950 Alert_RHR 0;
BA_ "GenSigSendType" SG_ 950 Alert_RHR 1;
BA_ "Event trans." SG_ 950 ChimeActivation_LHF 0;
BA_ "GenSigSendType" SG_ 950 ChimeActivation_LHF 1;
BA_ "Event trans." SG_ 950 ChimeActivation_LHR 0;
BA_ "GenSigSendType" SG_ 950 ChimeActivation_LHR 1;
BA_ "Event trans." SG_ 950 ChimeActivation_RHF 0;
BA_ "GenSigSendType" SG_ 950 ChimeActivation_RHF 1;
BA_ "Event trans." SG_ 950 ChimeActivation_RHR 0;
BA_ "GenSigSendType" SG_ 950 ChimeActivation_RHR 1;
BA_ "Event trans." SG_ 950 ChimeRepetitionRate_Front 0;
BA_ "GenSigSendType" SG_ 950 ChimeRepetitionRate_Front 1;
BA_ "Event trans." SG_ 950 ChimeRepetitionRate_Rear 0;
BA_ "GenSigSendType" SG_ 950 ChimeRepetitionRate_Rear 1;
BA_ "Event trans." SG_ 950 ChimeType_Front 0;
BA_ "GenSigSendType" SG_ 950 ChimeType_Front 1;
BA_ "Event trans." SG_ 950 ChimeType_Rear 0;
BA_ "GenSigSendType" SG_ 950 ChimeType_Rear 1;
BA_ "Event trans." SG_ 950 DisplayActivation 0;
BA_ "GenSigSendType" SG_ 950 DisplayActivation 1;
BA_ "Event trans." SG_ 950 ObstacleInTrajectory_CHF 0;
BA_ "GenSigSendType" SG_ 950 ObstacleInTrajectory_CHF 1;
BA_ "Event trans." SG_ 950 ObstacleInTrajectory_CHR 0;
BA_ "GenSigSendType" SG_ 950 ObstacleInTrajectory_CHR 1;
BA_ "Event trans." SG_ 950 ObstacleInTrajectory_LHF 0;
BA_ "GenSigSendType" SG_ 950 ObstacleInTrajectory_LHF 1;
BA_ "Event trans." SG_ 950 ObstacleInTrajectory_LHR 0;
BA_ "GenSigSendType" SG_ 950 ObstacleInTrajectory_LHR 1;
BA_ "Event trans." SG_ 950 ObstacleInTrajectory_RHF 0;
BA_ "GenSigSendType" SG_ 950 ObstacleInTrajectory_RHF 1;
BA_ "Event trans." SG_ 950 ObstacleInTrajectory_RHR 0;
BA_ "GenSigSendType" SG_ 950 ObstacleInTrajectory_RHR 1;
BA_ "Event trans." SG_ 1282 Radio_Delete_Request 0;
BA_ "GenSigSendType" SG_ 1282 Radio_Delete_Request 3;
BA_ "Event trans." SG_ 1282 Radio_Profile_Request 0;
BA_ "GenSigSendType" SG_ 1282 Radio_Profile_Request 3;
VAL_ 1985 VehicleArchitectureInfo 0 "Architecture_Not_Available" 1 "PowernetI" 2 "PowernetII" 3 "CUSW" 4 "AtlantisLow" 5 "AtlantisMidCore" 6 "AtlantisHigh" 7 "AtlantisMidAlfa";
VAL_ 1474 AbortCrankingAtc 0 "Not_Actuated" 1 "Actuated";
VAL_ 1474 BonnetAlarmCauseSts 0 "Not_Active" 1 "Active";
VAL_ 1474 DoorsAlarmCauseSts 0 "Not_Active" 1 "Active";
VAL_ 1474 ElectricalAlarmCauseSts 0 "Not_Active" 1 "Active";
VAL_ 1474 HeadlightsDelayModeActive 0 "Not_Active" 1 "Active";
VAL_ 1474 PanicModeActive 0 "Not_Active" 1 "Active";
VAL_ 1474 TrunkAlarmCauseSts 0 "Not_Active" 1 "Active";
VAL_ 1506 DoorsDeadLockReq 0 "No_Basic_Request" 1 "Central_UnDeadlock" 2 "Central_DeadLock";
VAL_ 1506 DoorsLockUnlockReq 0 "No_Basic_Request" 1 "Central_Unlock" 2 "Central_Lock" 3 "Driver_Unlock";
VAL_ 1506 DoorsSts 0 "Close" 1 "Open";
VAL_ 1506 FPSSts 0 "Not_Active" 1 "Active";
VAL_ 1506 InternalReleaseLightReq 0 "Off" 1 "Light_Lock" 2 "Light_Unlock";
VAL_ 1506 LockUnlockRequestor 0 "REQUESTOR_DEFAULT" 1 "REQUESTOR_CENTRAL_LOCK_SWITCH" 2 "REQUESTOR_LSM_SWITCH" 3 "REQUESTOR_RKE" 4 "REQUESTOR_PE" 5 "REQUESTOR_AMAS" 6 "REQUESTOR_UCONNECT" 7 "REQUESTOR_REMOTE_START" 8 "REQUESTOR_SPEED_LOCK" 9 "REQUESTOR_FPS" 10 "REQUESTOR_RELOCK" 11 "REQUESTOR_AUTO_UNLOCK_DOOR_EXIT" 12 "REQUESTOR_LOGISTIC_MODE" 13 "REQUESTOR_CONSISTENCY" 14 "REQUESTOR_FOB_SEARCH" 15 "REQUESTOR_KEY_ON_AUTH" 16 "REQUESTOR_DIAGNOSIS" 17 "REQUESTOR_MRM" 18 "REQUESTOR_INTERNAL_SWITCH " 19 "REQUESTOR_PROXIMITY";
VAL_ 1506 LockUnlockVehicleSts 0 "All_Door_Unlocked" 1 "Driver_Door_Unlocked" 2 "Locked" 3 "Passenger_Door_Unlocked" 4 "Driver_And_Passenger_Doors_Unlocked" 5 "Rear_Door_Unlocked" 6 "Front_Door_Unlocked";
VAL_ 1506 PhoneReminderIndication 0 "Not_Active" 1 "Active";
VAL_ 1506 RoofSts 0 "Roof _Open_Position" 1 "Roof _Spoiler_Position" 2 "Roof_Closed_Position" 3 "Roof _Intermediate_Position" 4 "Roof_Vent_Position" 7 "SNA";
VAL_ 1506 WirelessPadSts 0 "No_Charging" 1 "Charging" 2 "Fail_Present" 3 "Phone_Charged" 4 "Phone_Detection" 5 "Searching" 6 "Foreing_Detect" 7 "Overtemperature";
VAL_ 160 BCMFpsCommand 0 "Do_Not_Actuate" 1 "Actuate";
VAL_ 160 BCMFpsConfirm 0 "Actuate" 1 "Do_Not_Actuate";
VAL_ 160 BCMFpsFailSts 0 "Fail_not_Present" 1 "Fail_Present";
VAL_ 134 FPS_Status_Request 0 "No_FPS_Request" 1 "FPS_Actual_Status_Request";
VAL_ 1050 Climate_btn0 0 "Not_Pressed" 1 "Pressed";
VAL_ 1050 Climate_btn1 0 "Not_Pressed" 1 "Pressed";
VAL_ 1050 Climate_btn10 0 "Not_Pressed" 1 "Pressed";
VAL_ 1050 Climate_btn12 0 "Not_Pressed" 1 "Pressed";
VAL_ 1050 Climate_btn13 0 "Not_Pressed" 1 "Pressed";
VAL_ 1050 Climate_btn2 0 "Not_Pressed" 1 "Pressed";
VAL_ 1050 Climate_btn3 0 "Not_Pressed" 1 "Pressed";
VAL_ 1050 Climate_btn4 0 "Not_Pressed" 1 "Pressed";
VAL_ 1050 Climate_btn5 0 "Not_Pressed" 1 "Pressed";
VAL_ 1050 Climate_btn6 0 "Not_Pressed" 1 "Pressed";
VAL_ 1050 Climate_btn7 0 "Not_Pressed" 1 "Pressed";
VAL_ 1050 Climate_btn8 0 "Not_Pressed" 1 "Pressed";
VAL_ 1050 Climate_btn9 0 "Not_Pressed" 1 "Pressed";
VAL_ 224 DisplayedSpeedSign 0 "Sign_Not_Detected" 1 "Speed_Limit_1" 2 "Speed_Limit_2" 3 "Speed_Limit_3" 4 "Speed_Limit_4" 5 "Speed_Limit_5" 6 "Speed_Limit_6" 7 "Speed_Limit_7" 8 "Speed_Limit_8" 9 "Speed_Limit_9" 10 "Speed_Limit_10" 11 "Speed_Limit_11" 12 "Speed_Limit_12" 13 "Speed_Limit_13" 14 "Speed_Limit_14" 15 "Speed_Limit_15" 16 "Speed_Limit_16" 17 "Speed_Limit_17" 18 "Speed_Limit_18" 19 "Speed_Limit_19" 20 "Speed_Limit_20" 21 "Speed_Limit_21" 22 "Speed_Limit_22" 23 "Speed_Limit_23" 24 "Speed_Limit_24" 25 "Speed_Limit_25" 26 "Speed_Limit_26" 27 "Speed_Limit_27" 28 "Speed_Limit_28" 29 "Speed_Limit_29" 30 "Speed_Limit_30" 31 "Speed_Limit_31" 32 "Speed_Limit_32" 33 "Speed_Limit_33" 34 "Speed_Limit_34" 35 "Speed_Limit_35" 36 "Speed_Limit_36" 37 "Speed_Limit_37" 38 "Speed_Limit_38" 39 "Speed_Limit_39" 40 "Speed_Limit_40" 41 "Speed_Limit_41" 42 "Speed_Limit_42" 43 "Speed_Limit_43" 44 "Speed_Limit_44" 45 "Speed_Limit_45" 46 "Speed_Limit_46" 47 "Speed_Limit_47" 48 "Speed_Limit_48" 49 "Speed_Limit_49" 50 "Speed_Limit_50" 51 "Speed_Limit_51" 52 "Speed_Limit_52" 53 "Speed_Limit_53" 54 "Speed_Limit_54" 55 "Speed_Limit_55" 56 "Speed_Limit_56" 57 "Speed_Limit_57" 58 "Speed_Limit_58" 59 "Speed_Limit_59" 60 "Speed_Limit_60" 61 "Speed_Limit_61" 62 "Speed_Limit_62" 63 "Speed_Limit_63" 64 "Speed_Limit_64" 65 "Speed_Limit_65" 66 "Speed_Limit_66" 67 "Speed_Limit_67" 68 "Speed_Limit_68" 69 "Speed_Limit_69" 70 "Speed_Limit_70" 71 "Speed_Limit_71" 72 "Speed_Limit_72" 73 "Speed_Limit_73" 74 "Speed_Limit_74" 75 "Speed_Limit_75" 76 "Speed_Limit_76" 77 "Speed_Limit_77" 78 "Speed_Limit_78" 79 "Speed_Limit_79" 80 "Speed_Limit_80" 81 "Speed_Limit_81" 82 "Speed_Limit_82" 83 "Speed_Limit_83" 84 "Speed_Limit_84" 85 "Speed_Limit_85" 86 "Speed_Limit_86" 87 "Speed_Limit_87" 88 "Speed_Limit_88" 89 "Speed_Limit_89" 90 "Speed_Limit_90" 91 "Speed_Limit_91" 92 "Speed_Limit_92" 93 "Speed_Limit_93" 94 "Speed_Limit_94" 95 "Speed_Limit_95" 96 "Speed_Limit_96" 97 "Speed_Limit_97" 98 "Speed_Limit_98" 99 "Speed_Limit_99" 100 "Speed_Limit_100" 101 "Speed_Limit_101" 102 "Speed_Limit_102" 103 "Speed_Limit_103" 104 "Speed_Limit_104" 105 "Speed_Limit_105" 106 "Speed_Limit_106" 107 "Speed_Limit_107" 108 "Speed_Limit_108" 109 "Speed_Limit_109" 110 "Speed_Limit_110" 111 "Speed_Limit_111" 112 "Speed_Limit_112" 113 "Speed_Limit_113" 114 "Speed_Limit_114" 115 "Speed_Limit_115" 116 "Speed_Limit_116" 117 "Speed_Limit_117" 118 "Speed_Limit_118" 119 "Speed_Limit_119" 120 "Speed_Limit_120" 121 "Speed_Limit_121" 122 "Speed_Limit_122" 123 "Speed_Limit_123" 124 "Speed_Limit_124" 125 "Speed_Limit_125" 126 "Speed_Limit_126" 127 "Speed_Limit_127" 128 "Speed_Limit_128" 129 "Speed_Limit_129" 130 "Speed_Limit_130" 131 "Speed_Limit_131" 132 "Speed_Limit_132" 133 "Speed_Limit_133" 134 "Speed_Limit_134" 135 "Speed_Limit_135" 136 "Speed_Limit_136" 137 "Speed_Limit_137" 138 "Speed_Limit_138" 139 "Speed_Limit_139" 140 "Speed_Limit_140" 141 "Speed_Limit_141" 142 "Speed_Limit_142" 143 "Speed_Limit_143" 144 "Speed_Limit_144" 145 "Speed_Limit_145" 146 "Speed_Limit_146" 147 "Speed_Limit_147" 148 "Speed_Limit_148" 149 "Speed_Limit_149" 150 "Speed_Limit_150" 151 "Speed_Limit_151" 152 "Speed_Limit_152" 153 "Speed_Limit_153" 154 "Speed_Limit_154" 155 "Speed_Limit_155" 156 "Speed_Limit_156" 157 "Speed_Limit_157" 158 "Speed_Limit_158" 159 "Speed_Limit_159" 160 "Speed_Limit_160" 161 "Speed_Limit_161" 162 "Speed_Limit_162" 163 "Speed_Limit_163" 164 "Speed_Limit_164" 165 "Speed_Limit_165" 166 "Speed_Limit_166" 167 "Speed_Limit_167" 168 "Speed_Limit_168" 169 "Speed_Limit_169" 170 "Speed_Limit_170" 171 "Speed_Limit_171" 172 "Speed_Limit_172" 173 "Speed_Limit_173" 174 "Speed_Limit_174" 175 "Speed_Limit_175" 176 "Speed_Limit_176" 177 "Speed_Limit_177" 178 "Speed_Limit_178" 179 "Speed_Limit_179" 180 "Speed_Limit_180" 181 "Speed_Limit_181" 182 "Speed_Limit_182" 183 "Speed_Limit_183" 184 "Speed_Limit_184" 185 "Speed_Limit_185" 186 "Speed_Limit_186" 187 "Speed_Limit_187" 188 "Speed_Limit_188" 189 "Speed_Limit_189" 190 "Speed_Limit_190" 191 "Speed_Limit_191" 192 "Speed_Limit_192" 193 "Speed_Limit_193" 194 "Speed_Limit_194" 195 "Speed_Limit_195" 196 "Speed_Limit_196" 197 "Speed_Limit_197" 198 "Speed_Limit_198" 199 "Speed_Limit_199" 200 "Speed_Limit_200" 201 "Speed_Limit_201" 202 "Speed_Limit_202" 203 "Speed_Limit_203" 204 "Speed_Limit_204" 205 "Speed_Limit_205" 206 "Speed_Limit_206" 207 "Speed_Limit_207" 208 "Speed_Limit_208" 209 "Speed_Limit_209" 210 "Speed_Limit_210" 211 "Speed_Limit_211" 212 "Speed_Limit_212" 213 "Speed_Limit_213" 214 "Speed_Limit_214" 215 "Speed_Limit_215" 216 "Speed_Limit_216" 217 "Speed_Limit_217" 218 "Speed_Limit_218" 219 "Speed_Limit_219" 220 "Speed_Limit_220" 221 "Speed_Limit_221" 222 "Speed_Limit_222" 223 "Speed_Limit_223" 224 "Speed_Limit_224" 225 "Speed_Limit_225" 226 "Speed_Limit_226" 227 "Speed_Limit_227" 228 "Speed_Limit_228" 229 "Speed_Limit_229" 230 "Speed_Limit_230" 231 "Speed_Limit_231" 232 "Speed_Limit_232" 233 "Speed_Limit_233" 254 "Speed_Limit_Unlimited" 255 "End_Speed_Limit";
VAL_ 208 ChargeNow 0 "No_Charge" 1 "Charge_Now";
VAL_ 208 DateTmFormat2 0 "NDEF0" 1 "FORMAT_12H" 2 "FORMAT_24H" 3 "FORMAT_0" 4 "FORMAT_1" 5 "FORMAT_2" 6 "FORMAT_3" 7 "SNA";
VAL_ 208 PairingRequest 0 "Not_Request" 1 "Request";
VAL_ 208 WeekdayTmHour_End 31 "SNA";
VAL_ 208 WeekdayTmHour_Start 31 "SNA";
VAL_ 208 WeekdayTmMinute_End 0 "ZERO" 1 "FIFTEEN" 2 "THIRTY" 3 "FOURTY_FIVE" 7 "SNA";
VAL_ 208 WeekdayTmMinute_Start 0 "ZERO" 1 "FIFTEEN" 2 "THIRTY" 3 "FOURTY_FIVE" 7 "SNA";
VAL_ 208 WeekendTmHour_End 31 "SNA";
VAL_ 208 WeekendTmHour_Start 31 "SNA";
VAL_ 208 WeekendTmMinute_End 0 "ZERO" 1 "FIFTEEN" 2 "THIRTY" 3 "FOURTY_FIVE" 7 "SNA";
VAL_ 208 WeekendTmMinute_Start 0 "ZERO" 1 "FIFTEEN" 2 "THIRTY" 3 "FOURTY_FIVE" 7 "SNA";
VAL_ 1498 CM_TCH_PT_DTV 0 "Not Active" 1 "Touch screen pointer for DTV Video Active";
VAL_ 1498 CM_TCH_STAT 0 "TCH_NOT_PSD" 1 "TCH_PSD" 2 "TCH_PS_CAN" 3 "Not_Used" 4 "TCH_CFG_RES" 5 "TCH_CFG_OFFSET" 6 "TCH_CFG_MAX" 7 "SNA";
VAL_ 177 PowerLevel_External_Req 0 "Level1" 1 "Level2" 2 "Level3" 3 "Level4" 4 "Level5";
VAL_ 177 RemStNrmlStEnbl_External_Req 0 "Off" 1 "Remote_Start_Only" 2 "Remote_And_Normal_Start";
VAL_ 1478 DSS_ONSts 0 "Surround_Sound_Off" 1 "Surround_Sound_On";
VAL_ 1478 INFO1_AUD_ACT 0 "Not_Active" 1 "Active";
VAL_ 1478 INFO1_AUD_TYPE 0 "None" 1 "TA" 2 "NAV" 3 "VR_Prompt" 4 "Phone_Audio" 5 "Signal_Chime" 6 "E-Call/U-call/ACR" 15 "SNA";
VAL_ 1478 INFO2_AUD_ACT 0 "Not_Active" 1 "Active";
VAL_ 1478 INFO2_AUD_TYPE 0 "None" 1 "TA" 2 "NAV" 3 "VR_Prompt" 4 "Phone_Audio" 5 "Signal_Chime" 6 "E-Call/U-call/ACR" 15 "SNA";
VAL_ 1478 SCV_LVLSts 0 "Off" 1 "Level_1" 2 "Level_2" 3 "Level_3" 4 "Level_4" 5 "Level_5" 6 "Level_6" 7 "SNA";
VAL_ 1445 DCSD_DISP_STAT 0 "OFF" 1 "ON" 2 "BLANK" 3 "RR_CMRA" 4 "DISP_HOT" 7 "SNA";
VAL_ 1422 DrvDoorLatchDeadLockSts 0 "UnDeadlocked" 1 "Deadlocked";
VAL_ 1422 DrvDoorLatchSts 0 "Unlocked" 1 "Locked";
VAL_ 1422 E1DriverDoorSts 0 "Closed" 1 "Open";
VAL_ 1422 LSMDAjarSensorFailSts 0 "Fail_Not_Present" 1 "Fail_Present";
VAL_ 1422 LSMDCrashLineFailSts 0 "Fail_Not_Present" 1 "Fail_Present";
VAL_ 1422 LSMDExternalLockReleaseSwitchFa 0 "Fail_Not_Present" 1 "Fail_Present";
VAL_ 1422 LSMDFobSearchReq 0 "Not_Active" 1 "Lock_Req" 2 "Release_Req" 3 "WindowsUp_Req";
VAL_ 1422 LSMDInternalFailSts 0 "Fail_Not_Present" 1 "Fail_Present";
VAL_ 1422 LSMDInternalLockLightFailSts 0 "Fail_Not_Present" 1 "Fail_Present";
VAL_ 1422 LSMDInternalReleaseSwitchFailSts 0 "Fail_Not_Present" 1 "Fail_Present";
VAL_ 1422 LSMDInternalUnlockLightFailSts 0 "Fail_Not_Present" 1 "Fail_Present";
VAL_ 1422 LSMDReleaseLockReq 0 "Not_Active" 1 "Lock" 2 "Release";
VAL_ 1422 LSMDTrunkDisableReq 0 "Not_Active" 1 "Active";
VAL_ 1422 PowerModeSts_LSMD 0 "Standard_Power" 1 "Logistic_Mode_ON" 2 "Logistic_Mode_PR";
VAL_ 1424 E2PsngrDoorSts 0 "Closed" 1 "Open";
VAL_ 1424 LSMPAjarSensorFailSts 0 "Fail_Not_Present" 1 "Fail_Present";
VAL_ 1424 LSMPCrashLineFailSts 0 "Fail_Not_Present" 1 "Fail_Present";
VAL_ 1424 LSMPExternalLockReleaseSwitchFa 0 "Fail_Not_Present" 1 "Fail_Present";
VAL_ 1424 LSMPFobSearchReq 0 "Not_Active" 1 "Lock_Req" 2 "Release_Req" 3 "WindowsUp_Req";
VAL_ 1424 LSMPInternalFailSts 0 "Fail_Not_Present" 1 "Fail_Present";
VAL_ 1424 LSMPInternalLockLightFailSts 0 "Fail_Not_Present" 1 "Fail_Present";
VAL_ 1424 LSMPInternalReleaseSwitchFailSts 0 "Fail_Not_Present" 1 "Fail_Present";
VAL_ 1424 LSMPInternalUnlockLightFailSts 0 "Fail_Not_Present" 1 "Fail_Present";
VAL_ 1424 LSMPReleaseLockReq 0 "Not_Active" 1 "Lock" 2 "Release";
VAL_ 1424 LSMPTrunkDisableReq 0 "Not_Active" 1 "Active";
VAL_ 1424 PowerModeSts_LSMP 0 "Standard_Power" 1 "Logistic_Mode_ON" 2 "Logistic_Mode_PR";
VAL_ 1424 PsngrDoorLatchDeadLockSts 0 "UnDeadlocked" 1 "Deadlocked";
VAL_ 1424 PsngrDoorLatchSts 0 "Unlocked" 1 "Locked";
VAL_ 852 AHBFeature 0 "OFF" 1 "ON";
VAL_ 852 AlertLightsON 0 "OFF" 1 "ON";
VAL_ 852 DRLFault 0 "False" 1 "True";
VAL_ 852 FHeatedWindowSts 0 "OFF" 1 "ON";
VAL_ 852 FollowMeHomeReqSts 0 "Not_Active" 1 "Active";
VAL_ 852 FrontFogLightSts 0 "OFF" 1 "ON";
VAL_ 852 HeatedMirrorSts 0 "OFF" 1 "ON";
VAL_ 852 HighBeamSts 0 "OFF" 1 "ON";
VAL_ 852 L_TurnLightActivationSts 0 "Not_Active" 1 "Active";
VAL_ 852 LHParkingLightSts 0 "OFF" 1 "ON";
VAL_ 852 LHTurnLightFault 0 "False" 1 "True";
VAL_ 852 LHTurnSignalSts 0 "OFF" 1 "ON";
VAL_ 852 LowBeamSts 0 "OFF" 1 "ON";
VAL_ 852 ParkingLightFault 0 "False" 1 "True";
VAL_ 852 PlateLightFault 0 "False" 1 "True";
VAL_ 852 R_TurnLightActivationSts 0 "Not_Active" 1 "Active";
VAL_ 852 RearFogLightFault 0 "False" 1 "True";
VAL_ 852 RearFogLightSts 0 "OFF" 1 "ON";
VAL_ 852 ReverseGearLightFault 0 "False" 1 "True";
VAL_ 852 RHeatedWindowSts 0 "OFF" 1 "ON";
VAL_ 852 RHParkingLightSts 0 "OFF" 1 "ON";
VAL_ 852 RHTurnLightFault 0 "False" 1 "True";
VAL_ 852 RHTurnSignalSts 0 "OFF" 1 "ON";
VAL_ 852 StopLightFault 0 "False" 1 "True";
VAL_ 852 StopLightSts 0 "OFF" 1 "ON";
VAL_ 128 UpdateSts 0 "No_Update" 1 "Update_Avaiable" 2 "Update_Start" 3 "Update_End" 4 "Forced_Update" 5 "Update_Fail" 6 "Silent_Update" 7 "Schedule_Update";
VAL_ 1896 GPS_POS3_Date_Day 255 "SNA";
VAL_ 1896 GPS_POS3_Date_Hour 255 "SNA";
VAL_ 1896 GPS_POS3_Date_Minutes 255 "SNA";
VAL_ 1896 GPS_POS3_Date_Month 255 "SNA";
VAL_ 1896 GPS_POS3_Date_Seconds 65535 "SNA";
VAL_ 1896 GPS_POS3_Date_Year 65535 "SNA";
VAL_ 1270 AHBFault 0 "OFF" 1 "ON";
VAL_ 1270 DisplaySts 0 "LaneSense_OFF" 1 "LaneSense_ON_HF_ NotA" 2 "SingleLine_Left " 3 "SingleLine_Right" 4 "ON_HF_NotA_NHTSA_on_Left" 5 "ON_HF_NotA_NHTSA _on_Right" 6 "ON_HF_Armed" 7 "ON_HF_Left_SingleLine_Left" 8 "ON_HF_Left_side" 9 "ON_HF_Right_SingleLine_Right " 10 "ON_HF_Right_side" 11 "ON_HF_Left_ NHTSA_on_Left" 12 "ON_HF_Right_NHTSA_on_Right" 13 "ON" 14 "ON_HF_Left_RoadEdge" 15 "ON_HF_Right_RoadEdge" 16 "ON_HF_SingleLeft_NHTSA_RoadEdge" 17 "ON_HF_SingleRight_NHTSA_RoadEdge" 18 "ON_HF_SingleLeft_RoadEdge" 19 "ON_HF_SingleRight_RoadEdge" 20 "ON_HF_SingleLeft_NHTSA" 21 "ON_HF_SingleRight_NHTSA" 22 "ON_HF_Left_NHTSA_RoadEdge" 23 "ON_HF_Right_NHTSA_RoadEdge" 24 "ON_HF_Stay_In_Lane_White" 25 "ON_HF_Stay_In_Lane_Green" 26 "ON_HF_Stay_In_Lane_Yellow" 27 "ON_HF_Stay_In_Lane_Yellow_Flashing" 88 "ELK_HF_Left_NHTSA_on_Left" 89 "ELK_HF_Right_NHTSA_on_Right" 90 "ELK_HF_Left_NHTSA_RoadEdge" 91 "ELK_HF_Right_NHTSA_RoadEdge" 92 "ELK_HF_Left_RoadEdge" 93 "ELK_HF_Right_RoadEdge" 94 "ELK_HF_Left" 95 "ELK_HF_Right" 97 "ON_HF_NotA_NoHands" 98 "SingleLine_Left_marker_NoHands" 99 "SingleLine_Right_marker_NoHands" 100 "ON_HF_NotA_NHTSA_on_Left_NoHand" 101 "ON_HF_NotA_NHTSA_on_Right_NoHand" 102 "ON_HF_Armed_NoHands" 103 "ON_HF_Left_SingleLine_Left_NoHand" 104 "ON_HF_Left_NoHands" 105 "ON_HF_Right_ SingleLine_R_NoHand" 106 "ON_HF_Right_NoHands" 107 "ON_HF_Left_NHTSA_on_Left_NoHand" 108 "ON_HF_Right_NHTSA_on_R_NoHand" 109 "ON_HF_SingleLeft_NHTSA_NoHand" 110 "ON_HF_SingleRight_NHTSA_NoHand" 111 "ON_HF_Left_RoadEdgeNoHand" 112 "ON_HF_Right_RoadEdgeNoHand" 113 "ON_HF_SingleLeft_RoadEdgeNoHand" 114 "ON_HF_SingleRight_RoadEdgeNoHand" 115 "ON_HF_Left_NHTSA_RoadEdgeNoHand" 116 "ON_HF_Right_NHTSA_RoadEdgeNoHand" 117 "ON_HF_SLeft_NHTSARoadEdgeNoHand" 118 "ON_HF_SRight_NHTSARoadEdgeNoHand" 119 "ECE_ON_HF_Left_NHTSA_on_Left" 120 "ECE_ON_HF_Right_NHTSA_on_Right" 160 "Sensor_Blinded" 161 "LaneSense_Temp _Unavailable " 162 "Blinded_LaneSense_AHBC_ON" 240 "LaneSense_Fault" 255 "SNA";
VAL_ 1270 HALF_CHIME_TYPESts 0 "None" 6 "Half_Chime" 15 "SNA";
VAL_ 1270 HALF_LF_CHIME_RQSts 0 "False" 1 "True";
VAL_ 1270 HALF_RF_CHIME_RQSts 0 "False" 1 "True";
VAL_ 1270 SensorBlinded 0 "OFF" 1 "ON";
VAL_ 1442 FastEscalation 0 "False" 1 "True";
VAL_ 1442 HandsOffSts 0 "Hands_Off_Not_Detected" 1 "Hands_Off_Step1" 2 "Hands_Off_Step2" 3 "Hands_Off_Step3" 4 "Hands_Off_Step4" 5 "Hands_Off_Step5" 6 "Hands_Off_Step6" 15 "Final_State";
VAL_ 1442 LC_DisplaySts 0 "Off" 1 "Enabled" 2 "Engaged" 3 "Sensor_Blockage" 4 "LaneCentering_Fault" 5 "ECE_Left_Engaged" 6 "ECE_Right_Engaged";
VAL_ 1442 LC_HandsOffSts 0 "Hands_Off_Not_Detected" 1 "Hands_Off_Step1" 2 "Hands_Off_Step2" 3 "Hands_Off_Step3" 4 "Hands_Off_Step4" 5 "Hands_Off_Step5" 6 "Hands_Off_Step6" 15 "Final_State";
VAL_ 1443 BatPwrUsageDisp_V 0 "Valid" 1 "Not_Valid";
VAL_ 1443 HVACPwrUsageDisp_V 0 "Valid" 1 "Not_Valid";
VAL_ 1443 MtrPwrUsageDisp_V 0 "Valid" 1 "Not_Valid";
VAL_ 1864 DewpointTmp 2044 "Not_Ready" 2045 "Value_Exceeds_Limit" 2046 "Error" 2047 "SNA";
VAL_ 1864 GlassTmp 2044 "Not_Ready" 2045 "Value_Exceeds_Limit" 2046 "Error" 2047 "SNA";
VAL_ 1864 HumSns_Int_flt 0 "Fail_Not_Present" 1 "Fail_Present";
VAL_ 1864 RelHumidity 252 "Not_Ready" 253 "Value_Exceeds_Limit" 254 "Error" 255 "SNA";
VAL_ 1864 SolarSensorLeft 252 "Initial_Value" 253 "Value_Exceeds_Limit" 254 "Failure_Present" 255 "SNA";
VAL_ 1864 SolarSensorRight 252 "Initial_Value" 253 "Value_Exceeds_Limit" 254 "Failure_Present" 255 "SNA";
VAL_ 142 ConnectedDevices 0 "Not_Received" 1 "Received";
VAL_ 142 SSID 0 "Not_Received" 1 "Received";
VAL_ 1463 Batt_CabinPriority1 0 "Checkbox Unselected" 1 "Checkbox Selected";
VAL_ 1463 ChargeUntilFull1 0 "Charge Until Full Not selected" 1 "Charge Until Full";
VAL_ 1463 Do_Not_Repeat1 0 "Repeat" 1 "Do Not Repeat";
VAL_ 1463 Enable_Schedule1 0 "Disable schedule1" 1 "Enable schedule1";
VAL_ 1463 End_Time_Hr1 31 "SNA";
VAL_ 1463 End_Time_Min1 15 "SNA";
VAL_ 1463 Schedule_Day1 0 "No Selection" 1 "M" 2 "T" 3 "TM" 4 "W" 5 "WM" 6 "WT" 7 "WTM" 8 "Th" 9 "ThM" 10 "ThT" 11 "ThTM" 12 "ThW" 13 "ThWM" 14 "ThWT" 15 "ThWTM" 16 "F" 17 "FM" 18 "FT" 19 "FTM" 20 "FW" 21 "FWM" 22 "FWT" 23 "FWTM" 24 "FTh" 25 "FThM" 26 "FThT" 27 "FThTM" 28 "FThW" 29 "FThWM" 30 "FThWT" 31 "FThWTM" 32 "S" 33 "SM" 34 "ST" 35 "STM" 36 "SW" 37 "SWM" 38 "SWT" 39 "SWTM" 40 "STh" 41 "SThM" 42 "SThT" 43 "SThTM" 44 "SThW" 45 "SThWM" 46 "SThWT" 47 "SThWTM" 48 "SF" 49 "SFM" 50 "SFT" 51 "SFTM" 52 "SFW" 53 "SFWM" 54 "SFWT" 55 "SFWTM" 56 "SFTh" 57 "SFThM" 58 "SFThT" 59 "SFThTM" 60 "SFThW" 61 "SFThWM" 62 "SFThWT" 63 "SFThWTM" 64 "Sa" 65 "SaM" 66 "SaT" 67 "SaTM" 68 "SaW" 69 "SaWM" 70 "SaWT" 71 "SaWTM" 72 "SaTh" 73 "SaThM" 74 "SaThT" 75 "SaThTM" 76 "SaThW" 77 "SaThWM" 78 "SaThWT" 79 "SaThWTM" 80 "SaF" 81 "SaFM" 82 "SaFT" 83 "SaFTM" 84 "SaFW" 85 "SaFWM" 86 "SaFWT" 87 "SaFWTM" 88 "SaFTh" 89 "SaFThM" 90 "SaFThT" 91 "SaFThTM" 92 "SaFThW" 93 "SaFThWM" 94 "SaFThWT" 95 "SaFThWTM" 96 "SaS" 97 "SaSM" 98 "SaST" 99 "SaSTM" 100 "SaSW" 101 "SaSWM" 102 "SaSWT" 103 "SaSWTM" 104 "SaSTh" 105 "SaSThM" 106 "SaSThT" 107 "SaSThTM" 108 "SaSThW" 109 "SaSThWM" 110 "SaSThWT" 111 "SaSThWTM" 112 "SaSF" 113 "SaSFM" 114 "SaSFT" 115 "SaSFTM" 116 "SaSFW" 117 "SaSFWM" 118 "SaSFWT" 119 "SaSFWTM" 120 "SaSFTh" 121 "SaSFThM" 122 "SaSFThT" 123 "SaSFThTM" 124 "SaSFThW" 125 "SaSFThWM" 126 "SaSFThWT" 127 "SaSFThWTM" 255 "SNA";
VAL_ 1463 Schedule_Type1 0 "No Selection" 1 "Departure Time" 2 "Charge Interval" 3 "SNA";
VAL_ 1463 Start_Time_Hr1 31 "SNA";
VAL_ 1463 Start_Time_Min1 15 "SNA";
VAL_ 1463 Submit_Schedule1 0 "No Change" 1 "Change in schedule 1";
VAL_ 1447 Batt_CabinPriority2 0 "Checkbox Unselected" 1 "Checkbox Selected";
VAL_ 1447 ChargeUntilFull2 0 "Charge Until Full Not selected" 1 "Charge Until Full";
VAL_ 1447 Do_Not_Repeat2 0 "Repeat" 1 "Do Not Repeat";
VAL_ 1447 Enable_Schedule2 0 "Disable schedule2" 1 "Enable schedule2";
VAL_ 1447 End_Time_Hr2 31 "SNA";
VAL_ 1447 End_Time_Min2 15 "SNA";
VAL_ 1447 Schedule_Day2 0 "No Selection" 1 "M" 2 "T" 3 "TM" 4 "W" 5 "WM" 6 "WT" 7 "WTM" 8 "Th" 9 "ThM" 10 "ThT" 11 "ThTM" 12 "ThW" 13 "ThWM" 14 "ThWT" 15 "ThWTM" 16 "F" 17 "FM" 18 "FT" 19 "FTM" 20 "FW" 21 "FWM" 22 "FWT" 23 "FWTM" 24 "FTh" 25 "FThM" 26 "FThT" 27 "FThTM" 28 "FThW" 29 "FThWM" 30 "FThWT" 31 "FThWTM" 32 "S" 33 "SM" 34 "ST" 35 "STM" 36 "SW" 37 "SWM" 38 "SWT" 39 "SWTM" 40 "STh" 41 "SThM" 42 "SThT" 43 "SThTM" 44 "SThW" 45 "SThWM" 46 "SThWT" 47 "SThWTM" 48 "SF" 49 "SFM" 50 "SFT" 51 "SFTM" 52 "SFW" 53 "SFWM" 54 "SFWT" 55 "SFWTM" 56 "SFTh" 57 "SFThM" 58 "SFThT" 59 "SFThTM" 60 "SFThW" 61 "SFThWM" 62 "SFThWT" 63 "SFThWTM" 64 "Sa" 65 "SaM" 66 "SaT" 67 "SaTM" 68 "SaW" 69 "SaWM" 70 "SaWT" 71 "SaWTM" 72 "SaTh" 73 "SaThM" 74 "SaThT" 75 "SaThTM" 76 "SaThW" 77 "SaThWM" 78 "SaThWT" 79 "SaThWTM" 80 "SaF" 81 "SaFM" 82 "SaFT" 83 "SaFTM" 84 "SaFW" 85 "SaFWM" 86 "SaFWT" 87 "SaFWTM" 88 "SaFTh" 89 "SaFThM" 90 "SaFThT" 91 "SaFThTM" 92 "SaFThW" 93 "SaFThWM" 94 "SaFThWT" 95 "SaFThWTM" 96 "SaS" 97 "SaSM" 98 "SaST" 99 "SaSTM" 100 "SaSW" 101 "SaSWM" 102 "SaSWT" 103 "SaSWTM" 104 "SaSTh" 105 "SaSThM" 106 "SaSThT" 107 "SaSThTM" 108 "SaSThW" 109 "SaSThWM" 110 "SaSThWT" 111 "SaSThWTM" 112 "SaSF" 113 "SaSFM" 114 "SaSFT" 115 "SaSFTM" 116 "SaSFW" 117 "SaSFWM" 118 "SaSFWT" 119 "SaSFWTM" 120 "SaSFTh" 121 "SaSFThM" 122 "SaSFThT" 123 "SaSFThTM" 124 "SaSFThW" 125 "SaSFThWM" 126 "SaSFThWT" 127 "SaSFThWTM" 255 "SNA";
VAL_ 1447 Schedule_Type2 0 "No Selection" 1 "Departure Time" 2 "Charge Interval" 3 "SNA";
VAL_ 1447 Start_Time_Hr2 31 "SNA";
VAL_ 1447 Start_Time_Min2 15 "SNA";
VAL_ 1447 Submit_Schedule2 0 "No Change" 1 "Change in schedule 2";
VAL_ 1453 Batt_CabinPriority3 0 "Checkbox Unselected" 1 "Checkbox Selected";
VAL_ 1453 ChargeUntilFull3 0 "Charge Until Full Not selected" 1 "Charge Until Full";
VAL_ 1453 Do_Not_Repeat3 0 "Repeat" 1 "Do Not Repeat";
VAL_ 1453 Enable_Schedule3 0 "Disable schedule3" 1 "Enable schedule3";
VAL_ 1453 End_Time_Hr3 31 "SNA";
VAL_ 1453 End_Time_Min3 15 "SNA";
VAL_ 1453 Schedule_Day3 0 "No Selection" 1 "M" 2 "T" 3 "TM" 4 "W" 5 "WM" 6 "WT" 7 "WTM" 8 "Th" 9 "ThM" 10 "ThT" 11 "ThTM" 12 "ThW" 13 "ThWM" 14 "ThWT" 15 "ThWTM" 16 "F" 17 "FM" 18 "FT" 19 "FTM" 20 "FW" 21 "FWM" 22 "FWT" 23 "FWTM" 24 "FTh" 25 "FThM" 26 "FThT" 27 "FThTM" 28 "FThW" 29 "FThWM" 30 "FThWT" 31 "FThWTM" 32 "S" 33 "SM" 34 "ST" 35 "STM" 36 "SW" 37 "SWM" 38 "SWT" 39 "SWTM" 40 "STh" 41 "SThM" 42 "SThT" 43 "SThTM" 44 "SThW" 45 "SThWM" 46 "SThWT" 47 "SThWTM" 48 "SF" 49 "SFM" 50 "SFT" 51 "SFTM" 52 "SFW" 53 "SFWM" 54 "SFWT" 55 "SFWTM" 56 "SFTh" 57 "SFThM" 58 "SFThT" 59 "SFThTM" 60 "SFThW" 61 "SFThWM" 62 "SFThWT" 63 "SFThWTM" 64 "Sa" 65 "SaM" 66 "SaT" 67 "SaTM" 68 "SaW" 69 "SaWM" 70 "SaWT" 71 "SaWTM" 72 "SaTh" 73 "SaThM" 74 "SaThT" 75 "SaThTM" 76 "SaThW" 77 "SaThWM" 78 "SaThWT" 79 "SaThWTM" 80 "SaF" 81 "SaFM" 82 "SaFT" 83 "SaFTM" 84 "SaFW" 85 "SaFWM" 86 "SaFWT" 87 "SaFWTM" 88 "SaFTh" 89 "SaFThM" 90 "SaFThT" 91 "SaFThTM" 92 "SaFThW" 93 "SaFThWM" 94 "SaFThWT" 95 "SaFThWTM" 96 "SaS" 97 "SaSM" 98 "SaST" 99 "SaSTM" 100 "SaSW" 101 "SaSWM" 102 "SaSWT" 103 "SaSWTM" 104 "SaSTh" 105 "SaSThM" 106 "SaSThT" 107 "SaSThTM" 108 "SaSThW" 109 "SaSThWM" 110 "SaSThWT" 111 "SaSThWTM" 112 "SaSF" 113 "SaSFM" 114 "SaSFT" 115 "SaSFTM" 116 "SaSFW" 117 "SaSFWM" 118 "SaSFWT" 119 "SaSFWTM" 120 "SaSFTh" 121 "SaSFThM" 122 "SaSFThT" 123 "SaSFThTM" 124 "SaSFThW" 125 "SaSFThWM" 126 "SaSFThWT" 127 "SaSFThWTM" 255 "SNA";
VAL_ 1453 Schedule_Type3 0 "No Selection" 1 "Departure Time" 2 "Charge Interval" 3 "SNA";
VAL_ 1453 Start_Time_Hr3 31 "SNA";
VAL_ 1453 Start_Time_Min3 15 "SNA";
VAL_ 1453 Submit_Schedule3 0 "No Change" 1 "Change in schedule 3";
VAL_ 138 FrameNumber 0 "Frame1" 1 "Frame2" 2 "Frame3" 3 "Frame4" 4 "Frame5" 5 "Frame6" 6 "Frame7" 7 "Frame8" 8 "Frame9" 9 "Frame10" 10 "Frame11" 11 "Frame12" 12 "Frame13" 13 "Frame14" 14 "Frame15" 15 "Frame16";
VAL_ 138 TotalFrameNumber 0 "Frame1" 1 "Frame2" 2 "Frame3" 3 "Frame4" 4 "Frame5" 5 "Frame6" 6 "Frame7" 7 "Frame8" 8 "Frame9" 9 "Frame10" 10 "Frame11" 11 "Frame12" 12 "Frame13" 13 "Frame14" 14 "Frame15" 15 "Frame16";
VAL_ 986 DisplayInfoReceptionSts 0 "Received" 1 "Not_Received";
VAL_ 146 Focus 0 "Row1" 1 "Row2" 2 "Row3" 3 "Row4" 4 "Row5" 5 "Row6" 6 "Row7" 7 "Row8" 8 "Row9" 9 "Row10";
VAL_ 146 SelectedPhoneID 7 "SNA";
VAL_ 146 SMS_PopUp 0 "Off" 1 "On";
VAL_ 146 Status_OK 0 "NotActive" 1 "Active";
VAL_ 1468 AudioRepetition 0 "On" 1 "Off";
VAL_ 1468 AutoHighBeamEnable 0 "Not_Enable" 1 "Enable";
VAL_ 1468 AutoParkBrake 0 "On" 1 "Off";
VAL_ 1468 BackLightLevel 0 "Level_1" 1 "Level_2" 2 "Level_3" 3 "Level_4" 4 "Level_5" 5 "Level_6" 6 "Level_7" 7 "Level_8";
VAL_ 1468 BSDEnable 0 "Not_Enable" 1 "Enable_LED" 2 "Enable_ LED_Chime";
VAL_ 1468 CorneringEnable 0 "True" 1 "False";
VAL_ 1468 DistanceUnit 0 "km" 1 "miles";
VAL_ 1468 DRLEnable 0 "True" 1 "False";
VAL_ 1468 ExternalLightSensorLevel 0 "Level_3" 1 "Level_2" 2 "Level_1" 3 "Level_0";
VAL_ 1468 HourMode 0 "0_24_h" 1 "0_12_h";
VAL_ 1468 LanguageSelection 0 "Italian" 1 "Deutsch" 2 "English" 3 "Espanol" 4 "Francais" 5 "Portugues" 6 "Polish" 7 "Dutch" 8 "Brazilian" 9 "Turkish" 10 "Mexican" 11 "English_US" 12 "Canadian" 13 "Russian" 14 "Chinese" 15 "Japanese" 16 "Korean" 17 "Arabic" 18 "Czech" 19 "Slovakian" 20 "Hungarian" 21 "Hindi";
VAL_ 1468 NavRepetition 0 "Absent" 1 "Present";
VAL_ 1468 PamAlertMode 0 "Off" 1 "Sound" 2 "Sound_Display";
VAL_ 1468 PamChimeVolumeFront 0 "Low" 1 "Medium" 2 "High";
VAL_ 1468 PamChimeVolumeRear 0 "Low" 1 "Medium" 2 "High";
VAL_ 1468 PassiveEntry 0 "On" 1 "Off";
VAL_ 1468 PhoneRepetition 0 "Absent" 1 "Present";
VAL_ 1468 RainSensorLevel 0 "Not_Enable" 1 "Enable";
VAL_ 1468 RemoteDoorUnlock 0 "Driver" 1 "All";
VAL_ 1468 Sdw 0 "Off" 1 "Sound" 2 "Sound_Display";
VAL_ 1468 SoundHornLock 0 "Off" 1 "1st Press" 2 "2nd Press";
VAL_ 1468 SoundHornRemoteStart 0 "On" 1 "Off";
VAL_ 1468 SpeedLockDoorEnable 0 "Not_Enable" 1 "Enable";
VAL_ 1468 TelematicSetupACK 0 "No_ACK_Required" 1 "ACK_KO" 3 "ACK_OK";
VAL_ 1468 TemperatureUnit 0 "°C" 1 "°F";
VAL_ 1486 AutoUnlockDoorExit 0 "Not_Enable" 1 "Enable";
VAL_ 1486 EPB_Maintenance_Fdbk 0 "Initialization" 31 "SNA";
VAL_ 1486 EPB_MaintenanceMode 0 "Off" 1 "On";
VAL_ 1486 EVConsumptionUnit 0 "Km_Per_KWh" 1 "KWh_Per_100Km" 2 "Miles_Per_KWh" 3 "KWh_Per_Miles" 4 "MPGe";
VAL_ 1486 FlashLightWLock 0 "Off" 1 "On";
VAL_ 1486 FSFCWPlusActivationMode 0 "Near" 1 "Med" 2 "Far";
VAL_ 1486 FSFCWPlusSetting 0 "Off" 1 "Audio" 2 "Brake" 3 "Audio_Brake" 4 "Not_Request";
VAL_ 1486 HeadlightsOffDelay 0 "0sec" 1 "30sec" 2 "60sec" 3 "90ec";
VAL_ 1486 LDW_Intensity 0 "Low" 1 "Med" 2 "High";
VAL_ 1486 LDW_Sensibility 0 "Early" 1 "Med" 2 "Late";
VAL_ 1486 PowerLevel 0 "Level1" 1 "Level2" 2 "Level3" 3 "Level4" 4 "Level5";
VAL_ 1486 RecoveryIgnOff 0 "Not_Active" 1 "Active_KeyOff_Recovery";
VAL_ 1486 RemStNrmlStEnbl 0 "Off" 1 "Remote_Start_Only" 2 "Remote_And_Normal_Start";
VAL_ 1486 TSREnable 0 "Not_Active" 1 "Active";
VAL_ 1486 TyrePressureUnit 0 "KPa" 1 "psi" 2 "bar";
VAL_ 1294 AutoHold 0 "Off" 1 "On";
VAL_ 1294 Drowsy_Driver_Alert 0 "Off" 1 "On";
VAL_ 1294 Speed_Unit 0 "mph" 1 "kph";
VAL_ 1485 GreetingLightsLevel 0 "0sec" 1 "30sec" 2 "60sec" 3 "90sec";
VAL_ 1485 IPC_NavigationMap_Req 0 "Send_Nav_Map" 1 "Not_Active" 2 "Disable_Projection";
VAL_ 1485 NavigationMapPopUP 0 "Active" 1 "Not_Active";
VAL_ 1485 New_Spd_Zone_Ind 0 "Off" 1 "Visual" 2 "Chime" 3 "Visual_Chime";
VAL_ 1485 SignCaptureMode 0 "Confirmation" 1 "Automatic";
VAL_ 1485 Traffic_Sign_Warn 0 "Off" 1 "Visual" 2 "Visual_Chime";
VAL_ 1865 ADAS_Meta_DrvSide 0 "Left" 1 "Right";
VAL_ 1865 ADAS_Meta_MapProvider 0 "Unknown" 1 "NAVTEQ" 2 "TomTom" 3 "Zenrin" 4 "IPC" 5 "NavInfo" 6 "Others" 7 "SNA";
VAL_ 1865 ADAS_Meta_SpdUnits 0 "kmh" 1 "mph";
VAL_ 2654208046 ActiveLoadSlave_AMP 0 "No_Active_Loads_in_Slave" 1 "Active_Loads_in_Slave";
VAL_ 2654208046 CurrentFailSts_AMP 0 "No_Fail_Present" 1 "Fail_Present";
VAL_ 2654208046 D_ES_AMP 0 "Error_Active_State" 1 "Error_Passive_Warning_State" 2 "Bus_Off_State" 3 "Not_Used";
VAL_ 2654208046 EOL_AMP 0 "No_EOL_Programming" 1 "EOL_Programming";
VAL_ 2654208046 GenericFailSts_AMP 0 "No_Fail_Present" 1 "Fail_Present";
VAL_ 2654208046 SystemStatus_AMP 0 "Wake_up" 1 "Not_Used" 2 "StayActive" 3 "Not_Used";
VAL_ 2654208046 Zero_byte_AMP 0 "Fixed";
VAL_ 2654208000 ActiveLoadMaster 0 "No_Active_loads_in_master" 1 "Active_loads_in_master";
VAL_ 2654208000 D_ES_BCM 0 "Error_Active_State" 1 "Error_Passive_Warning_State" 2 "Bus_Off_State" 3 "Not_Used";
VAL_ 2654208000 EOL_BCM 0 "No_EOL_Programming" 1 "EOL_Programming";
VAL_ 2654208000 GenericFailSts_BCM 0 "No_FunctionalFailPresent" 1 "FunctionalFailPresent";
VAL_ 2654208000 Node0 0 "Not_active" 1 "Active";
VAL_ 2654208000 Node1 0 "Not_active" 1 "Active";
VAL_ 2654208000 Node10 0 "Not_active" 1 "Active";
VAL_ 2654208000 Node11 0 "Not_active" 1 "Active";
VAL_ 2654208000 Node12 0 "Not_active" 1 "Active";
VAL_ 2654208000 Node13 0 "Not_active" 1 "Active";
VAL_ 2654208000 Node14 0 "Not_active" 1 "Active";
VAL_ 2654208000 Node15 0 "Not_active" 1 "Active";
VAL_ 2654208000 Node16 0 "Not_active" 1 "Active";
VAL_ 2654208000 Node17 0 "Not_active" 1 "Active";
VAL_ 2654208000 Node18 0 "Not_active" 1 "Active";
VAL_ 2654208000 Node19 0 "Not_active" 1 "Active";
VAL_ 2654208000 Node2 0 "Not_active" 1 "Active";
VAL_ 2654208000 Node20 0 "Not_active" 1 "Active";
VAL_ 2654208000 Node21 0 "Not_active" 1 "Active";
VAL_ 2654208000 Node22 0 "Not_active" 1 "Active";
VAL_ 2654208000 Node23 0 "Not_active" 1 "Active";
VAL_ 2654208000 Node24 0 "Not_active" 1 "Active";
VAL_ 2654208000 Node25 0 "Not_active" 1 "Active";
VAL_ 2654208000 Node26 0 "Not_active" 1 "Active";
VAL_ 2654208000 Node27 0 "Not_active" 1 "Active";
VAL_ 2654208000 Node28 0 "Not_active" 1 "Active";
VAL_ 2654208000 Node29 0 "Not_active" 1 "Active";
VAL_ 2654208000 Node3 0 "Not_active" 1 "Active";
VAL_ 2654208000 Node30 0 "Not_active" 1 "Active";
VAL_ 2654208000 Node31 0 "Not_active" 1 "Active";
VAL_ 2654208000 Node4 0 "Not_active" 1 "Active";
VAL_ 2654208000 Node5 0 "Not_active" 1 "Active";
VAL_ 2654208000 Node6 0 "Not_active" 1 "Active";
VAL_ 2654208000 Node7 0 "Not_active" 1 "Active";
VAL_ 2654208000 Node8 0 "Not_active" 1 "Active";
VAL_ 2654208000 Node9 0 "Not_active" 1 "Active";
VAL_ 2654208000 P_ES 0 "Fail_Not_Present" 1 "Fail_Present";
VAL_ 2654208000 SystemCommand 0 "Wake_up" 1 "Not_Used" 2 "StayActive" 3 "Sleep";
VAL_ 2654208000 Zero_byte_BCM 0 "Fixed";
VAL_ 2654208050 ActiveLoadSlave_CStack 0 "No_Active_Loads_in_Slave" 1 "Active_Loads_in_Slave";
VAL_ 2654208050 CurrentFailSts_CStack 0 "No_Fail_Present" 1 "Fail_Present";
VAL_ 2654208050 D_ES_CStack 0 "Error_Active_State" 1 "Error_Passive_Warning_State" 2 "Bus_Off_State" 3 "Not_Used";
VAL_ 2654208050 EOL_CStack 0 "No_EOL_Programming" 1 "EOL_Programming";
VAL_ 2654208050 GenericFailSts_CStack 0 "No_Fail_Present" 1 "Fail_Present";
VAL_ 2654208050 SystemStatus_CStack 0 "Wake_up" 1 "Not_Used" 2 "StayActive" 3 "Not_Used";
VAL_ 2654208050 Zero_byte_CStack 0 "Fixed";
VAL_ 2654208010 ActiveLoadSlave_Climate 0 "No_Active_Loads_in_Slave" 1 "Active_Loads_in_Slave";
VAL_ 2654208010 CurrentFailSts_Climate 0 "No_Fail_Present" 1 "Fail_Present";
VAL_ 2654208010 D_ES_Climate 0 "Error_Active_State" 1 "Error_Passive_Warning_State" 2 "Bus_Off_State" 3 "Not_Used";
VAL_ 2654208010 EOL_Climate 0 "No_EOL_Programming" 1 "EOL_Programming";
VAL_ 2654208010 GenericFailSts_Climate 0 "No_Fail_Present" 1 "Fail_Present";
VAL_ 2654208010 SystemStatus_Climate 0 "Wake_up" 1 "Not_Used" 2 "StayActive" 3 "Not_Used";
VAL_ 2654208010 Zero_byte_Climate 0 "Fixed";
VAL_ 2654208131 ActiveLoadSlave_DCSD 0 "No_Active_Loads_in_Slave" 1 "Active_Loads_in_Slave";
VAL_ 2654208131 CurrentFailSts_DCSD 0 "No_Fail_Present" 1 "Fail_Present";
VAL_ 2654208131 D_ES_DCSD 0 "Error_Active_State" 1 "Error_Passive_Warning_State" 2 "Bus_Off_State" 3 "Not_Used";
VAL_ 2654208131 EOL_DCSD 0 "No_EOL_Programming" 1 "EOL_Programming";
VAL_ 2654208131 GenericFailSts_DCSD 0 "No_Fail_Present" 1 "Fail_Present";
VAL_ 2654208131 SystemStatus_DCSD 0 "Wake_up" 1 "Not_Used" 2 "StayActive" 3 "Not_Used";
VAL_ 2654208131 Zero_byte_DCSD 0 "Fixed";
VAL_ 2654208103 ActiveLoadSlave_EMCM 0 "No_Active_Loads_in_Slave" 1 "Active_Loads_in_Slave";
VAL_ 2654208103 CurrentFailSts_EMCM 0 "No_Fail_Present" 1 "Fail_Present";
VAL_ 2654208103 D_ES_EMCM 0 "Error_Active_State" 1 "Error_Passive_Warning_State" 2 "Bus_Off_State" 3 "Not_Used";
VAL_ 2654208103 EOL_EMCM 0 "No_EOL_Programming" 1 "EOL_Programming";
VAL_ 2654208103 GenericFailSts_EMCM 0 "No_Fail_Present" 1 "Fail_Present";
VAL_ 2654208103 SystemStatus_EMCM 0 "Wake_up" 1 "Not_Used" 2 "StayActive" 3 "Not_Used";
VAL_ 2654208103 Zero_byte_EMCM 0 "Fixed";
VAL_ 2654208003 ActiveLoadSlave_IPC 0 "No_Active_Loads_in_Slave" 1 "Active_Loads_in_Slave";
VAL_ 2654208003 CurrentFailSts_IPC 0 "No_Fail_Present" 1 "Fail_Present";
VAL_ 2654208003 D_ES_IPC 0 "Error_Active_State" 1 "Error_Passive_Warning_State" 2 "Bus_Off_State" 3 "Not_Used";
VAL_ 2654208003 EOL_IPC 0 "No_EOL_Programming" 1 "EOL_Programming";
VAL_ 2654208003 GenericFailSts_IPC 0 "No_Fail_Present" 1 "Fail_Present";
VAL_ 2654208003 SystemStatus_IPC 0 "Wake_up" 1 "Not_Used" 2 "StayActive" 3 "Not_Used";
VAL_ 2654208003 Zero_byte_IPC 0 "Fixed";
VAL_ 2654208139 ActiveLoadSlave_LSMD 0 "No_Active_Loads_in_Slave" 1 "Active_Loads_in_Slave";
VAL_ 2654208139 CurrentFailSts_LSMD 0 "No_Fail_Present" 1 "Fail_Present";
VAL_ 2654208139 D_ES_LSMD 0 "Error_Active_State" 1 "Error_Passive_Warning_State" 2 "Bus_Off_State" 3 "Not_Used";
VAL_ 2654208139 EOL_LSMD 0 "No_EOL_Programming" 1 "EOL_Programming";
VAL_ 2654208139 GenericFailSts_LSMD 0 "No_Fail_Present" 1 "Fail_Present";
VAL_ 2654208139 SystemStatus_LSMD 0 "Wake_up" 1 "Not_Used" 2 "StayActive" 3 "Not_Used";
VAL_ 2654208139 Zero_byte_LSMD 0 "Fixed";
VAL_ 2654208140 ActiveLoadSlave_LSMP 0 "No_Active_Loads_in_Slave" 1 "Active_Loads_in_Slave";
VAL_ 2654208140 CurrentFailSts_LSMP 0 "No_Fail_Present" 1 "Fail_Present";
VAL_ 2654208140 D_ES_LSMP 0 "Error_Active_State" 1 "Error_Passive_Warning_State" 2 "Bus_Off_State" 3 "Not_Used";
VAL_ 2654208140 EOL_LSMP 0 "No_EOL_Programming" 1 "EOL_Programming";
VAL_ 2654208140 GenericFailSts_LSMP 0 "No_Fail_Present" 1 "Fail_Present";
VAL_ 2654208140 SystemStatus_LSMP 0 "Wake_up" 1 "Not_Used" 2 "StayActive" 3 "Not_Used";
VAL_ 2654208140 Zero_byte_LSMP 0 "Fixed";
VAL_ 2654208035 ActiveLoadSlave_TBM 0 "No_Active_Loads_in_Slave" 1 "Active_Loads_in_Slave";
VAL_ 2654208035 CurrentFailSts_TBM 0 "No_Fail_Present" 1 "Fail_Present";
VAL_ 2654208035 D_ES_TBM 0 "Error_Active_State" 1 "Error_Passive_Warning_State" 2 "Bus_Off_State" 3 "Not_Used";
VAL_ 2654208035 EOL_TBM 0 "No_EOL_Programming" 1 "EOL_Programming";
VAL_ 2654208035 GenericFailSts_TBM 0 "No_Fail_Present" 1 "Fail_Present";
VAL_ 2654208035 SystemStatus_TBM 0 "Wake_up" 1 "Not_Used" 2 "StayActive" 3 "Not_Used";
VAL_ 2654208035 Zero_byte_TBM 0 "Fixed";
VAL_ 2654208036 ActiveLoadSlave_Telematic 0 "No_Active_Loads_in_Slave" 1 "Active_Loads_in_Slave";
VAL_ 2654208036 CurrentFailSts_Telematic 0 "No_Fail_Present" 1 "Fail_Present";
VAL_ 2654208036 D_ES_Telematic 0 "Error_Active_State" 1 "Error_Passive_Warning_State" 2 "Bus_Off_State" 3 "Not_Used";
VAL_ 2654208036 EOL_Telematic 0 "No_EOL_Programming" 1 "EOL_Programming";
VAL_ 2654208036 GenericFailSts_Telematic 0 "No_Fail_Present" 1 "Fail_Present";
VAL_ 2654208036 SystemStatus_Telematic 0 "Wake_up" 1 "Not_Used" 2 "StayActive" 3 "Not_Used";
VAL_ 2654208036 Zero_byte_Telematic 0 "Fixed";
VAL_ 950 Alert_CHF 0 "No_object_detected" 1 "1_Arc" 2 "2_Arc" 3 "3_Arc" 4 "4_Arc" 5 "5_Arc" 6 "6_Arc" 7 "SNA";
VAL_ 950 Alert_CHR 0 "No_object_detected" 1 "1_Arc" 2 "2_Arc" 3 "3_Arc" 4 "4_Arc" 5 "5_Arc" 6 "6_Arc" 7 "SNA";
VAL_ 950 Alert_LHF 0 "No_object_detected" 1 "1_Arc" 2 "2_Arc" 7 "SNA";
VAL_ 950 Alert_LHR 0 "No_object_detected" 1 "1_Arc" 2 "2_Arc" 7 "SNA";
VAL_ 950 Alert_RHF 0 "No_object_detected" 1 "1_Arc" 2 "2_Arc" 7 "SNA";
VAL_ 950 Alert_RHR 0 "No_object_detected" 1 "1_Arc" 2 "2_Arc" 7 "SNA";
VAL_ 950 ChimeActivation_LHF 0 "NotActive" 1 "Active";
VAL_ 950 ChimeActivation_LHR 0 "NotActive" 1 "Active";
VAL_ 950 ChimeActivation_RHF 0 "NotActive" 1 "Active";
VAL_ 950 ChimeActivation_RHR 0 "NotActive" 1 "Active";
VAL_ 950 ChimeType_Front 0 "Type4" 1 "Type5";
VAL_ 950 ChimeType_Rear 0 "Type4" 1 "Type5";
VAL_ 950 DisplayActivation 0 "NotActive" 1 "Active";
VAL_ 950 ObstacleInTrajectory_CHF 0 "True" 1 "False";
VAL_ 950 ObstacleInTrajectory_CHR 0 "True" 1 "False";
VAL_ 950 ObstacleInTrajectory_LHF 0 "True" 1 "False";
VAL_ 950 ObstacleInTrajectory_LHR 0 "True" 1 "False";
VAL_ 950 ObstacleInTrajectory_RHF 0 "True" 1 "False";
VAL_ 950 ObstacleInTrajectory_RHR 0 "True" 1 "False";
VAL_ 1282 Radio_Delete_Request 0 "No_Action" 1 "Delete_Profile_1" 2 "Delete_Profile_2" 3 "Delete_Profile_3" 4 "Delete_Profile_4" 5 "Delete_Profile_5" 6 "Delete_All" 7 "SNA";
VAL_ 1282 Radio_Profile_Request 0 "No_Action" 1 "Profile_1" 2 "Profile_2" 3 "Profile_3" 4 "Profile_4" 5 "Profile_5" 6 "Profile_6" 7 "SNA";
